VERSION "HNNBNNNYNNNNNNNNNNNNNNNNNNNNNNNNNNNNNNNNNN/4/%%%/4/'%**4NNN///"

NS_ :

BS_:

BU_: BAP_Tester Gateway_Max Getriebe_DQ Motor_konv Parksperre Schaltbetaetigung

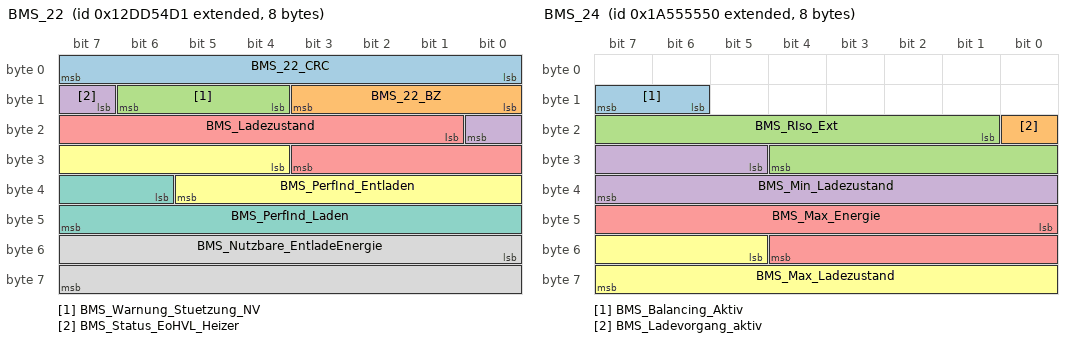
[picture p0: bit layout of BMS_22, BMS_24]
BO_ 2463978705 BMS_22: 8 Gateway_Max
 SG_ BMS_22_CRC : 0|8@1+ (1,0) [0|255] ""  Vector__XXX
 SG_ BMS_22_BZ : 8|4@1+ (1,0) [0|15] ""  Vector__XXX
 SG_ BMS_Warnung_Stuetzung_NV : 12|3@1+ (1.0,0.0) [0.0|7] ""  Vector__XXX
 SG_ BMS_Status_EoHVL_Heizer : 15|2@1+ (1.0,0.0) [0.0|3] ""  Vector__XXX
 SG_ BMS_Ladezustand : 17|11@1+ (0.05,0) [0.00|100.00] "Unit_PerCent"  Vector__XXX
 SG_ BMS_PerfInd_Entladen : 28|10@1+ (0.2,0) [0.0|200.0] "Unit_PerCent"  Vector__XXX
 SG_ BMS_PerfInd_Laden : 38|10@1+ (0.2,0) [0.0|200.0] "Unit_PerCent"  Vector__XXX
 SG_ BMS_Nutzbare_EntladeEnergie : 48|16@1+ (5,0) [0|327400] "Unit_WattHour"  Vector__XXX

BO_ 2589283664 BMS_24: 8 Gateway_Max
 SG_ BMS_Balancing_Aktiv : 14|2@1+ (1.0,0.0) [0.0|3] ""  Vector__XXX
 SG_ BMS_Ladevorgang_aktiv : 16|1@1+ (1.0,0.0) [0.0|1] ""  Vector__XXX
 SG_ BMS_RIso_Ext : 17|12@1+ (5,0) [0|20465] "Unit_KiloOhm"  Vector__XXX
 SG_ BMS_Min_Ladezustand : 29|11@1+ (0.05,0) [0.00|100.00] "Unit_PerCent"  Vector__XXX
 SG_ BMS_Max_Energie : 40|13@1+ (40,0) [0|327400] "Unit_WattHour"  Vector__XXX
 SG_ BMS_Max_Ladezustand : 53|11@1+ (0.05,0) [0.00|100.00] "Unit_PerCent"  Vector__XXX

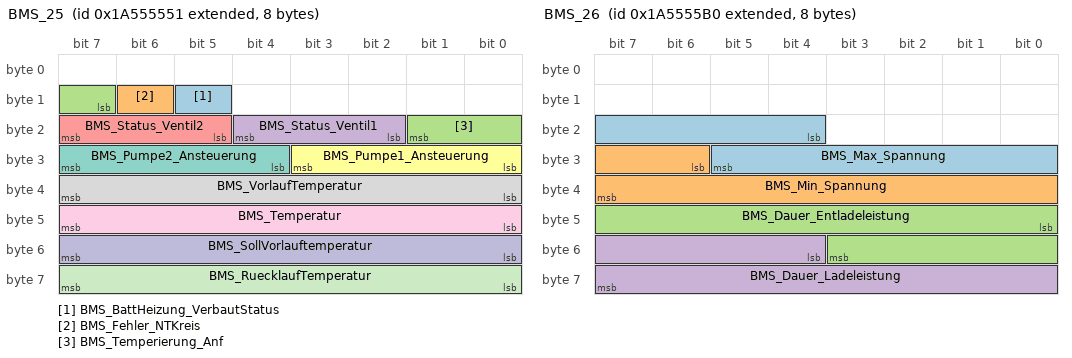
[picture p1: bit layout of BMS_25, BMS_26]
BO_ 2589283665 BMS_25: 8 Gateway_Max
 SG_ BMS_BattHeizung_VerbautStatus : 13|1@1+ (1.0,0.0) [0.0|1] ""  Vector__XXX
 SG_ BMS_Fehler_NTKreis : 14|1@1+ (1.0,0.0) [0.0|1] ""  Vector__XXX
 SG_ BMS_Temperierung_Anf : 15|3@1+ (1.0,0.0) [0.0|7] ""  Vector__XXX
 SG_ BMS_Status_Ventil1 : 18|3@1+ (1.0,0.0) [0.0|7] ""  Vector__XXX
 SG_ BMS_Status_Ventil2 : 21|3@1+ (1.0,0.0) [0.0|7] ""  Vector__XXX
 SG_ BMS_Pumpe1_Ansteuerung : 24|4@1+ (10,0) [0|100] "Unit_PerCent"  Vector__XXX
 SG_ BMS_Pumpe2_Ansteuerung : 28|4@1+ (10,0) [0|100] "Unit_PerCent"  Vector__XXX
 SG_ BMS_VorlaufTemperatur : 32|8@1+ (0.5,-40) [-40.0|86.0] "Unit_DegreCelsi"  Vector__XXX
 SG_ BMS_Temperatur : 40|8@1+ (0.5,-40) [-40.0|86.5] "Unit_DegreCelsi"  Vector__XXX
 SG_ BMS_SollVorlauftemperatur : 48|8@1+ (0.5,-40) [-40.0|86.5] "Unit_DegreCelsi"  Vector__XXX
 SG_ BMS_RuecklaufTemperatur : 56|8@1+ (0.5,-40) [-40.0|86.0] "Unit_DegreCelsi"  Vector__XXX

BO_ 2589283760 BMS_26: 8 Gateway_Max
 SG_ BMS_Max_Spannung : 20|10@1+ (1,0) [0|1000] "Unit_Volt"  Vector__XXX
 SG_ BMS_Min_Spannung : 30|10@1+ (1,0) [0|1000] "Unit_Volt"  Vector__XXX
 SG_ BMS_Dauer_Entladeleistung : 40|12@1+ (200,0) [0|818000] "Unit_Watt"  Vector__XXX
 SG_ BMS_Dauer_Ladeleistung : 52|12@1+ (200,0) [0|818000] "Unit_Watt"  Vector__XXX

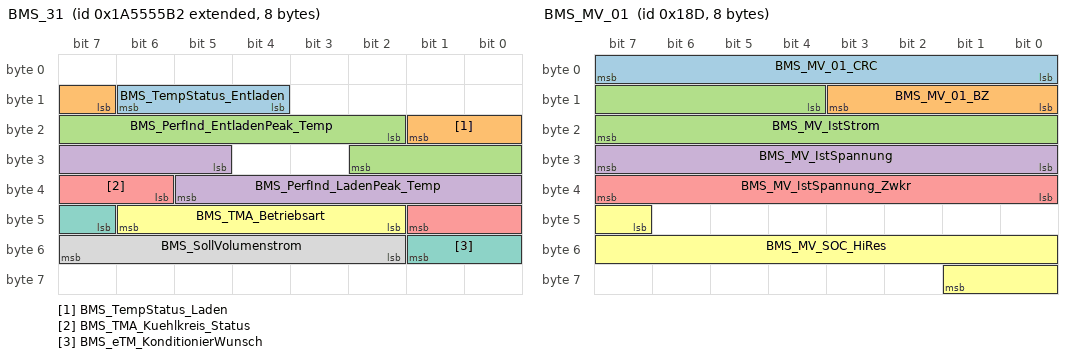
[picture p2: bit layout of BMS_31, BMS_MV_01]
BO_ 2589283762 BMS_31: 8 Gateway_Max
 SG_ BMS_TempStatus_Entladen : 12|3@1+ (1.0,0.0) [0.0|7] ""  Vector__XXX
 SG_ BMS_TempStatus_Laden : 15|3@1+ (1.0,0.0) [0.0|7] ""  Vector__XXX
 SG_ BMS_PerfInd_EntladenPeak_Temp : 18|9@1+ (0.2,0) [0.0|100.0] "Unit_PerCent"  Vector__XXX
 SG_ BMS_PerfInd_LadenPeak_Temp : 29|9@1+ (0.2,0) [0.0|100.0] "Unit_PerCent"  Vector__XXX
 SG_ BMS_TMA_Kuehlkreis_Status : 38|4@1+ (1.0,0.0) [0.0|15] ""  Vector__XXX
 SG_ BMS_TMA_Betriebsart : 42|5@1+ (1.0,0.0) [0.0|31] ""  Vector__XXX
 SG_ BMS_eTM_KonditionierWunsch : 47|3@1+ (1.0,0.0) [0.0|7] ""  Vector__XXX
 SG_ BMS_SollVolumenstrom : 50|6@1+ (1,0) [0|61] "Unit_LiterPerMinut"  Vector__XXX

BO_ 2331595856 BMS_34: 32 Gateway_Max
 SG_ BMS_UBE : 16|16@1+ (5,-7400) [-7400|320000] "Unit_WattHour"  Vector__XXX
 SG_ BMS_UBE_T : 32|16@1+ (5,-7400) [-7400|320000] "Unit_WattHour"  Vector__XXX
 SG_ BMS_Max_UBE : 48|16@1+ (5,-7400) [-7400|320000] "Unit_WattHour"  Vector__XXX
 SG_ BMS_Nennspannung : 64|11@1+ (0.5,0) [0.0|1000.0] "Unit_Volt"  Vector__XXX
 SG_ BMS_DC_Ladeschuetze_Ist : 75|3@1+ (1.0,0.0) [0.0|7] ""  Vector__XXX
 SG_ BMS_Hauptschuetze_Ist : 78|3@1+ (1.0,0.0) [0.0|7] ""  Vector__XXX
 SG_ BMS_UBE_Indikator : 81|11@1+ (0.05,0) [0.00|100.00] "Unit_PerCent"  Vector__XXX
 SG_ BMS_UBE_Indik_last_update_km : 92|20@1+ (1,0) [0|1000000] "Unit_KiloMeter"  Vector__XXX
 SG_ BMS_Last_Chg_adeq_SOCswing_Day : 112|5@1+ (1,0) [1|31] "Unit_Day"  Vector__XXX
 SG_ BMS_Last_Chg_adeq_SOCswing_Month : 117|4@1+ (1,0) [1|12] "Unit_Month"  Vector__XXX
 SG_ BMS_Last_Chg_adeq_SOCswing_Year : 121|7@1+ (1,2000) [2001|2127] "Unit_Year"  Vector__XXX
 SG_ BMS_EnergieVorhalt : 128|16@1+ (0.1,0) [0.0|6400.0] "Unit_KiloWattHour"  Vector__XXX
 SG_ BMS_Range_Indikator : 144|11@1+ (0.05,0) [0.00|100.00] "Unit_PerCent"  Vector__XXX
 SG_ SOK_BMS_34_Signatur : 192|64@1+ (1,0) [1|18446744073709551615] "Unit_None"  Vector__XXX

BO_ 397 BMS_MV_01: 8 Gateway_Max
 SG_ BMS_MV_01_CRC : 0|8@1+ (1,0) [0|255] ""  Vector__XXX
 SG_ BMS_MV_01_BZ : 8|4@1+ (1,0) [0|15] ""  Vector__XXX
 SG_ BMS_MV_IstStrom : 12|12@1+ (1,-2047) [-2047|2046] "Unit_Amper"  Motor_konv
 SG_ BMS_MV_IstSpannung : 24|8@1+ (0.25,0) [0.00|63.25] "Unit_Volt"  Motor_konv
 SG_ BMS_MV_IstSpannung_Zwkr : 32|8@1+ (0.25,0) [0.00|63.25] "Unit_Volt"  Vector__XXX
 SG_ BMS_MV_SOC_HiRes : 47|11@1+ (0.05,0) [0.00|100.00] "Unit_PerCent"  Motor_konv

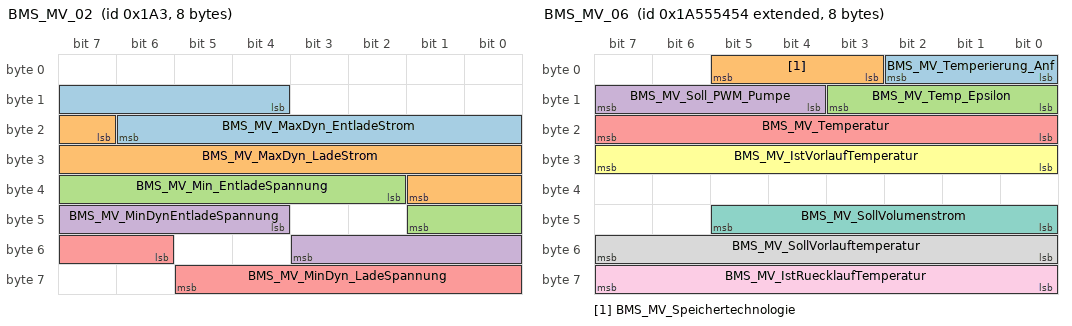
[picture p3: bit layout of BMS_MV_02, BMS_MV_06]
BO_ 419 BMS_MV_02: 8 Gateway_Max
 SG_ BMS_MV_MaxDyn_EntladeStrom : 12|11@1+ (1,0) [0|2045] "Unit_Amper"  Motor_konv
 SG_ BMS_MV_MaxDyn_LadeStrom : 23|11@1+ (1,0) [0|2045] "Unit_Amper"  Motor_konv
 SG_ BMS_MV_Min_EntladeSpannung : 34|8@1+ (0.25,0) [0.00|63.25] "Unit_Volt"  Vector__XXX
 SG_ BMS_MV_MinDynEntladeSpannung : 44|8@1+ (0.25,0) [0.00|63.25] "Unit_Volt"  Vector__XXX
 SG_ BMS_MV_MinDyn_LadeSpannung : 54|8@1+ (0.25,0) [0.00|63.25] "Unit_Volt"  Vector__XXX

BO_ 2589283412 BMS_MV_06: 8 Gateway_Max
 SG_ BMS_MV_Temperierung_Anf : 0|3@1+ (1.0,0.0) [0.0|7] ""  Vector__XXX
 SG_ BMS_MV_Speichertechnologie : 3|3@1+ (1.0,0.0) [0.0|7] ""  Vector__XXX
 SG_ BMS_MV_Temp_Epsilon : 8|4@1+ (1,-15) [-15|0] "Unit_DegreCelsi"  Vector__XXX
 SG_ BMS_MV_Soll_PWM_Pumpe : 12|4@1+ (10,0) [0|100] "Unit_PerCent"  Vector__XXX
 SG_ BMS_MV_Temperatur : 16|8@1+ (0.5,-40) [-40.0|86.5] "Unit_DegreCelsi"  Motor_konv
 SG_ BMS_MV_IstVorlaufTemperatur : 24|8@1+ (0.5,-40) [-40.0|86.5] "Unit_DegreCelsi"  Vector__XXX
 SG_ BMS_MV_SollVolumenstrom : 40|6@1+ (1,0) [0|61] ""  Vector__XXX
 SG_ BMS_MV_SollVorlauftemperatur : 48|8@1+ (0.5,-40) [-40.0|86.5] "Unit_DegreCelsi"  Vector__XXX
 SG_ BMS_MV_IstRuecklaufTemperatur : 56|8@1+ (0.5,-40) [-40.0|86.5] "Unit_DegreCelsi"  Vector__XXX

BO_ 2589283608 BMS_MV_07: 8 Gateway_Max
 SG_ BMS_MV_Energieinhalt : 12|11@1+ (1,0) [0|2045] "Unit_WattHour"  Motor_konv
 SG_ BMS_MV_MaxEnergieinhalt : 32|11@1+ (1,0) [0|2045] "Unit_WattHour"  Motor_konv

BO_ 2589283606 BMS_MV_09: 8 Gateway_Max
 SG_ BMS_MV_SOC_Kaltstart : 43|11@1+ (0.05,0) [0.00|100.00] "Unit_PerCent"  Motor_konv
 SG_ BMS_MV_max_Grenz_SOC : 54|5@1+ (1,70) [70|100] "Unit_PerCent"  Motor_konv

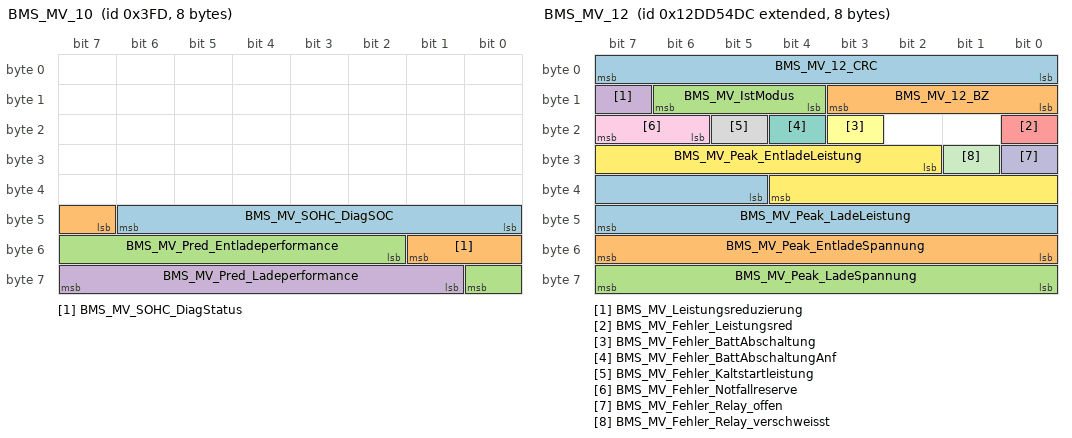
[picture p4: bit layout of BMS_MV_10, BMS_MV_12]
BO_ 1021 BMS_MV_10: 8 Gateway_Max
 SG_ BMS_MV_SOHC_DiagSOC : 40|7@1+ (1,0) [0|100] "Unit_PerCent"  Motor_konv
 SG_ BMS_MV_SOHC_DiagStatus : 47|3@1+ (1.0,0.0) [0.0|7] ""  Motor_konv
 SG_ BMS_MV_Pred_Entladeperformance : 50|7@1+ (1,0) [0|100] "Unit_PerCent"  Motor_konv
 SG_ BMS_MV_Pred_Ladeperformance : 57|7@1+ (1,0) [0|100] "Unit_PerCent"  Motor_konv

BO_ 2463978716 BMS_MV_12: 8 Gateway_Max
 SG_ BMS_MV_12_CRC : 0|8@1+ (1,0) [0|255] ""  Vector__XXX
 SG_ BMS_MV_12_BZ : 8|4@1+ (1,0) [0|15] ""  Vector__XXX
 SG_ BMS_MV_IstModus : 12|3@1+ (1.0,0.0) [0.0|7] ""  Vector__XXX
 SG_ BMS_MV_Leistungsreduzierung : 15|1@1+ (1.0,0.0) [0.0|1] ""  Motor_konv
 SG_ BMS_MV_Fehler_Leistungsred : 16|1@1+ (1.0,0.0) [0.0|1] ""  Motor_konv
 SG_ BMS_MV_Fehler_BattAbschaltung : 19|1@1+ (1.0,0.0) [0.0|1] ""  Vector__XXX
 SG_ BMS_MV_Fehler_BattAbschaltungAnf : 20|1@1+ (1.0,0.0) [0.0|1] ""  Vector__XXX
 SG_ BMS_MV_Fehler_Kaltstartleistung : 21|1@1+ (1.0,0.0) [0.0|1] ""  Vector__XXX
 SG_ BMS_MV_Fehler_Notfallreserve : 22|2@1+ (1.0,0.0) [0.0|3] ""  Vector__XXX
 SG_ BMS_MV_Fehler_Relay_offen : 24|1@1+ (1.0,0.0) [0.0|1] ""  Vector__XXX
 SG_ BMS_MV_Fehler_Relay_verschweisst : 25|1@1+ (1.0,0.0) [0.0|1] ""  Vector__XXX
 SG_ BMS_MV_Peak_EntladeLeistung : 26|11@1+ (50,0) [0|102250] "Unit_Watt"  Vector__XXX
 SG_ BMS_MV_Peak_LadeLeistung : 37|11@1+ (50,0) [0|102250] "Unit_Watt"  Vector__XXX
 SG_ BMS_MV_Peak_EntladeSpannung : 48|8@1+ (0.25,0) [0.00|63.25] "Unit_Volt"  Vector__XXX
 SG_ BMS_MV_Peak_LadeSpannung : 56|8@1+ (0.25,0) [0.00|63.25] "Unit_Volt"  Vector__XXX

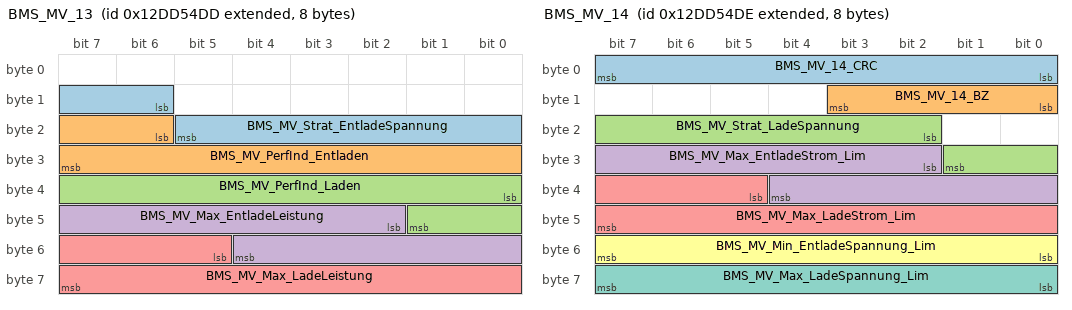
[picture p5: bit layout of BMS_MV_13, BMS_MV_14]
BO_ 2463978717 BMS_MV_13: 8 Gateway_Max
 SG_ BMS_MV_Strat_EntladeSpannung : 14|8@1+ (0.25,0) [0.00|63.25] "Unit_Volt"  Vector__XXX
 SG_ BMS_MV_PerfInd_Entladen : 22|10@1+ (0.2,0) [0.0|200.0] "Unit_PerCent"  Motor_konv
 SG_ BMS_MV_PerfInd_Laden : 32|10@1+ (0.2,0) [0.0|200.0] "Unit_PerCent"  Motor_konv
 SG_ BMS_MV_Max_EntladeLeistung : 42|11@1+ (50,0) [0|102250] "Unit_Watt"  Motor_konv
 SG_ BMS_MV_Max_LadeLeistung : 53|11@1+ (50,0) [0|102250] "Unit_Watt"  Motor_konv

BO_ 2463978718 BMS_MV_14: 8 Gateway_Max
 SG_ BMS_MV_14_CRC : 0|8@1+ (1,0) [0|255] ""  Vector__XXX
 SG_ BMS_MV_14_BZ : 8|4@1+ (1,0) [0|15] ""  Vector__XXX
 SG_ BMS_MV_Strat_LadeSpannung : 18|8@1+ (0.25,0) [0.00|63.25] "Unit_Volt"  Vector__XXX
 SG_ BMS_MV_Max_EntladeStrom_Lim : 26|11@1+ (1,0) [0|2045] "Unit_Amper"  Motor_konv
 SG_ BMS_MV_Max_LadeStrom_Lim : 37|11@1+ (1,0) [0|2045] "Unit_Amper"  Motor_konv
 SG_ BMS_MV_Min_EntladeSpannung_Lim : 48|8@1+ (0.25,0) [0.00|63.25] "Unit_Volt"  Motor_konv
 SG_ BMS_MV_Max_LadeSpannung_Lim : 56|8@1+ (0.25,0) [0.00|63.25] "Unit_Volt"  Motor_konv

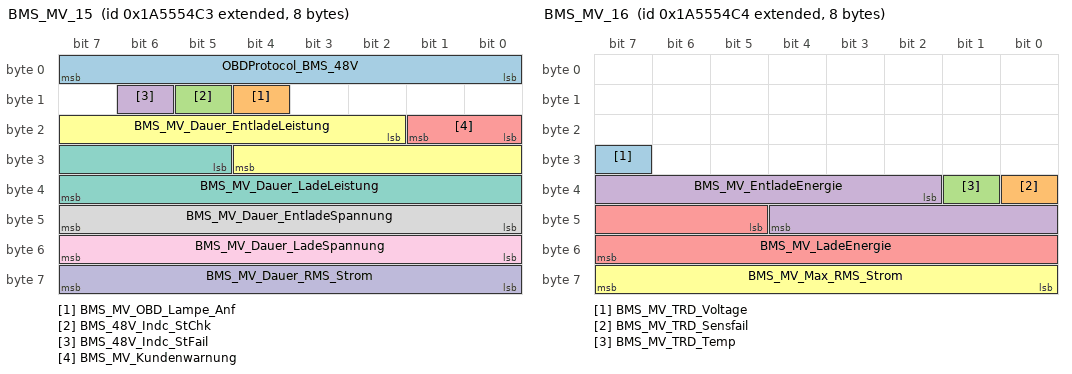
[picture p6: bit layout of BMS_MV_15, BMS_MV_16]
BO_ 2589283523 BMS_MV_15: 8 Gateway_Max
 SG_ OBDProtocol_BMS_48V : 0|8@1+ (1.0,0.0) [0.0|255] ""  Motor_konv
 SG_ BMS_MV_OBD_Lampe_Anf : 12|1@1+ (1.0,0.0) [0.0|1] ""  Motor_konv
 SG_ BMS_48V_Indc_StChk : 13|1@1+ (1.0,0.0) [0.0|1] ""  Motor_konv
 SG_ BMS_48V_Indc_StFail : 14|1@1+ (1.0,0.0) [0.0|1] ""  Motor_konv
 SG_ BMS_MV_Kundenwarnung : 16|2@1+ (1.0,0.0) [0.0|3] ""  Vector__XXX
 SG_ BMS_MV_Dauer_EntladeLeistung : 18|11@1+ (50,0) [0|102250] "Unit_Watt"  Motor_konv
 SG_ BMS_MV_Dauer_LadeLeistung : 29|11@1+ (50,0) [0|102250] "Unit_Watt"  Motor_konv
 SG_ BMS_MV_Dauer_EntladeSpannung : 40|8@1+ (0.25,0) [0.00|63.25] "Unit_Volt"  Vector__XXX
 SG_ BMS_MV_Dauer_LadeSpannung : 48|8@1+ (0.25,0) [0.00|63.25] "Unit_Volt"  Vector__XXX
 SG_ BMS_MV_Dauer_RMS_Strom : 56|8@1+ (1,0) [0|253] "Unit_Amper"  Motor_konv

BO_ 2589283543 BMS_MV_15_SOK_Signatur: 8 Gateway_Max
 SG_ SOK_BMS_MV_15_Signatur : 0|64@1+ (1,0) [1|18446744073709551615] "Unit_None"  Motor_konv

BO_ 2589283524 BMS_MV_16: 8 Gateway_Max
 SG_ BMS_MV_TRD_Voltage : 31|1@1+ (1.0,0.0) [0.0|1] ""  Vector__XXX
 SG_ BMS_MV_TRD_Sensfail : 32|1@1+ (1.0,0.0) [0.0|1] ""  Vector__XXX
 SG_ BMS_MV_TRD_Temp : 33|1@1+ (1.0,0.0) [0.0|1] ""  Vector__XXX
 SG_ BMS_MV_EntladeEnergie : 34|11@1+ (5,-5110) [-5110|5115] "Unit_WattHour"  Motor_konv
 SG_ BMS_MV_LadeEnergie : 45|11@1+ (5,-5110) [-5110|5115] "Unit_WattHour"  Motor_konv
 SG_ BMS_MV_Max_RMS_Strom : 56|8@1+ (1,0) [0|253] "Unit_Amper"  Motor_konv

BO_ 2527679928 BMS_NV_11: 16 Gateway_Max
 SG_ BMS_NV_OBD_Lampe_Anf : 12|1@1+ (1.0,0.0) [0.0|1] ""  Motor_konv
 SG_ BMS_NV_Indc_StChk : 13|1@1+ (1.0,0.0) [0.0|1] ""  Motor_konv
 SG_ BMS_NV_Indc_StFail : 14|1@1+ (1.0,0.0) [0.0|1] ""  Motor_konv
 SG_ OBDProtocol_BMS_NV : 16|8@1+ (1.0,0.0) [0.0|255] ""  Motor_konv
 SG_ SOK_BMS_NV_11_Signatur : 64|64@1+ (1,0) [1|18446744073709551615] "Unit_None"  Motor_konv

BO_ 2463978646 Charisma_11: 24 Gateway_Max
 SG_ CHA_Ziel_FahrPr_AGA : 0|4@1+ (1.0,0.0) [0.0|15] ""  Vector__XXX
 SG_ CHA_Ziel_FahrPr_ESP : 4|4@1+ (1.0,0.0) [0.0|15] ""  Vector__XXX
 SG_ CHA_Ziel_FahrPr_Freilauf : 8|4@1+ (1.0,0.0) [0.0|15] ""  Vector__XXX
 SG_ CHA_Fahrer_Umschaltung : 14|1@1+ (1.0,0.0) [0.0|1] ""  Getriebe_DQ,Motor_konv
 SG_ CHA_Fahrer_Umschaltung_BMA : 15|1@1+ (1.0,0.0) [0.0|1] ""  Vector__XXX
 SG_ CHA_Ziel_FahrPr_MO : 16|4@1+ (1.0,0.0) [0.0|15] ""  Motor_konv
 SG_ CHA_Ziel_FahrPr_GE : 20|4@1+ (1.0,0.0) [0.0|15] ""  Getriebe_DQ
 SG_ CHA_Ziel_FahrPr_ALR : 24|4@1+ (1.0,0.0) [0.0|15] ""  Vector__XXX
 SG_ CHA_Ziel_FahrPr_MO_BZS : 28|4@1+ (1.0,0.0) [0.0|15] ""  Motor_konv
 SG_ CHA_Ziel_FahrPr_DR : 32|4@1+ (1.0,0.0) [0.0|15] ""  Vector__XXX
 SG_ CHA_Ziel_FahrPr_VAQ : 36|4@1+ (1.0,0.0) [0.0|15] ""  Vector__XXX
 SG_ CHA_Ziel_FahrPr_AFS : 40|4@1+ (1.0,0.0) [0.0|15] ""  Vector__XXX
 SG_ CHA_Ziel_FahrPr_PreCrash : 44|4@1+ (1.0,0.0) [0.0|15] ""  Vector__XXX
 SG_ CHA_Ziel_FahrPr_EPS : 48|4@1+ (1.0,0.0) [0.0|15] ""  Vector__XXX
 SG_ CHA_Ziel_FahrPr_ACC : 52|4@1+ (1.0,0.0) [0.0|15] ""  Vector__XXX
 SG_ CHA_Ziel_FahrPr_SAK : 56|4@1+ (1.0,0.0) [0.0|15] ""  Motor_konv
 SG_ CHA_Ziel_FahrPr_MO_StSt : 60|4@1+ (1.0,0.0) [0.0|15] ""  Motor_konv
 SG_ CHA_Ziel_FahrPr_EBKV : 64|4@1+ (1.0,0.0) [0.0|15] ""  Vector__XXX
 SG_ CHA_Ziel_FahrPr_IL : 68|4@1+ (1.0,0.0) [0.0|15] ""  Vector__XXX
 SG_ CHA_Current_Mode : 72|4@1+ (1.0,0.0) [0.0|15] ""  Vector__XXX
 SG_ CHA_Ziel_FahrPr_QS : 80|4@1+ (1.0,0.0) [0.0|15] ""  Vector__XXX
 SG_ CHA_Ziel_FahrPr_SCU : 84|4@1+ (1.0,0.0) [0.0|15] ""  Vector__XXX
 SG_ CHA_Ziel_FahrPr_HAL : 88|4@1+ (1.0,0.0) [0.0|15] ""  Vector__XXX
 SG_ CHA_Ziel_FahrPr_NR : 92|4@1+ (1.0,0.0) [0.0|15] ""  Vector__XXX
 SG_ CHA_Ziel_FahrPr_AV : 96|4@1+ (1.0,0.0) [0.0|15] ""  Vector__XXX
 SG_ CHA_Ziel_FahrPr_MXB : 100|4@1+ (1.0,0.0) [0.0|15] ""  Vector__XXX
 SG_ CHA_Ziel_FahrPr_AFR : 104|4@1+ (1.0,0.0) [0.0|15] ""  Vector__XXX
 SG_ CHA_Ziel_FahrPr_HDC : 108|4@1+ (1.0,0.0) [0.0|15] ""  Vector__XXX
 SG_ CHA_Ziel_FahrPr_EAR : 112|4@1+ (1.0,0.0) [0.0|15] ""  Vector__XXX
 SG_ CHA_Ziel_FahrPr_AEB : 116|4@1+ (1.0,0.0) [0.0|15] ""  Vector__XXX
 SG_ CHA_Ziel_FahrPr_FCWO : 120|4@1+ (1.0,0.0) [0.0|15] ""  Vector__XXX
 SG_ CHA_Ziel_FahrPr_FCWP : 124|4@1+ (1.0,0.0) [0.0|15] ""  Vector__XXX
 SG_ CHA_Ziel_FahrPr_eSound : 136|4@1+ (1.0,0.0) [0.0|15] ""  Vector__XXX
 SG_ CHA_Ziel_FahrPr_RHP : 140|4@1+ (1.0,0.0) [0.0|15] ""  Vector__XXX
 SG_ CHA_Ziel_FahrPr_ToS_laengs : 144|4@1+ (1.0,0.0) [0.0|15] ""  Vector__XXX
 SG_ CHA_Ziel_FahrPr_ToS_quer : 148|4@1+ (1.0,0.0) [0.0|15] ""  Vector__XXX
 SG_ CHA_Ziel_FahrPr_mFDR : 152|4@1+ (1.0,0.0) [0.0|15] ""  Vector__XXX
 SG_ CHA_Ziel_FahrPr_Reku_ZwGas : 156|4@1+ (1.0,0.0) [0.0|15] ""  Vector__XXX
 SG_ CHA_Ziel_FahrPr_MO_Freilauf : 160|4@1+ (1.0,0.0) [0.0|15] ""  Vector__XXX
 SG_ CHA_Ziel_FahrPr_BMS : 164|4@1+ (1.0,0.0) [0.0|15] ""  Vector__XXX
 SG_ CHA_Ziel_FahrPr_PDC : 172|4@1+ (1.0,0.0) [0.0|15] ""  Vector__XXX
 SG_ CHA_Ziel_FahrPr_HHC : 176|4@1+ (1.0,0.0) [0.0|15] ""  Vector__XXX
 SG_ CHA_Ziel_FahrPr_EDS : 180|4@1+ (1.0,0.0) [0.0|15] ""  Vector__XXX
 SG_ CHA_Ziel_FahrPr_PACC : 184|4@1+ (1.0,0.0) [0.0|15] ""  Vector__XXX
 SG_ CHA_Ziel_FahrPr_AGK : 188|4@1+ (1.0,0.0) [0.0|15] ""  Motor_konv

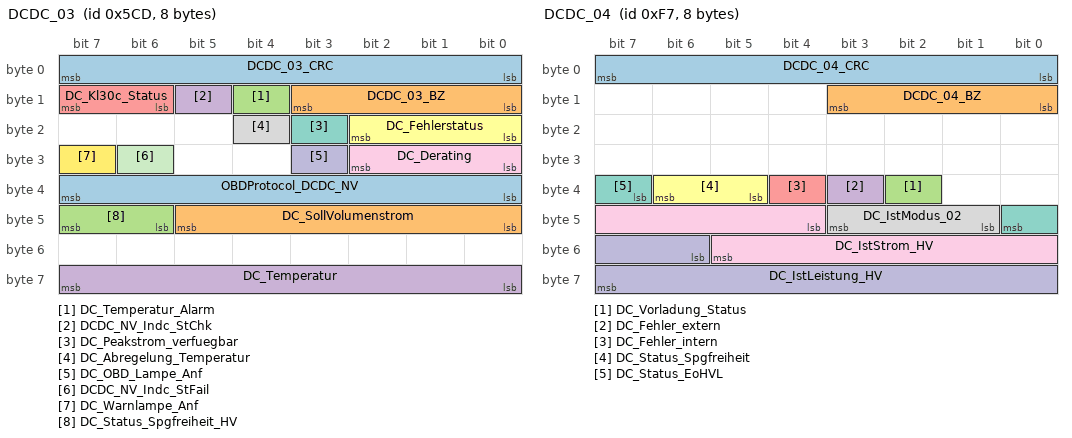
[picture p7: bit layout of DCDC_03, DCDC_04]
BO_ 1485 DCDC_03: 8 Gateway_Max
 SG_ DCDC_03_CRC : 0|8@1+ (1,0) [0|255] ""  Vector__XXX
 SG_ DCDC_03_BZ : 8|4@1+ (1,0) [0|15] ""  Vector__XXX
 SG_ DC_Temperatur_Alarm : 12|1@1+ (1.0,0.0) [0.0|1] ""  Vector__XXX
 SG_ DCDC_NV_Indc_StChk : 13|1@1+ (1.0,0.0) [0.0|1] ""  Vector__XXX
 SG_ DC_Kl30c_Status : 14|2@1+ (1.0,0.0) [0.0|3] ""  Vector__XXX
 SG_ DC_Fehlerstatus : 16|3@1+ (1.0,0.0) [0.0|7] ""  Vector__XXX
 SG_ DC_Peakstrom_verfuegbar : 19|1@1+ (1.0,0.0) [0.0|1] ""  Vector__XXX
 SG_ DC_Abregelung_Temperatur : 20|1@1+ (1.0,0.0) [0.0|1] ""  Vector__XXX
 SG_ DC_Derating : 24|3@1+ (1.0,0.0) [0.0|7] ""  Vector__XXX
 SG_ DC_OBD_Lampe_Anf : 27|1@1+ (1.0,0.0) [0.0|1] ""  Vector__XXX
 SG_ DCDC_NV_Indc_StFail : 30|1@1+ (1.0,0.0) [0.0|1] ""  Vector__XXX
 SG_ DC_Warnlampe_Anf : 31|1@1+ (1.0,0.0) [0.0|1] ""  Vector__XXX
 SG_ OBDProtocol_DCDC_NV : 32|8@1+ (1.0,0.0) [0.0|255] ""  Vector__XXX
 SG_ DC_SollVolumenstrom : 40|6@1+ (0.5,0) [0.0|30.5] "Unit_LiterPerMinut"  Vector__XXX
 SG_ DC_Status_Spgfreiheit_HV : 46|2@1+ (1.0,0.0) [0.0|3] ""  Vector__XXX
 SG_ DC_Temperatur : 56|8@1+ (1,-40) [-40|213] "Unit_DegreCelsi"  Vector__XXX

BO_ 1486 DCDC_03_SOK_Signatur: 8 Gateway_Max
 SG_ SOK_DCDC_03_Signatur : 0|64@1+ (1,0) [1|18446744073709551615] "Unit_None"  Vector__XXX

BO_ 247 DCDC_04: 8 Gateway_Max
 SG_ DCDC_04_CRC : 0|8@1+ (1,0) [0|255] ""  Vector__XXX
 SG_ DCDC_04_BZ : 8|4@1+ (1,0) [0|15] ""  Vector__XXX
 SG_ DC_Vorladung_Status : 34|1@1+ (1.0,0.0) [0.0|1] ""  Vector__XXX
 SG_ DC_Fehler_extern : 35|1@1+ (1.0,0.0) [0.0|1] ""  Vector__XXX
 SG_ DC_Fehler_intern : 36|1@1+ (1.0,0.0) [0.0|1] ""  Vector__XXX
 SG_ DC_Status_Spgfreiheit : 37|2@1+ (1.0,0.0) [0.0|3] ""  Vector__XXX
 SG_ DC_Status_EoHVL : 39|2@1+ (1.0,0.0) [0.0|3] ""  Vector__XXX
 SG_ DC_IstModus_02 : 41|3@1+ (1.0,0.0) [0.0|7] ""  Vector__XXX
 SG_ DC_IstStrom_HV : 44|10@1+ (0.1,-51.1) [-51.1|51.0] "Unit_Amper"  Vector__XXX
 SG_ DC_IstLeistung_HV : 54|10@1+ (10,-4000) [-4000|6210] "Unit_Watt"  Vector__XXX

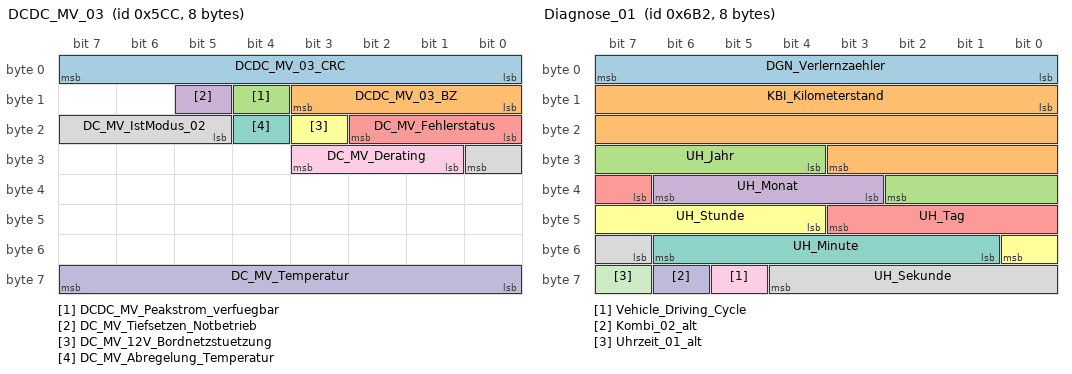
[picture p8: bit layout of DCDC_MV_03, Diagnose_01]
BO_ 1484 DCDC_MV_03: 8 Gateway_Max
 SG_ DCDC_MV_03_CRC : 0|8@1+ (1,0) [0|255] ""  Vector__XXX
 SG_ DCDC_MV_03_BZ : 8|4@1+ (1,0) [0|15] ""  Vector__XXX
 SG_ DCDC_MV_Peakstrom_verfuegbar : 12|1@1+ (1.0,0.0) [0.0|1] ""  Vector__XXX
 SG_ DC_MV_Tiefsetzen_Notbetrieb : 13|1@1+ (1.0,0.0) [0.0|1] ""  Vector__XXX
 SG_ DC_MV_Fehlerstatus : 16|3@1+ (1.0,0.0) [0.0|7] ""  Vector__XXX
 SG_ DC_MV_12V_Bordnetzstuetzung : 19|1@1+ (1.0,0.0) [0.0|1] ""  Vector__XXX
 SG_ DC_MV_Abregelung_Temperatur : 20|1@1+ (1.0,0.0) [0.0|1] ""  Vector__XXX
 SG_ DC_MV_IstModus_02 : 21|4@1+ (1.0,0.0) [0.0|15] ""  Motor_konv
 SG_ DC_MV_Derating : 25|3@1+ (1.0,0.0) [0.0|7] ""  Vector__XXX
 SG_ DC_MV_Temperatur : 56|8@1+ (1,-40) [-40|213] "Unit_DegreCelsi"  Vector__XXX

BO_ 2617227808 DEV_Getriebe_Resp_20: 64 Getriebe_DQ
 SG_ DEV_Getriebe_Resp_20_Data : 0|512@1+ (1.0,0.0) [0.0|13407807929942597099574024998205846127479365820592393377723561443721764030073546976801874298166903427690031858186486050853753882811946569946433649006084095] ""  Vector__XXX

BO_ 2617227809 DEV_Getriebe_Resp_21: 64 Getriebe_DQ
 SG_ DEV_Getriebe_Resp_21_Data : 0|512@1+ (1.0,0.0) [0.0|13407807929942597099574024998205846127479365820592393377723561443721764030073546976801874298166903427690031858186486050853753882811946569946433649006084095] ""  Vector__XXX

BO_ 2566865408 DEV_Parksperre_Resp_00: 8 Parksperre
 SG_ DEV_Parksperre_Resp_00_Data : 0|64@1+ (1.0,0.0) [0.0|18446744073709551615] ""  Vector__XXX

BO_ 2566865663 DEV_Parksperre_Resp_FF: 8 Parksperre
 SG_ DEV_Parksperre_Resp_FF_Data : 0|64@1+ (1.0,0.0) [0.0|18446744073709551615] ""  Vector__XXX

BO_ 2617154048 DEV_Waehlhebel_Resp_00: 8 Schaltbetaetigung
 SG_ DEV_Waehlhebel_Resp_00_Data : 0|64@1+ (1.0,0.0) [0.0|18446744073709551615] ""  Vector__XXX

BO_ 2617154049 DEV_Waehlhebel_Resp_01: 8 Schaltbetaetigung
 SG_ DEV_Waehlhebel_Resp_01_Data : 0|64@1+ (1.0,0.0) [0.0|18446744073709551615] ""  Vector__XXX

BO_ 2617154050 DEV_Waehlhebel_Resp_02: 8 Schaltbetaetigung
 SG_ DEV_Waehlhebel_Resp_02_Data : 0|64@1+ (1.0,0.0) [0.0|18446744073709551615] ""  Vector__XXX

BO_ 2617154051 DEV_Waehlhebel_Resp_03: 8 Schaltbetaetigung
 SG_ DEV_Waehlhebel_Resp_03_Data : 0|64@1+ (1.0,0.0) [0.0|18446744073709551615] ""  Vector__XXX

BO_ 2617154052 DEV_Waehlhebel_Resp_04: 8 Schaltbetaetigung
 SG_ DEV_Waehlhebel_Resp_04_Data : 0|64@1+ (1.0,0.0) [0.0|18446744073709551615] ""  Vector__XXX

BO_ 2617154053 DEV_Waehlhebel_Resp_05: 8 Schaltbetaetigung
 SG_ DEV_Waehlhebel_Resp_05_Data : 0|64@1+ (1.0,0.0) [0.0|18446744073709551615] ""  Vector__XXX

BO_ 2549880589 DIA_eBooster_Req: 8 Gateway_Max
 SG_ DIA_eBooster_Req_Data : 0|64@1+ (1.0,0.0) [0.0|18446744073709551615] ""  Vector__XXX

BO_ 2550011661 DIA_eBooster_Resp: 8 Vector__XXX
 SG_ DIA_eBooster_Resp_Data : 0|64@1+ (1.0,0.0) [0.0|18446744073709551615] ""  Gateway_Max

BO_ 2549880644 DIA_EKAT_Req: 8 Gateway_Max
 SG_ DIA_EKAT_Req_Data : 0|64@1+ (1.0,0.0) [0.0|18446744073709551615] ""  Vector__XXX

BO_ 2550011716 DIA_EKAT_Resp: 8 Vector__XXX
 SG_ DIA_EKAT_Resp_Data : 0|64@1+ (1.0,0.0) [0.0|18446744073709551615] ""  Gateway_Max

BO_ 2549880568 DIA_MTFP_Req: 8 Gateway_Max
 SG_ DIA_MTFP_Req_Data : 0|64@1+ (1.0,0.0) [0.0|18446744073709551615] ""  Vector__XXX

BO_ 2550011640 DIA_MTFP_Resp: 8 Vector__XXX
 SG_ DIA_MTFP_Resp_Data : 0|64@1+ (1.0,0.0) [0.0|18446744073709551615] ""  Gateway_Max

BO_ 2549880642 DIA_Parksperre_Req: 8 Gateway_Max
 SG_ DIA_Parksperre_Req_Data : 0|64@1+ (1.0,0.0) [0.0|18446744073709551615] ""  Parksperre

BO_ 2621445954 DIA_Parksperre_Req_FD: 64 Gateway_Max
 SG_ DIA_Parksperre_Req_FD_Data : 0|512@1+ (1.0,0.0) [0.0|13407807929942597099574024998205846127479365820592393377723561443721764030073546976801874298166903427690031858186486050853753882811946569946433649006084095] ""  Parksperre

BO_ 2550011714 DIA_Parksperre_Resp: 8 Parksperre
 SG_ DIA_Parksperre_Resp_Data : 0|64@1+ (1.0,0.0) [0.0|18446744073709551615] ""  Gateway_Max

BO_ 2621577026 DIA_Parksperre_Resp_FD: 64 Parksperre
 SG_ DIA_Parksperre_Resp_FD_Data : 0|512@1+ (1.0,0.0) [0.0|13407807929942597099574024998205846127479365820592393377723561443721764030073546976801874298166903427690031858186486050853753882811946569946433649006084095] ""  Gateway_Max

BO_ 2549876546 Diag_Parksperre_Req: 8 Getriebe_DQ
 SG_ Diag_Parksperre_Req_Data : 0|64@1+ (1.0,0.0) [0.0|18446744073709551615] ""  Parksperre

BO_ 2550007618 Diag_Parksperre_Resp: 8 Parksperre
 SG_ Diag_Parksperre_Resp_Data : 0|64@1+ (1.0,0.0) [0.0|18446744073709551615] ""  Getriebe_DQ

BO_ 2549876269 Diag_Waehlhebel_Req: 8 Getriebe_DQ
 SG_ Diag_Waehlhebel_Req_Data : 0|64@1+ (1.0,0.0) [0.0|18446744073709551615] ""  Schaltbetaetigung

BO_ 2550007341 Diag_Waehlhebel_Resp: 8 Schaltbetaetigung
 SG_ Diag_Waehlhebel_Resp_Data : 0|64@1+ (1.0,0.0) [0.0|18446744073709551615] ""  Getriebe_DQ

BO_ 1714 Diagnose_01: 8 Gateway_Max
 SG_ DGN_Verlernzaehler : 0|8@1+ (1,0) [0|254] ""  Getriebe_DQ
 SG_ KBI_Kilometerstand : 8|20@1+ (1,0) [0|1048573] "Unit_KiloMeter"  Getriebe_DQ,Motor_konv
 SG_ UH_Jahr : 28|7@1+ (1,2000) [2000|2127] "Unit_Year"  Getriebe_DQ,Motor_konv
 SG_ UH_Monat : 35|4@1+ (1,0) [1|12] "Unit_Month"  Getriebe_DQ,Motor_konv
 SG_ UH_Tag : 39|5@1+ (1,0) [1|31] "Unit_Day"  Getriebe_DQ,Motor_konv
 SG_ UH_Stunde : 44|5@1+ (1,0) [0|23] "Unit_Hours"  Getriebe_DQ,Motor_konv
 SG_ UH_Minute : 49|6@1+ (1,0) [0|59] "Unit_Minut"  Getriebe_DQ,Motor_konv
 SG_ UH_Sekunde : 55|6@1+ (1,0) [0|59] "Unit_Secon"  Getriebe_DQ,Motor_konv
 SG_ Vehicle_Driving_Cycle : 61|1@1+ (1.0,0.0) [0.0|1] ""  Vector__XXX
 SG_ Kombi_02_alt : 62|1@1+ (1.0,0.0) [0.0|1] ""  Vector__XXX
 SG_ Uhrzeit_01_alt : 63|1@1+ (1.0,0.0) [0.0|1] ""  Vector__XXX

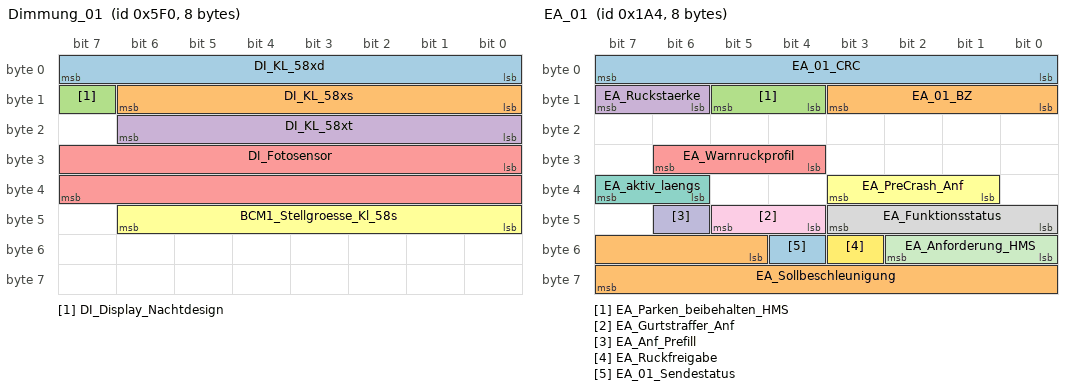
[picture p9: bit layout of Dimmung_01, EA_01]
BO_ 1520 Dimmung_01: 8 Gateway_Max
 SG_ DI_KL_58xd : 0|8@1+ (1,0) [0|253] ""  Schaltbetaetigung
 SG_ DI_KL_58xs : 8|7@1+ (1,0) [0|100] "Unit_PerCent"  Vector__XXX
 SG_ DI_Display_Nachtdesign : 15|1@1+ (1.0,0.0) [0.0|1] ""  Vector__XXX
 SG_ DI_KL_58xt : 16|7@1+ (1,0) [0|100] "Unit_PerCent"  Schaltbetaetigung
 SG_ DI_Fotosensor : 24|16@1+ (1,0) [0|65535] ""  Vector__XXX
 SG_ BCM1_Stellgroesse_Kl_58s : 40|7@1+ (1,0) [0|100] ""  Vector__XXX

BO_ 420 EA_01: 8 Gateway_Max
 SG_ EA_01_CRC : 0|8@1+ (1,0) [0|255] ""  Motor_konv
 SG_ EA_01_BZ : 8|4@1+ (1,0) [0|15] ""  Motor_konv
 SG_ EA_Parken_beibehalten_HMS : 12|2@1+ (1.0,0.0) [0.0|3] ""  Vector__XXX
 SG_ EA_Ruckstaerke : 14|2@1+ (1.0,0.0) [0.0|3] ""  Vector__XXX
 SG_ EA_Warnruckprofil : 28|3@1+ (1.0,0.0) [0.0|7] ""  Vector__XXX
 SG_ EA_PreCrash_Anf : 33|3@1+ (1.0,0.0) [0.0|7] ""  Vector__XXX
 SG_ EA_aktiv_laengs : 38|2@1+ (1.0,0.0) [0.0|3] ""  Motor_konv
 SG_ EA_Funktionsstatus : 40|4@1+ (1.0,0.0) [0.0|15] ""  Motor_konv
 SG_ EA_Gurtstraffer_Anf : 44|2@1+ (1.0,0.0) [0.0|3] ""  Vector__XXX
 SG_ EA_Anf_Prefill : 46|1@1+ (1.0,0.0) [0.0|1] ""  Vector__XXX
 SG_ EA_Anforderung_HMS : 48|3@1+ (1.0,0.0) [0.0|7] ""  Vector__XXX
 SG_ EA_Ruckfreigabe : 51|1@1+ (1.0,0.0) [0.0|1] ""  Vector__XXX
 SG_ EA_01_Sendestatus : 52|1@1+ (1.0,0.0) [0.0|1] ""  Vector__XXX
 SG_ EA_Sollbeschleunigung : 53|11@1+ (0.005,-7.22) [-7.220|3.005] "Unit_MeterPerSeconSquar"  Motor_konv

BO_ 374 EBKV_03: 12 Gateway_Max
 SG_ EBKV_03_CRC : 0|8@1+ (1,0) [0|255] ""  Motor_konv
 SG_ EBKV_03_BZ : 8|4@1+ (1,0) [0|15] ""  Motor_konv
 SG_ EBKV_Activate_Fallback_ESP : 12|1@1+ (1.0,0.0) [0.0|1] ""  Vector__XXX
 SG_ EBKV_Restdruckabsenkung : 13|3@1+ (1.0,0.0) [0.0|7] ""  Vector__XXX
 SG_ EBKV_Status_02 : 16|4@1+ (1.0,0.0) [0.0|15] ""  Motor_konv
 SG_ EBKV_Diagnose : 20|1@1+ (1.0,0.0) [0.0|1] ""  Vector__XXX
 SG_ EBKV_Fahrer_bremst : 21|1@1+ (1.0,0.0) [0.0|1] ""  Motor_konv
 SG_ EBKV_QBit_Fahrer_bremst : 22|1@1+ (1.0,0.0) [0.0|1] ""  Motor_konv
 SG_ EBKV_Fahrer_bremst_deutlich : 23|1@1+ (1.0,0.0) [0.0|1] ""  Vector__XXX
 SG_ EBKV_OBD_Status : 24|1@1+ (1.0,0.0) [0.0|1] ""  Motor_konv
 SG_ EBKV_VMM_Sek_Notstopp_Status : 25|3@1+ (1.0,0.0) [0.0|7] ""  Vector__XXX
 SG_ EBKV_Anforderung_HMS : 28|3@1+ (1.0,0.0) [0.0|7] ""  Vector__XXX
 SG_ SBS_Anforderung_GE : 31|1@1+ (1.0,0.0) [0.0|1] ""  Getriebe_DQ
 SG_ EPB_Status_ext : 32|3@1+ (1.0,0.0) [0.0|7] ""  Vector__XXX
 SG_ EBKV_Textanzeigen : 35|2@1+ (1.0,0.0) [0.0|3] ""  Vector__XXX
 SG_ EBKV_Bremspedalweg : 40|8@1+ (0.4,-0.4) [0.0|101.2] "Unit_PerCent"  Motor_konv
 SG_ EBKV_Kraftblending_Reserve : 48|8@1+ (0.5,0) [0.0|125.0] "Unit_Bar"  Vector__XXX
 SG_ EBKV_Aussteuerdruck : 56|8@1+ (1,0) [0|250] "Unit_Bar"  Vector__XXX
 SG_ SOK_EBKV_03_Signatur : 64|32@1+ (1,0) [0|4294967295] ""  Vector__XXX

BO_ 2589283963 EBKV_05: 16 Gateway_Max
 SG_ EBKV_OBD_Status_Auth : 12|1@1+ (1.0,0.0) [0.0|1] ""  Motor_konv
 SG_ EBKV_Indc_StChk : 13|1@1+ (1.0,0.0) [0.0|1] ""  Motor_konv
 SG_ EBKV_Indc_StFail : 14|1@1+ (1.0,0.0) [0.0|1] ""  Motor_konv
 SG_ OBDProtocol_EBKV : 16|8@1+ (1.0,0.0) [0.0|255] ""  Motor_konv
 SG_ SOK_EBKV_05_Signatur : 64|64@1+ (1,0) [1|18446744073709551615] "Unit_None"  Motor_konv

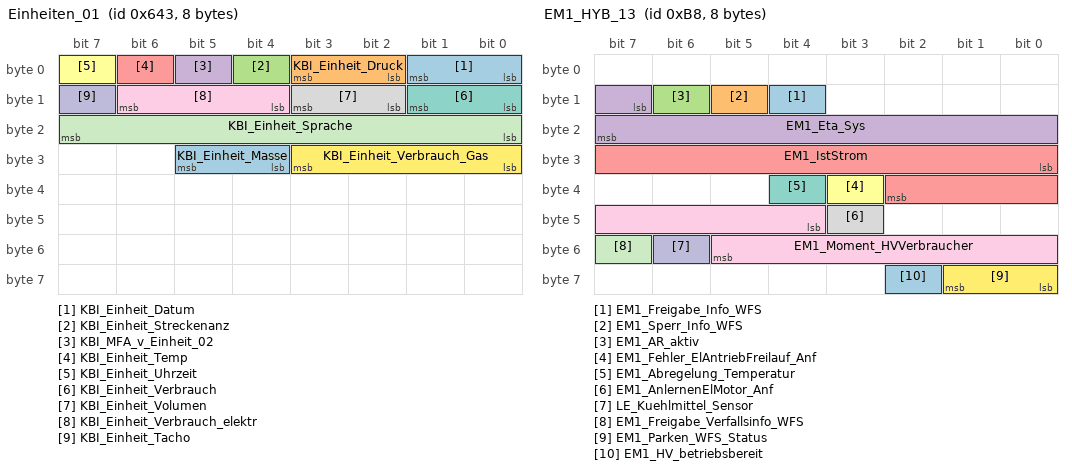
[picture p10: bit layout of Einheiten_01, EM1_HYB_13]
BO_ 1603 Einheiten_01: 8 Gateway_Max
 SG_ KBI_Einheit_Datum : 0|2@1+ (1.0,0.0) [0.0|3] ""  Vector__XXX
 SG_ KBI_Einheit_Druck : 2|2@1+ (1.0,0.0) [0.0|3] ""  Vector__XXX
 SG_ KBI_Einheit_Streckenanz : 4|1@1+ (1.0,0.0) [0.0|1] ""  Motor_konv
 SG_ KBI_MFA_v_Einheit_02 : 5|1@1+ (1.0,0.0) [0.0|1] ""  Vector__XXX
 SG_ KBI_Einheit_Temp : 6|1@1+ (1.0,0.0) [0.0|1] ""  Vector__XXX
 SG_ KBI_Einheit_Uhrzeit : 7|1@1+ (1.0,0.0) [0.0|1] ""  Vector__XXX
 SG_ KBI_Einheit_Verbrauch : 8|2@1+ (1.0,0.0) [0.0|3] ""  Vector__XXX
 SG_ KBI_Einheit_Volumen : 10|2@1+ (1.0,0.0) [0.0|3] ""  Motor_konv
 SG_ KBI_Einheit_Verbrauch_elektr : 12|3@1+ (1.0,0.0) [0.0|7] ""  Vector__XXX
 SG_ KBI_Einheit_Tacho : 15|1@1+ (1.0,0.0) [0.0|1] ""  Motor_konv
 SG_ KBI_Einheit_Sprache : 16|8@1+ (1,0) [0|255] ""  Vector__XXX
 SG_ KBI_Einheit_Verbrauch_Gas : 24|4@1+ (1.0,0.0) [0.0|15] ""  Vector__XXX
 SG_ KBI_Einheit_Masse : 28|2@1+ (1.0,0.0) [0.0|3] ""  Vector__XXX

BO_ 192 EM1_01: 32 Vector__XXX
 SG_ EM1_01_CRC : 0|8@1+ (1,0) [0|255] ""  Gateway_Max
 SG_ EM1_01_BZ : 8|4@1+ (1,0) [0|15] ""  Gateway_Max
 SG_ EM1_Istmodus : 12|4@1+ (1.0,0.0) [0.0|15] ""  Gateway_Max
 SG_ EM1_IstMoment : 16|12@1+ (0.5,-1023) [-1023.0|1023.5] "Unit_NewtoMeter"  Gateway_Max
 SG_ EM1_Moment_AR_Eingriff : 28|12@1+ (0.5,-1023) [-1023.0|1023.5] "Unit_NewtoMeter"  Gateway_Max
 SG_ EM1_IstDrehzahl : 40|15@1+ (1,-10000) [-10000|22765] "Unit_MinutInver"  Gateway_Max
 SG_ EM1_AR_aktiv : 55|1@1+ (1.0,0.0) [0.0|1] ""  Gateway_Max
 SG_ EM1_IstSpannung : 56|12@1+ (0.25,0) [0.00|1023.25] "Unit_Volt"  Gateway_Max
 SG_ EM1_Strom_HV : 68|12@1+ (0.5,-1023) [-1023.0|1023.5] "Unit_Amper"  Gateway_Max
 SG_ EM1_Max_Moment : 80|11@1+ (1,-1023) [-1023|1022] "Unit_NewtoMeter"  Gateway_Max
 SG_ EM1_ErwGrenzen_aktiv : 91|1@1+ (1.0,0.0) [0.0|1] ""  Gateway_Max
 SG_ EM1_Min_Moment : 92|11@1+ (1,-1023) [-1023|1022] "Unit_NewtoMeter"  Gateway_Max
 SG_ EM1_Fehler_ElAntriebAbschaltung : 103|1@1+ (1.0,0.0) [0.0|1] ""  Gateway_Max
 SG_ EM1_Max_Moment_Lim : 104|11@1+ (1,-1023) [-1023|1022] "Unit_NewtoMeter"  Gateway_Max
 SG_ EM1_Fehler_Notabschaltung : 115|1@1+ (1.0,0.0) [0.0|1] ""  Gateway_Max
 SG_ EM1_Min_Moment_Lim : 116|11@1+ (1,-1023) [-1023|1022] "Unit_NewtoMeter"  Gateway_Max
 SG_ EM1_Status_DrzEingriff : 127|2@1+ (1.0,0.0) [0.0|3] ""  Gateway_Max
 SG_ EM1_Mom_DrzEingriff : 129|11@1+ (1,-1023) [-1023|1022] "Unit_NewtoMeter"  Gateway_Max
 SG_ EM1_Raddrehzahl_links : 140|13@1+ (0.3,0) [0.0|2456.1] "Unit_MinutInver"  Gateway_Max
 SG_ EM1_Raddrehzahl_rechts : 153|13@1+ (0.3,0) [0.0|2456.1] "Unit_MinutInver"  Gateway_Max
 SG_ EM1_Max_Moment_Gesamt : 166|11@1+ (1,-1023) [-1023|1022] "Unit_NewtoMeter"  Gateway_Max
 SG_ EM1_Min_Moment_Gesamt : 177|11@1+ (1,-1023) [-1023|1022] "Unit_NewtoMeter"  Gateway_Max

BO_ 184 EM1_HYB_13: 8 Vector__XXX
 SG_ EM1_Freigabe_Info_WFS : 12|1@1+ (1.0,0.0) [0.0|1] ""  Gateway_Max
 SG_ EM1_Sperr_Info_WFS : 13|1@1+ (1.0,0.0) [0.0|1] ""  Gateway_Max
 SG_ EM1_AR_aktiv : 14|1@1+ (1.0,0.0) [0.0|1] ""  Gateway_Max
 SG_ EM1_Eta_Sys : 15|9@1+ (0.2,0) [0.0|101.8] "Unit_PerCent"  Gateway_Max
 SG_ EM1_IstStrom : 24|11@1+ (1,-1023) [-1023|1022] "Unit_Amper"  Gateway_Max
 SG_ EM1_Fehler_ElAntriebFreilauf_Anf : 35|1@1+ (1.0,0.0) [0.0|1] ""  Gateway_Max
 SG_ EM1_Abregelung_Temperatur : 36|1@1+ (1.0,0.0) [0.0|1] ""  Gateway_Max
 SG_ EM1_AnlernenElMotor_Anf : 43|1@1+ (1.0,0.0) [0.0|1] ""  Gateway_Max
 SG_ EM1_Moment_HVVerbraucher : 44|10@1+ (1,-511) [-511|511] "Unit_NewtoMeter"  Gateway_Max
 SG_ LE_Kuehlmittel_Sensor : 54|1@1+ (1.0,0.0) [0.0|1] ""  Gateway_Max
 SG_ EM1_Freigabe_Verfallsinfo_WFS : 55|1@1+ (1.0,0.0) [0.0|1] ""  Gateway_Max
 SG_ EM1_Parken_WFS_Status : 56|2@1+ (1.0,0.0) [0.0|3] ""  Gateway_Max
 SG_ EM1_HV_betriebsbereit : 58|1@1+ (1.0,0.0) [0.0|1] ""  Gateway_Max

CM_ BO_ 2463978646 "ab MQB ohne CHK und mit geänderter Sendeart";
CM_ BO_ 1520 "ab MQB nach abgestimmten FLH Dimmung";
CM_ BO_ 1603 "ab MQB mit 8 Byte";

CM_ SG_ 2463978705 BMS_22_BZ "4bit Botschaftszähler, wird mit jeder Sendebotschaft inkrementiert";
CM_ SG_ 2463978705 BMS_22_CRC "Für MLB:
Berechnung siehe Lastenheft 'Kommunikationsabsicherung für FlexRay und CAN'
Ab MQB und MLBevo:
Berechnung siehe Lastenheft 'End-to-End Kommunikationsabsicherung'

Endwerte siehe Begleitdokument 'S-PDU Kennungsfolgen'";
CM_ SG_ 2463978705 BMS_Ladezustand "Aktueller Ladezustand (SOC) der Batterie. 
Es handelt sich NICHT um den dem Fahrer angezeigten Füllstand der Batterie, sondern um den technisch ermittelten, batterie-internen Ladezustand, bezogen auf die Brutto-Kapazität der Batterie.";
CM_ SG_ 2463978705 BMS_Nutzbare_EntladeEnergie "Aktuelle, verbleibende Energiemenge, die noch aus der Batterie entladen werden kann.
Diese hängt in erster Linie vom aktuellen Ladezustand der Batterie ab.

Projektabhängig kann die Energiemenge noch vom variablen SOC-Fenster, dem Alterungszustand, dem";
CM_ SG_ 2463978705 BMS_PerfInd_Entladen "Leistungsindikation in Entladerichtung.
Der Bereich 100...200% beschreibt die verbleibende Reserve, bis ein Derating der maximalen Entladeleistungsgrenze eintritt.
Werte von 0 bis 100% beschreiben, auf welchen Teil der potentiell möglichen maximalen Ent";
CM_ SG_ 2463978705 BMS_PerfInd_Laden "Leistungsindikation in Laderichtung.
Der Bereich 100...200% beschreibt die verbleibende Reserve, bis ein Derating der maximalen Ladeleistungsgrenze eintritt.
Werte von 0 bis 100% beschreiben, auf welchen Teil der potentiell möglichen maximalen Ladeleist";
CM_ SG_ 2463978705 BMS_Status_EoHVL_Heizer "Status Erkennung offener HV-Leitung (EoHVL) / offene Steckverbindung zum HV-Batterieheizer (PTC):
0=Init
1=Keine offene HV-Leitung erkannt
2=offene HV-Leitung erkannt
3=Fehler";
CM_ SG_ 2463978705 BMS_Warnung_Stuetzung_NV "Warnung an das Energiemanagement zur Verfügbarkeit der sicherheitsrelevanten NV-Stützung.

Bei Stuetzung_iO kann die HV-Batterie zum aktuellen Zeitpunkt für die vorgegebene Dauer die notwendige Leistung/Energie zur Stützung des NV-Systems zur Verfügung ";

CM_ SG_ 2589283664 BMS_Balancing_Aktiv "Signal zeigt an, ob mindestens eine Zelle der HV Batterie balanciert wird";
CM_ SG_ 2589283664 BMS_Ladevorgang_aktiv "Signalisiert aktiven Ladevorgang, Ladegerät und DC/DC aktiv.
Signal bleibt nach Kl.15 ein aktiv, bis ESP_Stillstandsflag gelöscht.

Abhängigkeit zu BMS_Energieinhalt";
CM_ SG_ 2589283664 BMS_Max_Energie "Nutzbarer maximaler Entlade-Energieinhalt der vollgeladenen Batterie. 

Projektabhängig kann der Energiewert vom variablen SOC-Fenster (zwischen oberer und unterer SOC-Grenze), dem Alterungszustand, dem aktuellen Lastprofil sowie der Temperatur abhängen";
CM_ SG_ 2589283664 BMS_Max_Ladezustand "Obere Ladezustandsgrenze für das SOC-Fenster in der Betriebsstrategie. 
Der Wert kann sich über Lebensdauer und Alterung des Batteriesystems ändern; 
Erreicht der Wert 'BMS_Ladezustand' den hier übertragenen Wert, darf die Batterie nicht weiter geladen ";
CM_ SG_ 2589283664 BMS_Min_Ladezustand "Untere Ladezustandsgrenze für das SOC-Fenster in der Betriebsstrategie. 
Der Wert kann sich über Lebensdauer und Alterung des Batteriesystems ändern; 
Erreicht der Wert 'BMS_Ladezustand' nach unten hin den hier übertragenen Wert, darf die Batterie nicht";
CM_ SG_ 2589283664 BMS_RIso_Ext "Minimum des Isolationswiderstands zwischen Batteriegehäuse und HV+ bzw. Batteriegehäuse und HV- bei geschlossenen Schützen (externe Iso Messung)";

CM_ SG_ 2589283665 BMS_BattHeizung_VerbautStatus "Verbausignalisierung der optionalen HV-Batterieheizung";
CM_ SG_ 2589283665 BMS_Fehler_NTKreis "Fehler im NTKreis, HV-Batterie wird nicht klimatisiert
(Fehler, Fehlerfrei) ";
CM_ SG_ 2589283665 BMS_Pumpe1_Ansteuerung "Ansteuerung der Batterie-Kühlmittelpumpe.
0% = Pumpe abgeschaltet
100% = Pumpe maximal angesteuert";
CM_ SG_ 2589283665 BMS_Pumpe2_Ansteuerung "Ansteuerung einer zweiten Kühlmittelpumpe.
Projektabhängig für Systeme, die seitens Batterie zwei Pumpen ansteuern.
0% = Pumpe abgeschaltet
100% = Pumpe maximal angesteuert";
CM_ SG_ 2589283665 BMS_RuecklaufTemperatur "Aktueller Messwert der Kühlmittel-Rücklauftemperatur
am Kühlmittel-Auslass des Batteriesystems.";
CM_ SG_ 2589283665 BMS_SollVorlauftemperatur "Soll_Vorlauftemperatur_Kühlmedium in °C";
CM_ SG_ 2589283665 BMS_Status_Ventil1 "Status Ventil; wassergekühltes Batteriesystem.
Batteriekreis-Absperrventil.

nicht-angesteuert = Batterie im kleinen Kühlkreislauf, abgetrennt vom restlichen Kühlsystem
angesteuert = Batterie eingeschleift in großen Kühlkreislauf (Niedertemperatur-Küh";
CM_ SG_ 2589283665 BMS_Status_Ventil2 "Status des zweiten Ventils; wassergekühltes Batteriesystem.
Für Systeme, wo die Batterie ein zweites Ventil ansteuert.
Belegung projektabhängig.

nicht-angesteuert = großer Kühlkreislauf (Niedertemperatur-Kühlkreis) abgetrennt vom Batteriesystem oder ";
CM_ SG_ 2589283665 BMS_Temperatur "battery temperature / Momentanwert: Temperatur der Traktionsbatterie";
CM_ SG_ 2589283665 BMS_Temperierung_Anf "Temperierungsbedarf der HV-Batterie";
CM_ SG_ 2589283665 BMS_VorlaufTemperatur "Aktueller Messwert der Kühlmittel-Vorlauftemperatur
am Kühlmittel-Einlass des Batteriesystems.";

CM_ SG_ 2589283760 BMS_Dauer_Entladeleistung "ist die aktuelle Dauer-Leistungsfähigkeit der Batterie. 
Wenn dieser Wert überschritten wird, kann ein zeitliches Derating der maximalen Leistungsgrenzen stattfindet. Die Dauerleistung ändert sich mit Batterietemperatur und Ladezustand.";
CM_ SG_ 2589283760 BMS_Dauer_Ladeleistung "ist die aktuelle Dauer-Leistungsfähigkeit der Batterie. 
Wenn dieser Wert überschritten wird, kann ein zeitliches Derating der maximalen Leistungsgrenzen stattfindet. Die Dauerleistung ändert sich mit Batterietemperatur und Ladezustand.";
CM_ SG_ 2589283760 BMS_Max_Spannung "Maximal erlaubte Batteriespannung, zwingend einzuhaltender Grenzwert";
CM_ SG_ 2589283760 BMS_Min_Spannung "Minimal erlaubte Batteriespannung, zwingend einzuhaltender Grenzwert";

CM_ SG_ 2589283762 BMS_eTM_KonditionierWunsch "Über dieses Signal teilt die HV-Batterie mit, daß sie gerne über den NT-Kreis gekühlt oder geheizt werden möchte. Die potentielle Umsetzbarkeit dieses Konditionierungswunsches muß über ein CAN-Signal von der Antriebssteuerung bestätigt werden, bevor die H";
CM_ SG_ 2589283762 BMS_PerfInd_EntladenPeak_Temp "Peformanceindikator für temperaturabhängige Leistungsreduzierung beim Entladen 
(bezogen auf Peakleistung entsprechend des SOCs bei Wohlfühltemperatur)";
CM_ SG_ 2589283762 BMS_PerfInd_LadenPeak_Temp "Peformanceindikator für temperaturabhängige Leistungsreduzierung beim Laden 
(bezogen auf Peakleistung entsprechend des SOCs bei Wohlfühltemperatur)";
CM_ SG_ 2589283762 BMS_SollVolumenstrom "Soll Volumenstrom für Kühlkreislauf Batterie";
CM_ SG_ 2589283762 BMS_TempStatus_Entladen "Signalisiert den Temperaturzustand der Batterie aufgrund dessen eine evt. Leistungseinschränkung beim Entladen besteht.";
CM_ SG_ 2589283762 BMS_TempStatus_Laden "Signalisiert den Temperaturzustand der Batterie aufgrund dessen eine evt. Leistungseinschränkung beim Laden besteht.";
CM_ SG_ 2589283762 BMS_TMA_Betriebsart "Interne Betriebsart des Batterie-Thermomanagements.
0 = Klimatisierung abgeschaltet
1 = für 'normalen' Fahrbetrieb aktiv
2 = Vorkonditionierung auf Schnelladung während Fahrt
3 = reduzierte Klimatisierung im AC-Laden
4 = maximale Klimatisierung im DC";
CM_ SG_ 2589283762 BMS_TMA_Kuehlkreis_Status "HVBat meldet den seitens Batterie gerade aktiven Zustand des Kühlkreises/Kühlsystems.
0 = Batterieklimatisierung abgeschaltet, Pumpe abgeschaltet. Ventilstellung im 2-Kreis-Betrieb, so daß NT-Kreis weiterhin betrieben werden kann.
1 = Umwälzbetrieb, the";

CM_ SG_ 2331595856 BMS_DC_Ladeschuetze_Ist "Status der DC-Ladeschütze der HV-Batterie";
CM_ SG_ 2331595856 BMS_EnergieVorhalt "Energievorhalt der Batterie (z.B. als Alterungsreserve), welcher nicht in der aktuellen Betriebsstrategie verwendet werden kann, aber zur Kompensation der Alterung genutzt werden kann.";
CM_ SG_ 2331595856 BMS_Hauptschuetze_Ist "Status der Hauptschütze der HV-Batterie";
CM_ SG_ 2331595856 BMS_Last_Chg_adeq_SOCswing_Day "Zeitpunkt (Tag) des letzten, für die UBE_Indikator-Berechnung adäquaten  Ladehubs (aktuelle Forderung: >50% SOC)";
CM_ SG_ 2331595856 BMS_Last_Chg_adeq_SOCswing_Month "Zeitpunkt (Monat) des letzten, für die UBE_Indikator-Berechnung adäquaten  Ladehubs (aktuelle Forderung: >50% SOC)";
CM_ SG_ 2331595856 BMS_Last_Chg_adeq_SOCswing_Year "Zeitpunkt (Jahr) des letzten, für die UBE_Indikator-Berechnung adäquaten  Ladehubs (aktuelle Forderung: >50% SOC)";
CM_ SG_ 2331595856 BMS_Max_UBE "BMS_UBE bei BMS_Ladezustand = BMS_Max_Ladezustand. Das Verhältnis BMS_UBE/BMS_UBE_Max ergibt den energetischen Kunden-SOC (ohne Berücksichtigung eventueller Anzeigereserven)";
CM_ SG_ 2331595856 BMS_Nennspannung "Nennspannung der HV Batterie (Nennspannung der Zelle nach PV8450 multipliziert mal Anzahl in Serie geschalteter Zellen)";
CM_ SG_ 2331595856 BMS_Range_Indikator "Der Range-Indikator gibt das Verhältnis der aktuellen maximalen Reichweite zur maximalen Reichweite eines Neufahrzeugs wieder. Da die Reichweite primär von der UBE abhängt, wird dieser Wert im BMS berechnet.";
CM_ SG_ 2331595856 BMS_UBE "„Usable Battery Energy“ = Nutzbare Entladeenergie der HV Batterie vom aktuellen Ladezustand bis zum Ende des elektrischen Fahrens unter Annahme von Homologationsbedingungen (Lastprofil, Temperatur). Ein negativer Wert bedeutet, dass der aktuelle Ladezusta";
CM_ SG_ 2331595856 BMS_UBE_Indik_last_update_km "Strecke seit letzter Aktualisierung des UBE-Indikators. Ausgabe in der Einheit [km]";
CM_ SG_ 2331595856 BMS_UBE_Indikator "Der UBE Indikator gibt das Verhältnis der aktuellen maximalen UBE (BMS_Max_UBE) zur maximalen UBE einer neuen HV Batterie wieder.";
CM_ SG_ 2331595856 BMS_UBE_T "Gleiche Bedeutung wie das Signal BMS_UBE unter Berücksichtigung der aktuellen Batterietemperatur. Eine Temperaturänderung wird nicht angenommen.
Dieses Signal kann zum Beispiel verwendet werden, um eine Restenergie der HV Batterie zu berechnen.";
CM_ SG_ 2331595856 SOK_BMS_34_Signatur "Signatur im Rahmen der durch SOK geschützen Broadcast-Kommunikation

Geschützte Funktion: UBE-Indikator
Geschützte PDU: BMS_34";

CM_ SG_ 397 BMS_MV_01_BZ "4bit Botschaftszähler, wird mit jeder Sendebotschaft inkrementiert";
CM_ SG_ 397 BMS_MV_01_CRC "Für MLB:
Berechnung siehe Lastenheft 'Kommunikationsabsicherung für FlexRay und CAN'
Ab MQB und MLBevo:
Berechnung siehe Lastenheft 'End-to-End Kommunikationsabsicherung'

Endwerte siehe Begleitdokument 'S-PDU Kennungsfolgen'";
CM_ SG_ 397 BMS_MV_IstSpannung "actual voltage of the battery / Momentanwert: Batteriespannung";
CM_ SG_ 397 BMS_MV_IstSpannung_Zwkr "Die aktuelle Zwischenkreisspannung gemessen von der MV-Batterie";
CM_ SG_ 397 BMS_MV_IstStrom "Momentanwert: Batteriestrom
Stromrichtung: ein Ladestrom wird mit positiven, ein Entladestrom mit negativen Werten angegeben";
CM_ SG_ 397 BMS_MV_SOC_HiRes "State of Charge / aktueller Ladezustand der Batterie (höhere Auflösung)";

CM_ SG_ 419 BMS_MV_MaxDyn_EntladeStrom "max current (discharge)
maximal zulässiger Entladestrom (zwingend einzuhaltender Grenzwert); Wert ist für eine Dauer von z.B. 1s garantiert";
CM_ SG_ 419 BMS_MV_MaxDyn_LadeStrom "max current (charge)
maximal zulässiger Ladestrom (zwingend einzuhaltender Grenzwert); Wert ist für eine Dauer von z.B.  1s garantiert";
CM_ SG_ 419 BMS_MV_Min_EntladeSpannung "min. voltage / minimal erlaubte Batteriespannung (zwingend einzuhaltender Grenzwert)";
CM_ SG_ 419 BMS_MV_MinDyn_LadeSpannung "min. voltage during charge with current MaxDyn_LadeStrom resp. iChMax / rechnerischer Wert: minimales, für eine Dauer von z.B. 1s garantiertes Spannungsniveau, das unter Belastung mit MaxDyn_LadeStrom bzw. iChMax nicht unterschritten werden würde";
CM_ SG_ 419 BMS_MV_MinDynEntladeSpannung "min. voltage during discharge with current MaxDyn_EntladeStrom resp. iDisChMax / rechnerischer Wert: minimales, für eine Dauer von ~1s garantiertes Spannungsniveau, das unter Belastung mit MaxDyn_EntladeStrom bzw. iDisChMax nicht unterschritten werden wür";

CM_ SG_ 2589283412 BMS_MV_IstRuecklaufTemperatur "Aktuelle Ruecklauftemperatur der Batterie

Abweichender individueller Init-Wert = 254 (Standardkodierung = 254)";
CM_ SG_ 2589283412 BMS_MV_IstVorlaufTemperatur "Aktuelle Vorlauftemperatur der Batterie

Abweichender individueller Init-Wert = 254 (Standardkodierung = 254)";
CM_ SG_ 2589283412 BMS_MV_Soll_PWM_Pumpe "Fehlende Beschreibung (Import)";
CM_ SG_ 2589283412 BMS_MV_SollVolumenstrom "Mindestanforderung des Soll Volumenstrom für Kühlkreislauf Batterie";
CM_ SG_ 2589283412 BMS_MV_SollVorlauftemperatur "Soll_Vorlauftemperatur_Kühlmedium in °C

Abweichender individueller Init-Wert = 254 (Standardkodierung = 254)";
CM_ SG_ 2589283412 BMS_MV_Speichertechnologie "Speichertechnologie des MV-Speichers. Zuordnung zur Technologie in MV FLAH.";
CM_ SG_ 2589283412 BMS_MV_Temp_Epsilon "Das Signal beschreibt die Differenz zwischen Batterie Soll-Temperatur und Batterie Ist-Temperatur.";
CM_ SG_ 2589283412 BMS_MV_Temperatur "battery temperature / Momentanwert: Temperatur der Traktionsbatterie

Abweichender individueller Init-Wert = 254 (Standardkodierung = 254)";
CM_ SG_ 2589283412 BMS_MV_Temperierung_Anf "Temperierungsbedarf der HV-Batterie";

CM_ SG_ 2589283608 BMS_MV_Energieinhalt "aktuell nutzbarer Energieinhalt der MV-Batterie
(bezogen auf ein definiertes mittleres Belastungsprofil)";
CM_ SG_ 2589283608 BMS_MV_MaxEnergieinhalt "maximaler nutzbarer Energieinhalt der MV-Batterie (bezogen auf Last KBI_RWDS_Lastprofil bei SOC=100%)
Abhängig von KBI_RWDS_Lastprofil";

CM_ SG_ 2589283606 BMS_MV_max_Grenz_SOC "oberer Grenz SOC - Betriebsstrategie";
CM_ SG_ 2589283606 BMS_MV_SOC_Kaltstart "Abhängig von der notwendigen Kaltstartleistung berechneter SOC Wert.";

CM_ SG_ 1021 BMS_MV_Pred_Entladeperformance "Indikator Stromintegral in Entladerichtung. 
0%     = Start abrampen Peak-Entladestromgrenze auf Dauer-Entladestromgrenze.
100% = Voller Peak-Entladestrom verfügbar";
CM_ SG_ 1021 BMS_MV_Pred_Ladeperformance "Indikator Stromintegral in Laderichtung. 
0%     = Start abrampen Peak-Ladestromgrenze auf Dauer-Ladestromgrenze.
100% = Voller Peak-Ladestrom verfügbar";
CM_ SG_ 1021 BMS_MV_SOHC_DiagSOC "Zielwert zum Start und Durchführung der SOHC-Diagnose (0%-100%)";
CM_ SG_ 1021 BMS_MV_SOHC_DiagStatus "Aktueller Diagnose Status der SOHC-Diagnose:

[0] kein Diagnosebedarf
[1] Diagnosebedarf niedrig
[2] Diagnosebedarf mittel
[3] Diagnosebedarf Zwang
[4] Diagnosebedarf Werkstatt
[5] Diagnose läuft
[6] Diagnoseabbruch
[7] Diagnosefehler";

CM_ SG_ 2463978716 BMS_MV_12_BZ "4bit Botschaftszähler, wird mit jeder Sendebotschaft inkrementiert";
CM_ SG_ 2463978716 BMS_MV_12_CRC "Für MLB:
Berechnung siehe Lastenheft 'Kommunikationsabsicherung für FlexRay und CAN'
Ab MQB und MLBevo:
Berechnung siehe Lastenheft 'End-to-End Kommunikationsabsicherung'

Endwerte siehe Begleitdokument 'S-PDU Kennungsfolgen'";
CM_ SG_ 2463978716 BMS_MV_Fehler_BattAbschaltung "Fehler: Fehlerzustand, erfordert das Öffnen der Batterieschütze
interner Batteriefehler, Batterieschütze ohne Vorankündigung durch das BMS geöffnet";
CM_ SG_ 2463978716 BMS_MV_Fehler_BattAbschaltungAnf "Fehler: Fehlerzustand, erfordert das Öffnen der Batterieschütze
interner Batteriefehler; Vorankündigung eines bevorstehenden Öffnens der Batterieschütze durch das BMS";
CM_ SG_ 2463978716 BMS_MV_Fehler_Kaltstartleistung "Signalisiert, dass die Leistungsreserve der MV-Batterie für die erwartete Kaltstartleistung nicht ausreichend ist.";
CM_ SG_ 2463978716 BMS_MV_Fehler_Leistungsred "Fehler: Leistungsfähigkeit der Batterie ist eingeschränkt (z.B. aufgrund des Ausfalls von Sensoren oder des Lüfters)";
CM_ SG_ 2463978716 BMS_MV_Fehler_Notfallreserve "signalisiert, dass die geforderte Energiereserve nach ASIL zur Versorgung der NV-Verbraucher nicht voll verfügbar ist";
CM_ SG_ 2463978716 BMS_MV_Fehler_Relay_offen "Fehler: Relais schließt nicht / MV-Batterie nicht verfügbar
kann MV-Netz nicht aktivieren (z.B. defektes Relais, Sicherung, Vorlade-Fehler)";
CM_ SG_ 2463978716 BMS_MV_Fehler_Relay_verschweisst "Fehler: Relais verschweißt";
CM_ SG_ 2463978716 BMS_MV_IstModus "actual state of the battery / momentaner Status der Batterie
0: Standby; Kommunikation aktiv
1: Hauptschütze geschlossen / MV-Netz aktiviert / normaler Fahrbetrieb
5: interner Batteriefehler / angeforderter Modus kann nicht eingestellt werden
7: Initi";
CM_ SG_ 2463978716 BMS_MV_Leistungsreduzierung "Signalisierung der Performanceeinschränkung der 48V Batterie aufgrund hoher Temperatur";
CM_ SG_ 2463978716 BMS_MV_Peak_EntladeLeistung "aktuell zulässige PeakEntladeleistung (Wert ist für eine kurze Dauer); auf die Grenze wird ein Derating angewendet";
CM_ SG_ 2463978716 BMS_MV_Peak_EntladeSpannung "Erwartete Spannung, die sich bei Belastung der MV Batterie mit der Peak-Entladeleistung einstellt.";
CM_ SG_ 2463978716 BMS_MV_Peak_LadeLeistung "aktuell zulässige PeakLadeleistung (Wert ist für eine kurze Dauer); auf die Grenze wird ein Derating angewendet.";
CM_ SG_ 2463978716 BMS_MV_Peak_LadeSpannung "Erwartete Spannung, die sich bei Belastung der MV Batterie mit der Peak-Ladeleistung einstellt.";

CM_ SG_ 2463978717 BMS_MV_Max_EntladeLeistung "aktuell zulässige strategische Entladeleistung (Wert ist für eine mittlere Dauer); auf die Grenze wird ein Derating angewendet";
CM_ SG_ 2463978717 BMS_MV_Max_LadeLeistung "aktuell zulässige strategische Ladeleistung (Wert ist für eine mittlere Dauer); auf die Grenze wird ein Derating angewendet.";
CM_ SG_ 2463978717 BMS_MV_PerfInd_Entladen "Leistungsindikation in Entladerichtung.
Der Bereich 100...200% beschreibt die verbleibende Reserve, bis ein Derating der maximalen Entladeleistungsgrenze eintritt.
Werte von 0 bis 100% beschreiben, auf welchen Teil der potentiell möglichen maximalen Ent";
CM_ SG_ 2463978717 BMS_MV_PerfInd_Laden "Leistungsindikation in Laderichtung.
Der Bereich 100...200% beschreibt die verbleibende Reserve, bis ein Derating der maximalen Ladeleistungsgrenze eintritt.
Werte von 0 bis 100% beschreiben, auf welchen Teil der potentiell möglichen maximalen Ladeleist";
CM_ SG_ 2463978717 BMS_MV_Strat_EntladeSpannung "Erwartete Spannung, die sich bei Belastung der MV Batterie mit der Max-Entladeleistung einstellt.";

CM_ SG_ 2463978718 BMS_MV_14_BZ "4bit Botschaftszähler, wird mit jeder Sendebotschaft inkrementiert";
CM_ SG_ 2463978718 BMS_MV_14_CRC "Für MLB:
Berechnung siehe Lastenheft 'Kommunikationsabsicherung für FlexRay und CAN'
Ab MQB und MLBevo:
Berechnung siehe Lastenheft 'End-to-End Kommunikationsabsicherung'

Endwerte siehe Begleitdokument 'S-PDU Kennungsfolgen'";
CM_ SG_ 2463978718 BMS_MV_Max_EntladeStrom_Lim "Maximal erlaubter Entladestrom (zwingend einzuhaltender Grenzwert) für transiente Vorgänge (Subsekundenbereich). Es erfolgt kein Derating";
CM_ SG_ 2463978718 BMS_MV_Max_LadeSpannung_Lim "maximal erlaubte Betriebsspannung (Abregelgrenze). Zwingend einzuhaltender Grenzwert.";
CM_ SG_ 2463978718 BMS_MV_Max_LadeStrom_Lim "Maximal erlaubter Ladestrom (zwingend einzuhaltender Grenzwert) für transiente Vorgänge (Subsekundenbereich). Es erfolgt kein Derating.";
CM_ SG_ 2463978718 BMS_MV_Min_EntladeSpannung_Lim "Minimal erlaubte Batteriespannung (Abregelgrenze): Zwingend einzuhaltender Grenzwert.";
CM_ SG_ 2463978718 BMS_MV_Strat_LadeSpannung "Erwartete Spannung, die sich bei Belastung der MV Batterie mit der Max-Ladeleistung einstellt.";

CM_ SG_ 2589283523 BMS_48V_Indc_StChk "Übermittlung vom Diagnoseergebnis für das Inducement";
CM_ SG_ 2589283523 BMS_48V_Indc_StFail "Inducement Anforderung";
CM_ SG_ 2589283523 BMS_MV_Dauer_EntladeLeistung "ist die aktuelle Dauer-Leistungsfähigkeit der Batterie. 
Wenn dieser Wert überschritten wird, kann ein zeitliches Derating der maximalen Leistungsgrenzen stattfindet. Die Dauerleistung ändert sich mit Batterietemperatur und Ladezustand.";
CM_ SG_ 2589283523 BMS_MV_Dauer_EntladeSpannung "Erwartete Spannung, die sich bei Belastung der MV Batterie mit der Dauer-Entladeleistung einstellt.";
CM_ SG_ 2589283523 BMS_MV_Dauer_LadeLeistung "ist die aktuelle Dauer-Leistungsfähigkeit der Batterie. 
Wenn dieser Wert überschritten wird, kann ein zeitliches Derating der maximalen Leistungsgrenzen stattfindet. Die Dauerleistung ändert sich mit Batterietemperatur und Ladezustand.";
CM_ SG_ 2589283523 BMS_MV_Dauer_LadeSpannung "Erwartete Spannung, die sich bei Belastung der MV Batterie mit der Dauer-Ladeleistung einstellt.";
CM_ SG_ 2589283523 BMS_MV_Dauer_RMS_Strom "Dauerhaft maximal verfügbarer RMS-Strom ohne thermisches Derating.";
CM_ SG_ 2589283523 BMS_MV_Kundenwarnung "Kundenwarnung aufgrund eines Batteriefehlers.";
CM_ SG_ 2589283523 BMS_MV_OBD_Lampe_Anf "Anforderung MIL (MalfunctionIndicationLamp) von BMS (Motorsteuergerät reicht diese Info an Kombi weiter).";
CM_ SG_ 2589283523 OBDProtocol_BMS_48V "Bestätigung des aktuell umgesetzten Scan Tool Protokolls";

CM_ SG_ 2589283543 SOK_BMS_MV_15_Signatur "Signatur im Rahmen der durch SOK geschützen Broadcast-Kommunikation

Geschützte Funktion: OBD-Malfunction Indicator Light (MIL)
Geschützte PDU: BMS_MV_15";

CM_ SG_ 2589283524 BMS_MV_EntladeEnergie "Maximal verfügbare Energie in Entladerichtung basierend auf dem gemittelten Entladestrom";
CM_ SG_ 2589283524 BMS_MV_LadeEnergie "Maximal verfügbare Energie in Laderichtung basierend auf dem gemittelten Ladestrom";
CM_ SG_ 2589283524 BMS_MV_Max_RMS_Strom "Maximal verfügbarer RMS-Strom ohne thermisches Derating innerhalb eines definierten Zeitraums (z.B. 10min).";
CM_ SG_ 2589283524 BMS_MV_TRD_Sensfail "Batteriesensordiagnose zur Prüfung ob der Kommunikationsausfall der Batterie durch 'thermal runaway' ausgelöst wurde";
CM_ SG_ 2589283524 BMS_MV_TRD_Temp "Temperaturdiagnose zur Prüfung, ob der Kommunikationsausfall der Batterie durch 'thermal runaway' ausgelöst wurde";
CM_ SG_ 2589283524 BMS_MV_TRD_Voltage "Spannungsdiagnose zur Prüfung ob der Kommunikationsausfall der Batterie durch 'thermal runaway' ausgelöst wurde";

CM_ SG_ 2527679928 BMS_NV_Indc_StChk "Inducement";
CM_ SG_ 2527679928 BMS_NV_Indc_StFail "0: passiv/Init
1: aktiv";
CM_ SG_ 2527679928 BMS_NV_OBD_Lampe_Anf "MIL Lampe Anforderung wegen OBD relevanter Fehler im 12V NV Speicher";
CM_ SG_ 2527679928 OBDProtocol_BMS_NV "Bestätigung des aktuell umgesetzten Scan Tool Protokolls";
CM_ SG_ 2527679928 SOK_BMS_NV_11_Signatur "Signatur im Rahmen der durch SOK geschützen Broadcast-Kommunikation

Geschützte Funktion: OBD-Malfunction Indicator Light (MIL)
Geschützte PDU: BMS_NV_11";

CM_ SG_ 2463978646 CHA_Current_Mode "Aktuell eingestelltes Charisma Fahrprogramm";
CM_ SG_ 2463978646 CHA_Fahrer_Umschaltung "Die manuelle Umschaltung durch den Fahrer soll signalisiert werden, um zu automatischen Umschaltungen (z.B. Retries) differenzieren zu können.";
CM_ SG_ 2463978646 CHA_Fahrer_Umschaltung_BMA "Die manuelle Umschaltung der Betriebsmodusauswahl durch den Fahrer soll signalisiert werden, um zu automatischen Umschaltungen (z.B. Retries) differenzieren zu können.";
CM_ SG_ 2463978646 CHA_Ziel_FahrPr_ACC "MQB
Anforderung Ziel-Fahrprogramm ACC";
CM_ SG_ 2463978646 CHA_Ziel_FahrPr_AEB "Anforderung Ziel-Fahrprogramm AEB (Autonomous Emergency Braking)";
CM_ SG_ 2463978646 CHA_Ziel_FahrPr_AFR "Anforderung Ziel-Fahrprogramm Aktive Fahrwerk Regelung (eAWS und eABC)";
CM_ SG_ 2463978646 CHA_Ziel_FahrPr_AFS "Anforderung Ziel-Fahrprogramm AFS";
CM_ SG_ 2463978646 CHA_Ziel_FahrPr_AGA "Anforderung Ziel-Fahrprogramm AGA/SAK2 (Aussensound)";
CM_ SG_ 2463978646 CHA_Ziel_FahrPr_AGK "Signal zur Ansteuerung des Teilnehmers Abgasklappen durch den Charisma-Koordinator über das Motor-SG";
CM_ SG_ 2463978646 CHA_Ziel_FahrPr_ALR "Anforderung Ziel-Fahrprogramm Allrad";
CM_ SG_ 2463978646 CHA_Ziel_FahrPr_AV "Anforderung Ziel-Fahrprogramm AreaView2";
CM_ SG_ 2463978646 CHA_Ziel_FahrPr_BMS "Anforderung Ziel-Fahrprogramm BMS (nähere Spezifikation siehe Charisma-LH PAG)";
CM_ SG_ 2463978646 CHA_Ziel_FahrPr_DR "Anforderung Ziel-Fahrprogramm Dämpfer";
CM_ SG_ 2463978646 CHA_Ziel_FahrPr_EAR "Anforderung Zielfahrprogramm EAR (EFP Allrad Regelsysteme)";
CM_ SG_ 2463978646 CHA_Ziel_FahrPr_EBKV "Signal zur Ansteuerung des EBKV durch den Charisma-Koordinator";
CM_ SG_ 2463978646 CHA_Ziel_FahrPr_EDS "Anforderung Ziel-Fahrprogramm Elektronische Differentialsperre";
CM_ SG_ 2463978646 CHA_Ziel_FahrPr_EPS "Anforderung Ziel-Fahrprogramm Elektrische Lenkhilfe";
CM_ SG_ 2463978646 CHA_Ziel_FahrPr_eSound "Anforderung Ziel-Fahrprogramm eSound";
CM_ SG_ 2463978646 CHA_Ziel_FahrPr_ESP "Anforderung Ziel-Fahrprogramm ESP";
CM_ SG_ 2463978646 CHA_Ziel_FahrPr_FCWO "Anforderung Ziel-Fahrprogramm FCWO (Objektwarnung)";
CM_ SG_ 2463978646 CHA_Ziel_FahrPr_FCWP "Anforderung Ziel-Fahrprogramm FCWP (Personenwarnung)";
CM_ SG_ 2463978646 CHA_Ziel_FahrPr_Freilauf "Anforderung Ziel-Fahrprogramm Funktion Freilauf";
CM_ SG_ 2463978646 CHA_Ziel_FahrPr_GE "Anforderung Ziel-Fahrprogramm Getriebe";
CM_ SG_ 2463978646 CHA_Ziel_FahrPr_HAL "Anforderung Zielfahrprogramm Hinterachslenkung (HAL)";
CM_ SG_ 2463978646 CHA_Ziel_FahrPr_HDC "Anforderung Ziel-Fahrprogramm Hill Descent Control";
CM_ SG_ 2463978646 CHA_Ziel_FahrPr_HHC "Anforderung Ziel-Fahrprogramm Hill Hold Control";
CM_ SG_ 2463978646 CHA_Ziel_FahrPr_IL "Anforderung Ziel-Fahrprogramm Integrallenkung";
CM_ SG_ 2463978646 CHA_Ziel_FahrPr_mFDR "Signal zur Ansteuerung des mFDR durch den Charisma-Koordinator";
CM_ SG_ 2463978646 CHA_Ziel_FahrPr_MO "Anforderung Ziel-Fahrprogramm Motor";
CM_ SG_ 2463978646 CHA_Ziel_FahrPr_MO_BZS "Anforderung Zielfahrprogramm Motor-Betriebszusände";
CM_ SG_ 2463978646 CHA_Ziel_FahrPr_MO_Freilauf "Anforderung Ziel-Fahrprogramm Funktion Freilauf Motor aus";
CM_ SG_ 2463978646 CHA_Ziel_FahrPr_MO_StSt "Anforderung Ziel-Fahrprogramm Funktion Motor Start-Stopp";
CM_ SG_ 2463978646 CHA_Ziel_FahrPr_MXB "Anforderung Ziel-Fahrprogramm MXB";
CM_ SG_ 2463978646 CHA_Ziel_FahrPr_NR "Anforderung Ziel-Fahrprogramm Niveaureglierung";
CM_ SG_ 2463978646 CHA_Ziel_FahrPr_PACC "Anforderung Ziel-Fahrprogramm InnoDrive (PACCh)";
CM_ SG_ 2463978646 CHA_Ziel_FahrPr_PDC "Signal zur Ansteuerung des PDC/PLA durch den Charisma-Koordinator";
CM_ SG_ 2463978646 CHA_Ziel_FahrPr_PreCrash "Anforderung Ziel-Fahrprogramm PreCrash";
CM_ SG_ 2463978646 CHA_Ziel_FahrPr_QS "Anforderung Ziel-Fahrprogramm geregelte Hinterachsquersperre";
CM_ SG_ 2463978646 CHA_Ziel_FahrPr_Reku_ZwGas "Anforderung Ziel-Fahrprogramm für Rekuperation oder Zwischengas";
CM_ SG_ 2463978646 CHA_Ziel_FahrPr_RHP "MQB
Anforderung Ziel-Fahrprogramm RHP";
CM_ SG_ 2463978646 CHA_Ziel_FahrPr_SAK "Anforderung Ziel-Fahrprogramm Soundaktuator";
CM_ SG_ 2463978646 CHA_Ziel_FahrPr_SCU "Anforderung Ziel-Fahrprogramm SCU";
CM_ SG_ 2463978646 CHA_Ziel_FahrPr_ToS_laengs "Signal zur Ansteuerung des Torque Splitter längs durch den Charisma-Koordinator";
CM_ SG_ 2463978646 CHA_Ziel_FahrPr_ToS_quer "Signal zur Ansteuerung des Torque Splitter quer durch den Charisma-Koordinator";
CM_ SG_ 2463978646 CHA_Ziel_FahrPr_VAQ "Anforderung Ziel-Fahrprogramm VAQ";

CM_ SG_ 1485 DC_Abregelung_Temperatur "Abregelung aufgrund Übertemperatur im Leistungsteil (Hochtemperatur-Abregelung)";
CM_ SG_ 1485 DC_Derating "Signalisierung, ob der DC/DC-Wandler sich in der Abregelung befindet:
0=keine_Abregelung
1= Abregelung_Ursache_NV
2= Abregelung_Ursache_HV
3= Abregelung_Ursache_Temp
4= Abregelung_Ursache_Intern";
CM_ SG_ 1485 DC_Fehlerstatus "aktueller Fehlerstatus des DCDC-Wandler:";
CM_ SG_ 1485 DC_Kl30c_Status "Signalisierung des
Stecker-Zustandes der Klemme 30c (Service-Disconnect)

0=Init
1=geschlossen
2=offen
3=Fehler";
CM_ SG_ 1485 DC_OBD_Lampe_Anf "Anforderung MIL (MalfunctionIndicationLamp) vom DCDC-Wandler (Motorsteuergerät reicht diese Info an Kombi weiter).";
CM_ SG_ 1485 DC_Peakstrom_verfuegbar "Peakstrom verfügbar/nicht verfügbar";
CM_ SG_ 1485 DC_SollVolumenstrom "Für die Kühlung des DC/DC Wandler aktuell mindestens benötigter Kühlwasservolumenstrom";
CM_ SG_ 1485 DC_Status_Spgfreiheit_HV "HV DC/DC-Wandler Status HV-Spannungsfreiheit";
CM_ SG_ 1485 DC_Temperatur "Momentanwert: Temperatur des DC/DC Wandlers";
CM_ SG_ 1485 DC_Temperatur_Alarm "Temperatur-Alarm DCDC-Wandler RTM";
CM_ SG_ 1485 DC_Warnlampe_Anf "Anforderung der HV-Warnlampe im Kombiinstrument.";
CM_ SG_ 1485 DCDC_03_CRC "Für MLB:
'Berechnung siehe Lastenheft 'Kommunikationsabsicherung für FlexRay und CAN''

Ab MQB und MLBevo:
'Berechnung siehe Lastenheft 'End-to-End Kommunikationsabsicherung''

Endwerte siehe Begleitdokument 'S-PDU Kennungsfolgen'";
CM_ SG_ 1485 DCDC_NV_Indc_StChk "OBM Inducement Request TestNotCompletedThisOperationCycle";
CM_ SG_ 1485 DCDC_NV_Indc_StFail "OBM-Inducement Request TestFailed";
CM_ SG_ 1485 OBDProtocol_DCDC_NV "Bestätigung des aktuell umgesetzten Scan Tool Protokolls";

CM_ SG_ 1486 SOK_DCDC_03_Signatur "Signatur im Rahmen der durch SOK geschützen Broadcast-Kommunikation

Geschützte Funktion: OBD-Malfunction Indicator Light (MIL)
Geschützte PDU: DCDC_03";

CM_ SG_ 247 DC_Fehler_extern "Fehler/Abschaltung: DC/DC-Wandler ist aufgrund einer Umgebungsbedingung (z.B. HV-Spannung, NV-Spannung Kühlmitteltemperatur oder Systemfehler (ZK-Vorladung) ) nicht in der Lage geforderten Regelbetrieb einzuhalten.";
CM_ SG_ 247 DC_Fehler_intern "Fehler: DC/DC-Wandler ist aufgrund eines internen Hardware-Fehlers abgeschaltet";
CM_ SG_ 247 DC_IstLeistung_HV "Aktuelle Ist-Leistung des Bordnetzwandlers auf der HV-Seite. 

Tiefsetzen - positiv
Hochsetzen- negativ";
CM_ SG_ 247 DC_IstModus_02 "aktuelle Betriebsart des DC/DC Wandlers;
0: Standby; Kommunikation aktiv
1: HV_On_Vorladen
2: Tiefsetzen
3: Hochsetzen
4: Pruefimpuls_12V
5: interner Fehler DC/DC-Wandler / angeforderter Sollmodus kann nicht eingestellt werden
6: reserve
7: Initia";
CM_ SG_ 247 DC_IstStrom_HV "Momentanwert:  Strom aus dem Traktionsnetz in den DC/DC Wandler";
CM_ SG_ 247 DC_Status_EoHVL "Status der EoHVL am DCDC :
0=Init
1=Keine offene HV-Leitung erkannt
2=offene HV-Leitung erkannt
3=Fehler";
CM_ SG_ 247 DC_Status_Spgfreiheit "Status der Spannungsfreiheit für den Standalone DCDC-Wandler (HV-NV)
0=Init (ohne Funktion)
1=BMS Zwischenkreis spannungsfrei (U_Zwkr < 20V)
2=BMS Zwischenkreis nicht spannungsfrei (U_Zwkr >/= 25V, Hysterese)
3=Fehler (z.B. Fehler in der Sensorik)";
CM_ SG_ 247 DC_Vorladung_Status "Status der ZK-Vorladung:

=0, nicht_abgeschlossen
=1, abgeschlossen

DCDC-Wandler gibt Empfehlung für schließen der Schützen. 
HVK/BMS prüft die ZK-Spannung und entscheidet ob die Schütze geschlossen werden können.";
CM_ SG_ 247 DCDC_04_BZ "4bit Botschaftszähler, wird mit jeder Sendebotschaft inkrementiert";
CM_ SG_ 247 DCDC_04_CRC "Für MLB:
Berechnung siehe Lastenheft 'Kommunikationsabsicherung für FlexRay und CAN'
Ab MQB und MLBevo:
Berechnung siehe Lastenheft 'End-to-End Kommunikationsabsicherung'

Endwerte siehe Begleitdokument 'S-PDU Kennungsfolgen'";

CM_ SG_ 1484 DC_MV_12V_Bordnetzstuetzung "DC/DC-Wandler befindet sich im Betriebsmodus Bordnetzstützung";
CM_ SG_ 1484 DC_MV_Abregelung_Temperatur "Abregelung aufgrund Übertemperatur im Leistungsteil (Hochtemperatur-Abregelung)";
CM_ SG_ 1484 DC_MV_Derating "Signalisierung, ob der DC/DC-Wandler sich in der Abregelung befindet:
0=keine_Abregelung
1= Abregelung_Ursache_NV
2= Abregelung_Ursache_MV
3= Abregelung_Ursache_Temp
4= Abregelung_Ursache_Intern";
CM_ SG_ 1484 DC_MV_Fehlerstatus "aktueller Fehlerstatus des DCDC-Wandler:";
CM_ SG_ 1484 DC_MV_IstModus_02 "aktuelle Betriebsart des DC/DC Wandlers";
CM_ SG_ 1484 DC_MV_Temperatur "Momentanwert: Temperatur des DC/DC Wandlers";
CM_ SG_ 1484 DC_MV_Tiefsetzen_Notbetrieb "DCDC-Wandler arbeitet im Notbetrieb; ungeregelter Betrieb mit festem Tastverhältnis";
CM_ SG_ 1484 DCDC_MV_03_BZ "4bit Botschaftszähler, wird mit jeder Sendebotschaft inkrementiert";
CM_ SG_ 1484 DCDC_MV_03_CRC "Für MLB:
Berechnung siehe Lastenheft 'Kommunikationsabsicherung für FlexRay und CAN'
Ab MQB und MLBevo:
Berechnung siehe Lastenheft 'End-to-End Kommunikationsabsicherung'

Endwerte siehe Begleitdokument 'S-PDU Kennungsfolgen'";
CM_ SG_ 1484 DCDC_MV_Peakstrom_verfuegbar "Peakstrom verfügbar/nicht verfügbar";

CM_ SG_ 2549880589 DIA_eBooster_Req_Data "Diagnose Request Flashen <SG-Name>";

CM_ SG_ 2550011661 DIA_eBooster_Resp_Data "Diagnose Response Flashen <SG-Name>";

CM_ SG_ 2549880644 DIA_EKAT_Req_Data "Diagnose Request Flashen EKAT";

CM_ SG_ 2550011716 DIA_EKAT_Resp_Data "Diagnose Response Flashen EKAT";

CM_ SG_ 2549880568 DIA_MTFP_Req_Data "Diagnose Request Flashen MTFP";

CM_ SG_ 2550011640 DIA_MTFP_Resp_Data "Diagnose Response Flashen MTFP";

CM_ SG_ 2549880642 DIA_Parksperre_Req_Data "Diagnosezugriff & Flashen Parksperre";

CM_ SG_ 2550011714 DIA_Parksperre_Resp_Data "Diagnosezugriff & Flashen Parksperre";

CM_ SG_ 2549876546 Diag_Parksperre_Req_Data "UDS-Diagnose
ISO-TP Datenkanal - FID2NA
Request Funktion 0x07 Diagnosezugriff vom DK4-Master auf DK1/2-Knoten 0x742";

CM_ SG_ 2550007618 Diag_Parksperre_Resp_Data "UDS-Diganose
ISO-TP Datenkanal - FID2NA
Response DK1/2-Knoten 0x742 an Funktion 0x07 Diagnosezugriff vom DK4-Master";

CM_ SG_ 2549876269 Diag_Waehlhebel_Req_Data "UDS-Diagnose
ISO-TP Datenkanal - FID2NA
Request Funktion 0x06 Diagnosezugriff vom DK4-Master auf DK1/2-Knoten 0x62D";

CM_ SG_ 2550007341 Diag_Waehlhebel_Resp_Data "UDS-Diganose
ISO-TP Datenkanal - FID2NA
Response DK1/2-Knoten 0x62D an Funktion 0x06 Diagnosezugriff vom DK4-Master";

CM_ SG_ 1714 DGN_Verlernzaehler "wrap around 254 --> 0";
CM_ SG_ 1714 KBI_Kilometerstand "Fehler wird ausgegeben, falls Kilometerstand nicht restaurierbar
";
CM_ SG_ 1714 UH_Minute "0x3C- 0x3f = Werte ungültig";
CM_ SG_ 1714 UH_Monat "0x0D, 0xF =  Werte ungültig
0x0E = Relatives Datum (nur VW)";
CM_ SG_ 1714 UH_Sekunde "0x3C- 0x3f = Werte ungültig";
CM_ SG_ 1714 UH_Stunde "0x18 - 0x1F = Werte ungültig";
CM_ SG_ 1714 UH_Tag "0x0: reserviert bei VW";
CM_ SG_ 1714 Uhrzeit_01_alt "
";
CM_ SG_ 1714 Vehicle_Driving_Cycle "Optimierung der Inbetriebnahme von Steuergeräten in einem Teilverbau in der Produktion.
Siehe VW80114. Signal bildet (durch eine Gateway-Funktion) den Inhalt des Signals OBD_Driving_Cycle ab.";

CM_ SG_ 1520 BCM1_Stellgroesse_Kl_58s "Rohwert Dimmpoti";
CM_ SG_ 1520 DI_Display_Nachtdesign "Für Displays sind oft  automatische Umschaltungen von Tag-/Nachtdesign vorgesehen.
Es gibt jedoch Zustände, an denen auch tagsüber das Abblendlicht eingeschaltet ist.
z.B. Dauerfahrlicht, Geschwindigkeitsabhängiges 'Licht-An-Bei-Autobahn', 'Regenlicht',";
CM_ SG_ 1520 DI_Fotosensor "Helligkeitswert Fotosensor
Für die Dimmung relevanter Wert zur Sensierung der Umgebungshelligkeit
Im Detail beschrieben im 'Funktionslastenheft Dimmung MQB'.";
CM_ SG_ 1520 DI_KL_58xd "Klemme 58xd Display- und Funktionsbeleuchtung
Mit der Klemme 58xd wird die Helligkeit der Display- und der Funktionsbeleuchtungen der Schalter gesteuert.
Im Detail beschrieben im 'Funktionslastenheft Dimmung MQB'.";
CM_ SG_ 1520 DI_KL_58xs "Suchbeleuchtung Schalter
EIN-AUS-Schaltalgorithmus der allgemeinen Schaltersuchbeleuchtung. 
Im Detail beschrieben im 'Funktionslastenheft Dimmung MQB'.
";
CM_ SG_ 1520 DI_KL_58xt "Timergesteuerte Suchbeleuchtung
Der EIN-AUS-Schaltalgorithmus für die vor- und nachlaufende Schaltersuchbeleuchtungen beim Ein- & Aussteigen; z.B.: Start/Stop-Taster.
Im Detail beschrieben im 'Funktionslastenheft Dimmung MQB'.";

CM_ SG_ 420 EA_01_BZ "EA Botschaftszähler";
CM_ SG_ 420 EA_01_CRC "Ab MQB und MLBevo:
'Berechnung siehe Lastenheft 'End-to-End Kommunikationsabsicherung''";
CM_ SG_ 420 EA_01_Sendestatus "Gibt den Sendestatus der Botschaft EA_01 an (notwendig für IL-Unterstützung)";
CM_ SG_ 420 EA_aktiv_laengs "Zeigt an, ob der Emergency Assist aktiv längs regelt.";
CM_ SG_ 420 EA_Anf_Prefill "Emergency Assist Anforderung an Prefill";
CM_ SG_ 420 EA_Anforderung_HMS "Emergency Assist Anforderung an HMS";
CM_ SG_ 420 EA_Funktionsstatus "Emergency Assist Funktionsstatus";
CM_ SG_ 420 EA_Gurtstraffer_Anf "Emergency Assist Anforderung reversibler Gurtstraffer";
CM_ SG_ 420 EA_Parken_beibehalten_HMS "Anforderung um automatisches lösen der Parkbremse zu verhindern";
CM_ SG_ 420 EA_PreCrash_Anf "Emergency Assist Anforderung PreCrash";
CM_ SG_ 420 EA_Ruckfreigabe "Emergency Alert Freigabit für die Warnruck-Anforderung an das ESP";
CM_ SG_ 420 EA_Ruckstaerke "Anforderung der Ruckstaerke in schwach, mittel oder stark.";
CM_ SG_ 420 EA_Sollbeschleunigung "Emergency Assist Beschleunigungsanforderung";
CM_ SG_ 420 EA_Warnruckprofil "Emergency Assist Anforderung an ESP, welcher Ruck verwendet werden soll.";

CM_ SG_ 374 EBKV_03_BZ "4bit Botschaftszähler, wird mit jeder Sendebotschaft inkrementiert";
CM_ SG_ 374 EBKV_03_CRC "Für MLB:
Berechnung siehe Lastenheft 'Kommunikationsabsicherung für FlexRay und CAN'
Ab MQB und MLBevo:
Berechnung siehe Lastenheft 'End-to-End Kommunikationsabsicherung'

Endwerte siehe Begleitdokument 'S-PDU Kennungsfolgen'";
CM_ SG_ 374 EBKV_Activate_Fallback_ESP "Das Signal aktiviert im ESC die Rückfallebene.";
CM_ SG_ 374 EBKV_Anforderung_HMS "Anforderung an dem Haltemanager vom EBKV";
CM_ SG_ 374 EBKV_Aussteuerdruck "Das Signal übermittelt seitens des EBKVs frühzeitig den aktuellen, Fahrsituations-abhängig-variablen Brems-Vordruck an das ESC, bei dem die maximale Bremskraftunterstützung des EBVK erreicht ist. 
Über diesen übermittelten Druck-Wert erkennt das ESC den ";
CM_ SG_ 374 EBKV_Bremspedalweg "Bremspedalwert in Prozent. Der Wert ist Nullpunkt-abgeglichen.
Bremspedalweg von der EBKV eingelesen.";
CM_ SG_ 374 EBKV_Diagnose "eBKV im Diagnosemodus";
CM_ SG_ 374 EBKV_Fahrer_bremst "Fahrer will bremsen (Eintreterkennung).
Wird benötigt, um ACC oder GRA abzuschalten.";
CM_ SG_ 374 EBKV_Fahrer_bremst_deutlich "Rückmeldung des eBKVs, ob der Fahrer deutlich eine Bremsung wünscht.

Eine Aktivierung des Signals erfolgt bei 50N Pedalkraft (Druckäquivalent= 20bar, verwendet in AWV-Fkt.)
";
CM_ SG_ 374 EBKV_Kraftblending_Reserve "Maximale Druckdifferenz, die durch Pedalkraftblending noch simuliert werden kann";
CM_ SG_ 374 EBKV_OBD_Status "Ansteuerung der MIL-Lampe über den MIL-Master (Motorsteuergerät)";
CM_ SG_ 374 EBKV_QBit_Fahrer_bremst "
";
CM_ SG_ 374 EBKV_Restdruckabsenkung "Dieses Signal ermöglicht die Steuerung einer Routine zur Restdruckabsenkung aus dem eBKV heraus.
Die genaue Funktionsausprägung muss für das jeweilige Projekt festgelegt werden.";
CM_ SG_ 374 EBKV_Status_02 "eBKV Status Signal für 2 und 3 Box Systeme";
CM_ SG_ 374 EBKV_Textanzeigen "Das Signal sendet im Hinweisfall den Status des eBKV an das Kombiinstrument, welcher das Fahrzeugverhalten für den Nutzer plausibilisieren soll.";
CM_ SG_ 374 EBKV_VMM_Sek_Notstopp_Status "Beschreibt den eBKV -seitigen Status zur Kommunikation mit der Steuerung der Notstopp Rückfallebene im ESC";
CM_ SG_ 374 EPB_Status_ext "Zustand des separat angeschlossenen Aktuators. Signal wird nur im MEB verwendet.";
CM_ SG_ 374 SBS_Anforderung_GE "Das Sekundärbremssystem (SBS) realisiert mit dieser Schnittstelle ein Sichern des Fahrzeugs. Nach einer Bremsung in den Stillstand über die direkte Verzögerungsschnittstelle wird hierüber die Getriebesperre angefordert.";
CM_ SG_ 374 SOK_EBKV_03_Signatur "Signatur im Rahmen der durch SOK geschützten Broadcast-Kommunikation

Geschützte Funktion: Bremsfunktionen Rekuperation und Blending
Geschützte Botschaft: EBKV_03";

CM_ SG_ 2589283963 EBKV_Indc_StChk "OBM Inducement Request TestNotCompletedThisOperationCycle";
CM_ SG_ 2589283963 EBKV_Indc_StFail "OBM-Inducement Request TestFailed";
CM_ SG_ 2589283963 EBKV_OBD_Status_Auth "Ansteuerung der MIL-Lampe über den MIL-Master (Motorsteuergerät)
Redundantes Signal (SOK gesichert) zu EBKV_OBD_Status";
CM_ SG_ 2589283963 OBDProtocol_EBKV "Bestätigung des aktuell umgesetzten Scan Tool Protokolls";
CM_ SG_ 2589283963 SOK_EBKV_05_Signatur "Signatur im Rahmen der durch SOK geschützen Broadcast-Kommunikation

Geschützte Funktion: OBD-Malfunction Indicator Light (MIL)
Geschützte PDU: EBKV_05";

CM_ SG_ 1603 KBI_Einheit_Datum "Anzeigevariante des Datums";
CM_ SG_ 1603 KBI_Einheit_Druck "Einheit des Druckes";
CM_ SG_ 1603 KBI_Einheit_Masse "Einheit der Masse (Verwendung z.B. ASTA)";
CM_ SG_ 1603 KBI_Einheit_Sprache "Siehe BAP-Datenfestlegung UnitMaster";
CM_ SG_ 1603 KBI_Einheit_Streckenanz "Einheit der Streckenanzeige";
CM_ SG_ 1603 KBI_Einheit_Tacho "Information, ob es sich um Meilen- oder Kmh-Kombi handelt, Einheit des Tachos entspricht dem Zifferblatt, Grösse ist nicht veränderlich";
CM_ SG_ 1603 KBI_Einheit_Temp "Einheit der Temperatur";
CM_ SG_ 1603 KBI_Einheit_Uhrzeit "Anzeigevariante der Uhrzeit";
CM_ SG_ 1603 KBI_Einheit_Verbrauch "Einheit der Verbrauchs";
CM_ SG_ 1603 KBI_Einheit_Verbrauch_elektr "Einheit elektrischer Verbrauch";
CM_ SG_ 1603 KBI_Einheit_Verbrauch_Gas "Unterscheidung zwischen M3/h und kg/h für Komfortverbrauchsberechnung.";
CM_ SG_ 1603 KBI_Einheit_Volumen "Einheit des Volumens";
CM_ SG_ 1603 KBI_MFA_v_Einheit_02 "Einheit der Geschwindigkeit, die vom Fahrer im Car-Menü gewählt wurde. Veränderliche Grösse, im Gegensatz zur Einheit des Tachokranzes.

Redundant in der Einheiten_01 Botschaft definiert, um Konsistenz zur BAP-Festlegung zu haben.";

CM_ SG_ 192 EM1_01_BZ "4bit Botschaftszähler, wird mit jeder Sendebotschaft inkrementiert";
CM_ SG_ 192 EM1_01_CRC "Für MLB:
Berechnung siehe Lastenheft 'Kommunikationsabsicherung für FlexRay und CAN'
Ab MQB und MLBevo:
Berechnung siehe Lastenheft 'End-to-End Kommunikationsabsicherung'

Endwerte siehe Begleitdokument 'S-PDU Kennungsfolgen'";
CM_ SG_ 192 EM1_AR_aktiv "Ruckeldämpfer aktiv";
CM_ SG_ 192 EM1_ErwGrenzen_aktiv "Die absoluten Momentengrenzen sind für die Durchführung eines VKM-Starts ggf. aufgeweitet";
CM_ SG_ 192 EM1_Fehler_ElAntriebAbschaltung "Fehler: PWR befindet sich im aktiven Kurzschluss
alle vom EMS gesendeten Max- und Min-Momente und das aktuelle EM-Moment nehmen in diesem Zustand den Wert des für die aktuelle Drehzahl entsprechenden Schleppmoments der E-Maschine an";
CM_ SG_ 192 EM1_Fehler_Notabschaltung "Fehler: Leistungselektronik fordert Abschaltung des HV-Netzes wegen eines schweren Fehlers an";
CM_ SG_ 192 EM1_IstDrehzahl "Momentanwert: E-Maschinen Drehzahl";
CM_ SG_ 192 EM1_Istmodus "aktuelle Betriebsart der E-Maschine...
0: Standby; Kommunikation aktiv; PSM: Aktiver Kurzschluss eingenommen
1: Momentenreglung
2: Drehzahlregeung (interner Regelkreis)
3: Spannungsregelung
4: Drehzahlregelung (externer Regelkreis)
5: interner Inver";
CM_ SG_ 192 EM1_IstMoment "Momentanwert: E-Maschinen Moment";
CM_ SG_ 192 EM1_IstSpannung "Momentanwert: HV-Spannung am PWR";
CM_ SG_ 192 EM1_Max_Moment "maximal darstellbares Moment für eine im Funktionslastenheft definierte Dauer

Die Berechnung der Momentengrenzen wird projektspezifisch festgelegt";
CM_ SG_ 192 EM1_Max_Moment_Gesamt "Maximal mögliches Moment bei der momentanen Maschinendrehzahl bezogen auf die im System verfügbare elektrische Gesamtleistung MO_EM1_Max_Leistung_Gesamt, motorischer Betrieb";
CM_ SG_ 192 EM1_Max_Moment_Lim "Maximales Moment bei der momentanen Maschinendrehzahl, motorischer Betrieb, berechnet aus Abregelstrom MO_EMx_Max_Strom_Lim und aktueller Spannung";
CM_ SG_ 192 EM1_Min_Moment "minimal darstellbares Moment für eine im Funktionslastenheft definierte Dauer

Die Berechnung der Momentengrenzen wird projektspezifisch festgelegt
";
CM_ SG_ 192 EM1_Min_Moment_Gesamt "Minimal mögliches Moment bei der momentanen Maschinendrehzahl bezogen auf die vom System aufnehmbare elektrische Gesamtleistung MO_EM1_Min_Leistung_Gesamt, generatorischer Betrieb";
CM_ SG_ 192 EM1_Min_Moment_Lim "Minimales Moment bei der momentanen Maschinendrehzahl, generatorischer Betrieb, berechnet aus Abregelstrom MO_EMx_Min_Strom_Lim und aktueller Spannung";
CM_ SG_ 192 EM1_Mom_DrzEingriff "Wirksames Moment der EM zum Begrenzen der Drehzahl auf Drehzahlbegrenzung";
CM_ SG_ 192 EM1_Moment_AR_Eingriff "Momentanwert: Eingriffsmoment der Anti-Ruckel-Funktion im PWR";
CM_ SG_ 192 EM1_Raddrehzahl_links "Momentanwert: Raddrehzahl links (Betrag)

Wird im PWR unter Nutzung der ESC-HW-Schnittstelle (Drehzahlfühler-Ausgänge im ESC) berechnet

Einschränkungen:
1. QM-Signal, kein ASIL möglich
2. Nur Betragswert möglich
3. Nach Stillstand oder Drehrichtun";
CM_ SG_ 192 EM1_Raddrehzahl_rechts "Momentanwert: Raddrehzahl rechts (Betrag)

Wird im PWR unter Nutzung der ESC-HW-Schnittstelle (Drehzahlfühler-Ausgänge im ESC) berechnet

Einschränkungen:
1. QM-Signal, kein ASIL möglich
2. Nur Betragswert möglich
3. Nach Stillstand oder Drehrichtu";
CM_ SG_ 192 EM1_Status_DrzEingriff "Status ASR-Eingriff über EM-Regelung";
CM_ SG_ 192 EM1_Strom_HV "Momentanwert: HV DC-Strom des PWR";

CM_ SG_ 184 EM1_Abregelung_Temperatur "Leistungsbegrenzung aufgrund Übertemperatur der E-Maschine / des PWR";
CM_ SG_ 184 EM1_AnlernenElMotor_Anf "Diagnoseanforderung von E-Maschine/PWR: Hybrid-Controller schaltet über MO_EM_Sollmodus=6 bzw. MY3_EM_modeReq=6 E-Maschine/PWR aktiv in den Kalibriermodus (Strategie muss sicherstellen, dass kein Moment bei der EM angefordert wird.)";
CM_ SG_ 184 EM1_AR_aktiv "Ruckeldämpfer aktiv";
CM_ SG_ 184 EM1_Eta_Sys "Instantaneous efficiency of electrical drive EM1 / Momentaner Wirkungsgrad elektrischer Antrieb EM1";
CM_ SG_ 184 EM1_Fehler_ElAntriebFreilauf_Anf "Wird gesetzt um den zwingenden Bedarf einer Umschaltung in den Freilauf anzuzeigen. Vergleiche Signal EM1_MaxZul_Drehzahl.";
CM_ SG_ 184 EM1_Freigabe_Info_WFS "WFS-Freigabeinformation";
CM_ SG_ 184 EM1_Freigabe_Verfallsinfo_WFS "WFS";
CM_ SG_ 184 EM1_HV_betriebsbereit "1: Ready_HV / 1: HV-Netz Spannung im Betriebsbereich";
CM_ SG_ 184 EM1_IstStrom "Momentanwert: Strom über PWR";
CM_ SG_ 184 EM1_Moment_HVVerbraucher "rechnerisch benötigtes Generator-Moment, um den Bedarf der el. Nebenverbraucher incl. Batterieladung abzudecken";
CM_ SG_ 184 EM1_Parken_WFS_Status "Status der Limitierung";
CM_ SG_ 184 EM1_Sperr_Info_WFS "WFS-Sperrinformation
";
CM_ SG_ 184 LE_Kuehlmittel_Sensor "Signal der Sensorelektroden für den Kühlmittelfüllstand aktuell, entstört, bewertet (OK/Mangel)";
BA_DEF_REL_ BU_SG_REL_  "GenSigTimeoutTime" INT 0 65535;
BA_DEF_ BO_  "DiagRequest" ENUM "No", "Yes";
BA_DEF_ BO_  "DiagResponse" ENUM "No", "Yes";
BA_DEF_ BO_  "DiagState" ENUM "No", "Yes";
BA_DEF_ BO_  "GenMsgChkConstant" HEX 0 4095;
BA_DEF_ BO_  "GenMsgCycleTime" INT 0 65535;
BA_DEF_ BO_  "GenMsgCycleTimeFast" INT 0 65535;
BA_DEF_ BO_  "GenMsgDelayTime" INT 0 100000;
BA_DEF_ BO_  "GenMsgILSupport" ENUM "No", "Yes";
BA_DEF_ BO_  "GenMsgNrOfRepetition" INT 0 100;
BA_DEF_ BO_  "GenMsgPDUConstants" STRING;
BA_DEF_ BO_  "GenMsgSendType" ENUM "Cyclic", "not_used", "not_used", "not_used", "not_used", "not_used", "not_used", "IfActive", "NoMsgSendType";
BA_DEF_ BO_  "GenMsgStartDelayTime" INT 0 100000;
BA_DEF_ BO_  "NmMessage" ENUM "No", "Yes";
BA_DEF_ BO_  "NmhMessage" ENUM "No", "Yes";
BA_DEF_ BO_  "MsgType" ENUM "Application", "NM ", "NMH", "TP2.0", "ISO-TP ", "BAP", "EID", "KS", "XCP_PRE_CONFIGURED", "XCP_RUNTIME_CONFIGURED";
BA_DEF_ BO_  "VAGTP20_API" HEX 0 255;
BA_DEF_ BO_  "VAGTP20_DynConnection" ENUM "No", "Yes";
BA_DEF_ BO_  "VAGTP20_DynSetup" ENUM "No", "Yes";
BA_DEF_ BO_  "VAGTP20_StatConnection" ENUM "No", "Yes";
BA_DEF_ BO_  "CANFD_BRS" ENUM "0", "1";
BA_DEF_ BO_  "VFrameFormat" ENUM "StandardCAN", "ExtendedCAN", "reserved", "reserved", "reserved", "reserved", "reserved", "reserved", "reserved", "reserved", "reserved", "reserved", "reserved", "reserved", "StandardCAN_FD", "ExtendedCAN_FD";
BA_DEF_ SG_  "GenSigActiveRepetitions" INT -2147483648 2147483647;
BA_DEF_ SG_  "GenSigInactiveValue" INT -2147483648 2147483647;
BA_DEF_ SG_  "GenSigSendType" ENUM "Cyclic", "OnWrite", "OnWriteWithRepetition", "OnChange", "OnChangeWithRepetition", "IfActive", "IfActiveWithRepetition", "NoSigSendType", "OnChangeAndIfActive", "OnChangeAndIfActiveWithRepetition";
BA_DEF_ SG_  "GenSigStartValue" INT -2147483648 2147483647;
BA_DEF_ SG_  "NWM-WakeupAllowed" ENUM "No", "Yes";
BA_DEF_ SG_  "GenSigFuncType" ENUM "NoFunction", "MsgCounter", "CRC-8", "XOR", "XOR-2", "DatedBit", "SW-Kl15", "CHK", "Constant", "Protocol", "CRC-8-SAE_J1850", "CRC-32", "DataLength", "DataID", "MsgCounter16", "SOK-Signatur", "Cluster";
BA_DEF_ SG_  "GenSigSwitchedByIgnition" ENUM "No", "Yes";
BA_DEF_ SG_  "Fehlerwert" HEX 0 2147483647;
BA_DEF_ SG_  "GenSigMissingSourceValue" HEX 0 2147483647;
BA_DEF_DEF_REL_  "GenSigTimeoutTime" 0;
BA_DEF_DEF_  "DiagRequest" "No";
BA_DEF_DEF_  "DiagResponse" "No";
BA_DEF_DEF_  "DiagState" "No";
BA_DEF_DEF_  "GenMsgChkConstant" 0;
BA_DEF_DEF_  "GenMsgCycleTime" 0;
BA_DEF_DEF_  "GenMsgCycleTimeFast" 0;
BA_DEF_DEF_  "GenMsgDelayTime" 0;
BA_DEF_DEF_  "GenMsgILSupport" "No";
BA_DEF_DEF_  "GenMsgNrOfRepetition" 0;
BA_DEF_DEF_  "GenMsgPDUConstants" "";
BA_DEF_DEF_  "GenMsgSendType" "NoMsgSendType";
BA_DEF_DEF_  "GenMsgStartDelayTime" 0;
BA_DEF_DEF_  "NmMessage" "No";
BA_DEF_DEF_  "NmhMessage" "No";
BA_DEF_DEF_  "MsgType" "Application";
BA_DEF_DEF_  "VAGTP20_API" 0;
BA_DEF_DEF_  "VAGTP20_DynConnection" "No";
BA_DEF_DEF_  "VAGTP20_DynSetup" "No";
BA_DEF_DEF_  "VAGTP20_StatConnection" "No";
BA_DEF_DEF_  "CANFD_BRS" "1";
BA_DEF_DEF_  "VFrameFormat" "StandardCAN";
BA_DEF_DEF_  "GenSigActiveRepetitions" 0;
BA_DEF_DEF_  "GenSigInactiveValue" 0;
BA_DEF_DEF_  "GenSigSendType" "NoSigSendType";
BA_DEF_DEF_  "GenSigStartValue" 0;
BA_DEF_DEF_  "NWM-WakeupAllowed" "No";
BA_DEF_DEF_  "GenSigFuncType" "NoFunction";
BA_DEF_DEF_  "GenSigSwitchedByIgnition" "Yes";
BA_DEF_DEF_  "Fehlerwert" 0;
BA_DEF_DEF_  "GenSigMissingSourceValue" 0;
BA_ "GenMsgCycleTime" BO_ 2463978705 100;
BA_ "GenMsgILSupport" BO_ 2463978705 1;
BA_ "GenMsgPDUConstants" BO_ 2463978705 "0x9e,0xf9,0x68,0xc0,0xa0,0x93,0xbd,0xed,0xe4,0x99,0x88,0x28,0x07,0x0c,0x60,0x67";
BA_ "GenMsgSendType" BO_ 2463978705 0;
BA_ "VFrameFormat" BO_ 2463978705 15;
BA_ "GenMsgCycleTime" BO_ 2589283664 500;
BA_ "GenMsgILSupport" BO_ 2589283664 1;
BA_ "GenMsgSendType" BO_ 2589283664 0;
BA_ "VFrameFormat" BO_ 2589283664 15;
BA_ "GenMsgCycleTime" BO_ 2589283665 500;
BA_ "GenMsgILSupport" BO_ 2589283665 1;
BA_ "GenMsgSendType" BO_ 2589283665 0;
BA_ "VFrameFormat" BO_ 2589283665 15;
BA_ "GenMsgCycleTime" BO_ 2589283760 1000;
BA_ "GenMsgILSupport" BO_ 2589283760 1;
BA_ "GenMsgSendType" BO_ 2589283760 0;
BA_ "VFrameFormat" BO_ 2589283760 15;
BA_ "GenMsgCycleTime" BO_ 2589283762 500;
BA_ "GenMsgILSupport" BO_ 2589283762 1;
BA_ "GenMsgSendType" BO_ 2589283762 0;
BA_ "VFrameFormat" BO_ 2589283762 15;
BA_ "GenMsgCycleTime" BO_ 2331595856 100;
BA_ "GenMsgDelayTime" BO_ 2331595856 10;
BA_ "GenMsgILSupport" BO_ 2331595856 1;
BA_ "GenMsgSendType" BO_ 2331595856 0;
BA_ "VFrameFormat" BO_ 2331595856 15;
BA_ "GenMsgCycleTime" BO_ 397 10;
BA_ "GenMsgILSupport" BO_ 397 1;
BA_ "GenMsgPDUConstants" BO_ 397 "0x9c,0xcc,0xe1,0x4c,0xc9,0x39,0xe3,0x53,0x78,0x33,0x15,0x49,0x55,0x0a,0x62,0x83";
BA_ "GenMsgSendType" BO_ 397 0;
BA_ "VFrameFormat" BO_ 397 14;
BA_ "GenMsgCycleTime" BO_ 419 20;
BA_ "GenMsgILSupport" BO_ 419 1;
BA_ "GenMsgSendType" BO_ 419 0;
BA_ "VFrameFormat" BO_ 419 14;
BA_ "GenMsgCycleTime" BO_ 2589283412 500;
BA_ "GenMsgILSupport" BO_ 2589283412 1;
BA_ "GenMsgSendType" BO_ 2589283412 0;
BA_ "VFrameFormat" BO_ 2589283412 15;
BA_ "GenMsgCycleTime" BO_ 2589283608 500;
BA_ "GenMsgILSupport" BO_ 2589283608 1;
BA_ "GenMsgSendType" BO_ 2589283608 0;
BA_ "VFrameFormat" BO_ 2589283608 15;
BA_ "GenMsgCycleTime" BO_ 2589283606 1000;
BA_ "GenMsgILSupport" BO_ 2589283606 1;
BA_ "GenMsgSendType" BO_ 2589283606 0;
BA_ "VFrameFormat" BO_ 2589283606 15;
BA_ "GenMsgCycleTime" BO_ 1021 100;
BA_ "GenMsgILSupport" BO_ 1021 1;
BA_ "GenMsgSendType" BO_ 1021 0;
BA_ "VFrameFormat" BO_ 1021 14;
BA_ "GenMsgCycleTime" BO_ 2463978716 100;
BA_ "GenMsgDelayTime" BO_ 2463978716 10;
BA_ "GenMsgILSupport" BO_ 2463978716 1;
BA_ "GenMsgPDUConstants" BO_ 2463978716 "0x4e,0x5e,0x5a,0xed,0x29,0x2e,0x91,0x2d,0xc6,0xde,0x1b,0x98,0x92,0x8b,0x52,0x8a";
BA_ "GenMsgSendType" BO_ 2463978716 0;
BA_ "VFrameFormat" BO_ 2463978716 15;
BA_ "GenMsgCycleTime" BO_ 2463978717 100;
BA_ "GenMsgILSupport" BO_ 2463978717 1;
BA_ "GenMsgSendType" BO_ 2463978717 0;
BA_ "VFrameFormat" BO_ 2463978717 15;
BA_ "GenMsgCycleTime" BO_ 2463978718 100;
BA_ "GenMsgILSupport" BO_ 2463978718 1;
BA_ "GenMsgPDUConstants" BO_ 2463978718 "0x28,0x30,0x1f,0x9e,0x51,0xab,0x2f,0xd3,0x39,0x6f,0x37,0xfa,0x59,0xa4,0x70,0xce";
BA_ "GenMsgSendType" BO_ 2463978718 0;
BA_ "VFrameFormat" BO_ 2463978718 15;
BA_ "GenMsgCycleTime" BO_ 2589283523 500;
BA_ "GenMsgDelayTime" BO_ 2589283523 50;
BA_ "GenMsgILSupport" BO_ 2589283523 1;
BA_ "GenMsgSendType" BO_ 2589283523 0;
BA_ "VFrameFormat" BO_ 2589283523 15;
BA_ "GenMsgCycleTime" BO_ 2589283543 500;
BA_ "GenMsgDelayTime" BO_ 2589283543 50;
BA_ "GenMsgSendType" BO_ 2589283543 0;
BA_ "VFrameFormat" BO_ 2589283543 15;
BA_ "GenMsgCycleTime" BO_ 2589283524 500;
BA_ "GenMsgDelayTime" BO_ 2589283524 50;
BA_ "GenMsgILSupport" BO_ 2589283524 1;
BA_ "GenMsgSendType" BO_ 2589283524 0;
BA_ "VFrameFormat" BO_ 2589283524 15;
BA_ "GenMsgCycleTime" BO_ 2527679928 500;
BA_ "GenMsgILSupport" BO_ 2527679928 1;
BA_ "GenMsgSendType" BO_ 2527679928 0;
BA_ "VFrameFormat" BO_ 2527679928 15;
BA_ "GenMsgCycleTime" BO_ 2463978646 1000;
BA_ "GenMsgDelayTime" BO_ 2463978646 50;
BA_ "GenMsgILSupport" BO_ 2463978646 1;
BA_ "GenMsgSendType" BO_ 2463978646 0;
BA_ "VFrameFormat" BO_ 2463978646 15;
BA_ "GenMsgCycleTime" BO_ 1485 500;
BA_ "GenMsgCycleTimeFast" BO_ 1485 100;
BA_ "GenMsgDelayTime" BO_ 1485 50;
BA_ "GenMsgILSupport" BO_ 1485 1;
BA_ "GenMsgNrOfRepetition" BO_ 1485 5;
BA_ "GenMsgPDUConstants" BO_ 1485 "0x93,0x04,0x18,0x69,0xce,0x8f,0xb1,0x53,0x40,0x2d,0xe4,0xca,0x90,0x25,0x79,0x8c";
BA_ "GenMsgSendType" BO_ 1485 0;
BA_ "VFrameFormat" BO_ 1485 14;
BA_ "GenMsgCycleTime" BO_ 1486 500;
BA_ "GenMsgCycleTimeFast" BO_ 1486 100;
BA_ "GenMsgDelayTime" BO_ 1486 50;
BA_ "GenMsgNrOfRepetition" BO_ 1486 5;
BA_ "GenMsgSendType" BO_ 1486 0;
BA_ "VFrameFormat" BO_ 1486 14;
BA_ "GenMsgCycleTime" BO_ 247 10;
BA_ "GenMsgILSupport" BO_ 247 1;
BA_ "GenMsgPDUConstants" BO_ 247 "0x5f,0xa0,0x44,0xd0,0x63,0x59,0x5b,0xa2,0x68,0x04,0x90,0x87,0x52,0x12,0xb4,0x9e";
BA_ "GenMsgSendType" BO_ 247 0;
BA_ "VFrameFormat" BO_ 247 14;
BA_ "GenMsgCycleTime" BO_ 1484 500;
BA_ "GenMsgDelayTime" BO_ 1484 50;
BA_ "GenMsgILSupport" BO_ 1484 1;
BA_ "GenMsgPDUConstants" BO_ 1484 "0x60,0x76,0x27,0x02,0x3a,0xa8,0x32,0x51,0x8b,0x23,0x1c,0xf4,0xf0,0x97,0x5b,0x07";
BA_ "GenMsgSendType" BO_ 1484 0;
BA_ "VFrameFormat" BO_ 1484 14;
BA_ "MsgType" BO_ 2617227808 6;
BA_ "VFrameFormat" BO_ 2617227808 15;
BA_ "MsgType" BO_ 2617227809 6;
BA_ "VFrameFormat" BO_ 2617227809 15;
BA_ "MsgType" BO_ 2566865408 6;
BA_ "VFrameFormat" BO_ 2566865408 15;
BA_ "MsgType" BO_ 2566865663 6;
BA_ "VFrameFormat" BO_ 2566865663 15;
BA_ "MsgType" BO_ 2617154048 6;
BA_ "VFrameFormat" BO_ 2617154048 15;
BA_ "MsgType" BO_ 2617154049 6;
BA_ "VFrameFormat" BO_ 2617154049 15;
BA_ "MsgType" BO_ 2617154050 6;
BA_ "VFrameFormat" BO_ 2617154050 15;
BA_ "MsgType" BO_ 2617154051 6;
BA_ "VFrameFormat" BO_ 2617154051 15;
BA_ "MsgType" BO_ 2617154052 6;
BA_ "VFrameFormat" BO_ 2617154052 15;
BA_ "MsgType" BO_ 2617154053 6;
BA_ "VFrameFormat" BO_ 2617154053 15;
BA_ "DiagRequest" BO_ 2549880589 1;
BA_ "MsgType" BO_ 2549880589 4;
BA_ "VFrameFormat" BO_ 2549880589 15;
BA_ "DiagResponse" BO_ 2550011661 1;
BA_ "MsgType" BO_ 2550011661 4;
BA_ "VFrameFormat" BO_ 2550011661 15;
BA_ "DiagRequest" BO_ 2549880644 1;
BA_ "MsgType" BO_ 2549880644 4;
BA_ "VFrameFormat" BO_ 2549880644 15;
BA_ "DiagResponse" BO_ 2550011716 1;
BA_ "MsgType" BO_ 2550011716 4;
BA_ "VFrameFormat" BO_ 2550011716 15;
BA_ "DiagRequest" BO_ 2549880568 1;
BA_ "MsgType" BO_ 2549880568 4;
BA_ "VFrameFormat" BO_ 2549880568 15;
BA_ "DiagResponse" BO_ 2550011640 1;
BA_ "MsgType" BO_ 2550011640 4;
BA_ "VFrameFormat" BO_ 2550011640 15;
BA_ "DiagRequest" BO_ 2549880642 1;
BA_ "MsgType" BO_ 2549880642 4;
BA_ "VFrameFormat" BO_ 2549880642 15;
BA_ "DiagRequest" BO_ 2621445954 1;
BA_ "MsgType" BO_ 2621445954 4;
BA_ "VFrameFormat" BO_ 2621445954 15;
BA_ "DiagResponse" BO_ 2550011714 1;
BA_ "MsgType" BO_ 2550011714 4;
BA_ "VFrameFormat" BO_ 2550011714 15;
BA_ "DiagResponse" BO_ 2621577026 1;
BA_ "MsgType" BO_ 2621577026 4;
BA_ "VFrameFormat" BO_ 2621577026 15;
BA_ "DiagRequest" BO_ 2549876546 1;
BA_ "MsgType" BO_ 2549876546 4;
BA_ "VFrameFormat" BO_ 2549876546 15;
BA_ "DiagResponse" BO_ 2550007618 1;
BA_ "MsgType" BO_ 2550007618 4;
BA_ "VFrameFormat" BO_ 2550007618 15;
BA_ "DiagRequest" BO_ 2549876269 1;
BA_ "MsgType" BO_ 2549876269 4;
BA_ "VFrameFormat" BO_ 2549876269 15;
BA_ "DiagResponse" BO_ 2550007341 1;
BA_ "MsgType" BO_ 2550007341 4;
BA_ "VFrameFormat" BO_ 2550007341 15;
BA_ "GenMsgCycleTime" BO_ 1714 1000;
BA_ "GenMsgILSupport" BO_ 1714 1;
BA_ "GenMsgSendType" BO_ 1714 0;
BA_ "VFrameFormat" BO_ 1714 14;
BA_ "GenMsgCycleTime" BO_ 1520 200;
BA_ "GenMsgDelayTime" BO_ 1520 50;
BA_ "GenMsgILSupport" BO_ 1520 1;
BA_ "GenMsgSendType" BO_ 1520 0;
BA_ "VFrameFormat" BO_ 1520 14;
BA_ "GenMsgCycleTime" BO_ 420 500;
BA_ "GenMsgCycleTimeFast" BO_ 420 20;
BA_ "GenMsgDelayTime" BO_ 420 20;
BA_ "GenMsgILSupport" BO_ 420 1;
BA_ "GenMsgNrOfRepetition" BO_ 420 5;
BA_ "GenMsgPDUConstants" BO_ 420 "0x69,0xbb,0x54,0xe6,0x4e,0x46,0x8d,0x7b,0xea,0x87,0xe9,0xb3,0x63,0xce,0xf8,0xbf";
BA_ "GenMsgSendType" BO_ 420 0;
BA_ "VFrameFormat" BO_ 420 14;
BA_ "GenMsgCycleTime" BO_ 374 20;
BA_ "GenMsgILSupport" BO_ 374 1;
BA_ "GenMsgPDUConstants" BO_ 374 "0x3c,0x60,0xeb,0x76,0x91,0x27,0x04,0x02,0xa4,0x3a,0x3f,0xa8,0x24,0x32,0x38,0x51";
BA_ "GenMsgSendType" BO_ 374 0;
BA_ "VFrameFormat" BO_ 374 14;
BA_ "GenMsgCycleTime" BO_ 2589283963 500;
BA_ "GenMsgILSupport" BO_ 2589283963 1;
BA_ "GenMsgSendType" BO_ 2589283963 0;
BA_ "VFrameFormat" BO_ 2589283963 15;
BA_ "GenMsgCycleTime" BO_ 1603 1000;
BA_ "GenMsgDelayTime" BO_ 1603 100;
BA_ "GenMsgILSupport" BO_ 1603 1;
BA_ "GenMsgSendType" BO_ 1603 0;
BA_ "VFrameFormat" BO_ 1603 14;
BA_ "GenMsgCycleTime" BO_ 192 10;
BA_ "GenMsgILSupport" BO_ 192 1;
BA_ "GenMsgPDUConstants" BO_ 192 "0x2f,0x44,0x72,0xd3,0x07,0xf2,0x39,0x09,0x8d,0x6f,0x57,0x20,0x37,0xf9,0x9b,0xfa";
BA_ "GenMsgSendType" BO_ 192 0;
BA_ "VFrameFormat" BO_ 192 14;
BA_ "GenMsgCycleTime" BO_ 184 500;
BA_ "GenMsgDelayTime" BO_ 184 20;
BA_ "GenMsgILSupport" BO_ 184 1;
BA_ "GenMsgSendType" BO_ 184 0;
BA_ "VFrameFormat" BO_ 184 14;
BA_ "GenSigSendType" SG_ 2463978705 BMS_22_BZ 0;
BA_ "GenSigFuncType" SG_ 2463978705 BMS_22_BZ 1;
BA_ "GenSigSwitchedByIgnition" SG_ 2463978705 BMS_22_BZ 0;
BA_ "GenSigSendType" SG_ 2463978705 BMS_22_CRC 0;
BA_ "GenSigFuncType" SG_ 2463978705 BMS_22_CRC 2;
BA_ "GenSigSwitchedByIgnition" SG_ 2463978705 BMS_22_CRC 0;
BA_ "GenSigSendType" SG_ 2463978705 BMS_Ladezustand 0;
BA_ "GenSigStartValue" SG_ 2463978705 BMS_Ladezustand 2046;
BA_ "GenSigSwitchedByIgnition" SG_ 2463978705 BMS_Ladezustand 0;
BA_ "Fehlerwert" SG_ 2463978705 BMS_Ladezustand 2047;
BA_ "GenSigSendType" SG_ 2463978705 BMS_Nutzbare_EntladeEnergie 0;
BA_ "GenSigStartValue" SG_ 2463978705 BMS_Nutzbare_EntladeEnergie 65534;
BA_ "GenSigSwitchedByIgnition" SG_ 2463978705 BMS_Nutzbare_EntladeEnergie 0;
BA_ "Fehlerwert" SG_ 2463978705 BMS_Nutzbare_EntladeEnergie 65535;
BA_ "GenSigSendType" SG_ 2463978705 BMS_PerfInd_Entladen 0;
BA_ "GenSigStartValue" SG_ 2463978705 BMS_PerfInd_Entladen 1022;
BA_ "GenSigSwitchedByIgnition" SG_ 2463978705 BMS_PerfInd_Entladen 0;
BA_ "GenSigSendType" SG_ 2463978705 BMS_PerfInd_Laden 0;
BA_ "GenSigStartValue" SG_ 2463978705 BMS_PerfInd_Laden 1022;
BA_ "GenSigSwitchedByIgnition" SG_ 2463978705 BMS_PerfInd_Laden 0;
BA_ "GenSigSendType" SG_ 2463978705 BMS_Status_EoHVL_Heizer 0;
BA_ "GenSigSwitchedByIgnition" SG_ 2463978705 BMS_Status_EoHVL_Heizer 0;
BA_ "Fehlerwert" SG_ 2463978705 BMS_Status_EoHVL_Heizer 3;
BA_ "GenSigSendType" SG_ 2463978705 BMS_Warnung_Stuetzung_NV 0;
BA_ "GenSigStartValue" SG_ 2463978705 BMS_Warnung_Stuetzung_NV 6;
BA_ "GenSigSwitchedByIgnition" SG_ 2463978705 BMS_Warnung_Stuetzung_NV 0;
BA_ "Fehlerwert" SG_ 2463978705 BMS_Warnung_Stuetzung_NV 7;
BA_ "GenSigSendType" SG_ 2589283664 BMS_Balancing_Aktiv 0;
BA_ "GenSigSwitchedByIgnition" SG_ 2589283664 BMS_Balancing_Aktiv 0;
BA_ "GenSigSendType" SG_ 2589283664 BMS_Ladevorgang_aktiv 0;
BA_ "GenSigSwitchedByIgnition" SG_ 2589283664 BMS_Ladevorgang_aktiv 0;
BA_ "GenSigSendType" SG_ 2589283664 BMS_Max_Energie 0;
BA_ "GenSigStartValue" SG_ 2589283664 BMS_Max_Energie 8190;
BA_ "GenSigSwitchedByIgnition" SG_ 2589283664 BMS_Max_Energie 0;
BA_ "GenSigSendType" SG_ 2589283664 BMS_Max_Ladezustand 0;
BA_ "GenSigStartValue" SG_ 2589283664 BMS_Max_Ladezustand 2046;
BA_ "GenSigSwitchedByIgnition" SG_ 2589283664 BMS_Max_Ladezustand 0;
BA_ "GenSigSendType" SG_ 2589283664 BMS_Min_Ladezustand 0;
BA_ "GenSigStartValue" SG_ 2589283664 BMS_Min_Ladezustand 2046;
BA_ "GenSigSwitchedByIgnition" SG_ 2589283664 BMS_Min_Ladezustand 0;
BA_ "GenSigSendType" SG_ 2589283664 BMS_RIso_Ext 0;
BA_ "GenSigStartValue" SG_ 2589283664 BMS_RIso_Ext 4094;
BA_ "GenSigSwitchedByIgnition" SG_ 2589283664 BMS_RIso_Ext 0;
BA_ "Fehlerwert" SG_ 2589283664 BMS_RIso_Ext 4095;
BA_ "GenSigSendType" SG_ 2589283665 BMS_BattHeizung_VerbautStatus 0;
BA_ "GenSigSwitchedByIgnition" SG_ 2589283665 BMS_BattHeizung_VerbautStatus 0;
BA_ "GenSigSendType" SG_ 2589283665 BMS_Fehler_NTKreis 0;
BA_ "GenSigSwitchedByIgnition" SG_ 2589283665 BMS_Fehler_NTKreis 0;
BA_ "Fehlerwert" SG_ 2589283665 BMS_Fehler_NTKreis 1;
BA_ "GenSigSendType" SG_ 2589283665 BMS_Pumpe1_Ansteuerung 0;
BA_ "GenSigStartValue" SG_ 2589283665 BMS_Pumpe1_Ansteuerung 14;
BA_ "GenSigSwitchedByIgnition" SG_ 2589283665 BMS_Pumpe1_Ansteuerung 0;
BA_ "Fehlerwert" SG_ 2589283665 BMS_Pumpe1_Ansteuerung 15;
BA_ "GenSigSendType" SG_ 2589283665 BMS_Pumpe2_Ansteuerung 0;
BA_ "GenSigStartValue" SG_ 2589283665 BMS_Pumpe2_Ansteuerung 14;
BA_ "GenSigSwitchedByIgnition" SG_ 2589283665 BMS_Pumpe2_Ansteuerung 0;
BA_ "Fehlerwert" SG_ 2589283665 BMS_Pumpe2_Ansteuerung 15;
BA_ "GenSigSendType" SG_ 2589283665 BMS_RuecklaufTemperatur 0;
BA_ "GenSigStartValue" SG_ 2589283665 BMS_RuecklaufTemperatur 254;
BA_ "GenSigSwitchedByIgnition" SG_ 2589283665 BMS_RuecklaufTemperatur 0;
BA_ "Fehlerwert" SG_ 2589283665 BMS_RuecklaufTemperatur 255;
BA_ "GenSigSendType" SG_ 2589283665 BMS_SollVorlauftemperatur 0;
BA_ "GenSigStartValue" SG_ 2589283665 BMS_SollVorlauftemperatur 254;
BA_ "GenSigSwitchedByIgnition" SG_ 2589283665 BMS_SollVorlauftemperatur 0;
BA_ "Fehlerwert" SG_ 2589283665 BMS_SollVorlauftemperatur 255;
BA_ "GenSigSendType" SG_ 2589283665 BMS_Status_Ventil1 0;
BA_ "GenSigStartValue" SG_ 2589283665 BMS_Status_Ventil1 6;
BA_ "GenSigSwitchedByIgnition" SG_ 2589283665 BMS_Status_Ventil1 0;
BA_ "Fehlerwert" SG_ 2589283665 BMS_Status_Ventil1 7;
BA_ "GenSigSendType" SG_ 2589283665 BMS_Status_Ventil2 0;
BA_ "GenSigStartValue" SG_ 2589283665 BMS_Status_Ventil2 6;
BA_ "GenSigSwitchedByIgnition" SG_ 2589283665 BMS_Status_Ventil2 0;
BA_ "Fehlerwert" SG_ 2589283665 BMS_Status_Ventil2 7;
BA_ "GenSigSendType" SG_ 2589283665 BMS_Temperatur 0;
BA_ "GenSigStartValue" SG_ 2589283665 BMS_Temperatur 254;
BA_ "GenSigSwitchedByIgnition" SG_ 2589283665 BMS_Temperatur 0;
BA_ "Fehlerwert" SG_ 2589283665 BMS_Temperatur 255;
BA_ "GenSigSendType" SG_ 2589283665 BMS_Temperierung_Anf 0;
BA_ "GenSigStartValue" SG_ 2589283665 BMS_Temperierung_Anf 3;
BA_ "GenSigSwitchedByIgnition" SG_ 2589283665 BMS_Temperierung_Anf 0;
BA_ "GenSigSendType" SG_ 2589283665 BMS_VorlaufTemperatur 0;
BA_ "GenSigStartValue" SG_ 2589283665 BMS_VorlaufTemperatur 254;
BA_ "GenSigSwitchedByIgnition" SG_ 2589283665 BMS_VorlaufTemperatur 0;
BA_ "Fehlerwert" SG_ 2589283665 BMS_VorlaufTemperatur 255;
BA_ "GenSigSendType" SG_ 2589283760 BMS_Dauer_Entladeleistung 0;
BA_ "GenSigStartValue" SG_ 2589283760 BMS_Dauer_Entladeleistung 4094;
BA_ "GenSigSwitchedByIgnition" SG_ 2589283760 BMS_Dauer_Entladeleistung 0;
BA_ "GenSigSendType" SG_ 2589283760 BMS_Dauer_Ladeleistung 0;
BA_ "GenSigStartValue" SG_ 2589283760 BMS_Dauer_Ladeleistung 4094;
BA_ "GenSigSwitchedByIgnition" SG_ 2589283760 BMS_Dauer_Ladeleistung 0;
BA_ "GenSigSendType" SG_ 2589283760 BMS_Max_Spannung 0;
BA_ "GenSigStartValue" SG_ 2589283760 BMS_Max_Spannung 1022;
BA_ "GenSigSwitchedByIgnition" SG_ 2589283760 BMS_Max_Spannung 0;
BA_ "GenSigSendType" SG_ 2589283760 BMS_Min_Spannung 0;
BA_ "GenSigStartValue" SG_ 2589283760 BMS_Min_Spannung 1022;
BA_ "GenSigSwitchedByIgnition" SG_ 2589283760 BMS_Min_Spannung 0;
BA_ "GenSigSendType" SG_ 2589283762 BMS_eTM_KonditionierWunsch 0;
BA_ "GenSigSendType" SG_ 2589283762 BMS_PerfInd_EntladenPeak_Temp 0;
BA_ "GenSigStartValue" SG_ 2589283762 BMS_PerfInd_EntladenPeak_Temp 510;
BA_ "GenSigSwitchedByIgnition" SG_ 2589283762 BMS_PerfInd_EntladenPeak_Temp 0;
BA_ "Fehlerwert" SG_ 2589283762 BMS_PerfInd_EntladenPeak_Temp 511;
BA_ "GenSigSendType" SG_ 2589283762 BMS_PerfInd_LadenPeak_Temp 0;
BA_ "GenSigStartValue" SG_ 2589283762 BMS_PerfInd_LadenPeak_Temp 510;
BA_ "GenSigSwitchedByIgnition" SG_ 2589283762 BMS_PerfInd_LadenPeak_Temp 0;
BA_ "Fehlerwert" SG_ 2589283762 BMS_PerfInd_LadenPeak_Temp 511;
BA_ "GenSigSendType" SG_ 2589283762 BMS_SollVolumenstrom 0;
BA_ "GenSigStartValue" SG_ 2589283762 BMS_SollVolumenstrom 62;
BA_ "GenSigSwitchedByIgnition" SG_ 2589283762 BMS_SollVolumenstrom 0;
BA_ "Fehlerwert" SG_ 2589283762 BMS_SollVolumenstrom 63;
BA_ "GenSigSendType" SG_ 2589283762 BMS_TempStatus_Entladen 0;
BA_ "GenSigSwitchedByIgnition" SG_ 2589283762 BMS_TempStatus_Entladen 0;
BA_ "Fehlerwert" SG_ 2589283762 BMS_TempStatus_Entladen 7;
BA_ "GenSigSendType" SG_ 2589283762 BMS_TempStatus_Laden 0;
BA_ "GenSigSwitchedByIgnition" SG_ 2589283762 BMS_TempStatus_Laden 0;
BA_ "Fehlerwert" SG_ 2589283762 BMS_TempStatus_Laden 7;
BA_ "GenSigSendType" SG_ 2589283762 BMS_TMA_Betriebsart 0;
BA_ "GenSigStartValue" SG_ 2589283762 BMS_TMA_Betriebsart 30;
BA_ "GenSigSwitchedByIgnition" SG_ 2589283762 BMS_TMA_Betriebsart 0;
BA_ "Fehlerwert" SG_ 2589283762 BMS_TMA_Betriebsart 31;
BA_ "GenSigSendType" SG_ 2589283762 BMS_TMA_Kuehlkreis_Status 0;
BA_ "Fehlerwert" SG_ 2589283762 BMS_TMA_Kuehlkreis_Status 15;
BA_ "GenSigSendType" SG_ 2331595856 BMS_DC_Ladeschuetze_Ist 3;
BA_ "GenSigStartValue" SG_ 2331595856 BMS_DC_Ladeschuetze_Ist 6;
BA_ "GenSigSwitchedByIgnition" SG_ 2331595856 BMS_DC_Ladeschuetze_Ist 0;
BA_ "GenSigSendType" SG_ 2331595856 BMS_EnergieVorhalt 0;
BA_ "GenSigStartValue" SG_ 2331595856 BMS_EnergieVorhalt 65534;
BA_ "GenSigSwitchedByIgnition" SG_ 2331595856 BMS_EnergieVorhalt 0;
BA_ "Fehlerwert" SG_ 2331595856 BMS_EnergieVorhalt 65535;
BA_ "GenSigSendType" SG_ 2331595856 BMS_Hauptschuetze_Ist 3;
BA_ "GenSigStartValue" SG_ 2331595856 BMS_Hauptschuetze_Ist 6;
BA_ "GenSigSwitchedByIgnition" SG_ 2331595856 BMS_Hauptschuetze_Ist 0;
BA_ "GenSigSendType" SG_ 2331595856 BMS_Last_Chg_adeq_SOCswing_Day 0;
BA_ "GenSigSwitchedByIgnition" SG_ 2331595856 BMS_Last_Chg_adeq_SOCswing_Day 0;
BA_ "GenSigSendType" SG_ 2331595856 BMS_Last_Chg_adeq_SOCswing_Month 0;
BA_ "GenSigSwitchedByIgnition" SG_ 2331595856 BMS_Last_Chg_adeq_SOCswing_Month 0;
BA_ "GenSigSendType" SG_ 2331595856 BMS_Last_Chg_adeq_SOCswing_Year 0;
BA_ "GenSigSwitchedByIgnition" SG_ 2331595856 BMS_Last_Chg_adeq_SOCswing_Year 0;
BA_ "GenSigSendType" SG_ 2331595856 BMS_Max_UBE 0;
BA_ "GenSigStartValue" SG_ 2331595856 BMS_Max_UBE 65534;
BA_ "GenSigSwitchedByIgnition" SG_ 2331595856 BMS_Max_UBE 0;
BA_ "Fehlerwert" SG_ 2331595856 BMS_Max_UBE 65535;
BA_ "GenSigSendType" SG_ 2331595856 BMS_Nennspannung 0;
BA_ "GenSigStartValue" SG_ 2331595856 BMS_Nennspannung 2046;
BA_ "GenSigSwitchedByIgnition" SG_ 2331595856 BMS_Nennspannung 0;
BA_ "GenSigSendType" SG_ 2331595856 BMS_Range_Indikator 0;
BA_ "GenSigStartValue" SG_ 2331595856 BMS_Range_Indikator 2046;
BA_ "GenSigSwitchedByIgnition" SG_ 2331595856 BMS_Range_Indikator 0;
BA_ "Fehlerwert" SG_ 2331595856 BMS_Range_Indikator 2047;
BA_ "GenSigSendType" SG_ 2331595856 BMS_UBE 0;
BA_ "GenSigStartValue" SG_ 2331595856 BMS_UBE 65534;
BA_ "GenSigSwitchedByIgnition" SG_ 2331595856 BMS_UBE 0;
BA_ "Fehlerwert" SG_ 2331595856 BMS_UBE 65535;
BA_ "GenSigSendType" SG_ 2331595856 BMS_UBE_Indik_last_update_km 0;
BA_ "GenSigStartValue" SG_ 2331595856 BMS_UBE_Indik_last_update_km 1048574;
BA_ "GenSigSwitchedByIgnition" SG_ 2331595856 BMS_UBE_Indik_last_update_km 0;
BA_ "Fehlerwert" SG_ 2331595856 BMS_UBE_Indik_last_update_km 1048575;
BA_ "GenSigSendType" SG_ 2331595856 BMS_UBE_Indikator 0;
BA_ "GenSigStartValue" SG_ 2331595856 BMS_UBE_Indikator 2046;
BA_ "GenSigSwitchedByIgnition" SG_ 2331595856 BMS_UBE_Indikator 0;
BA_ "Fehlerwert" SG_ 2331595856 BMS_UBE_Indikator 2047;
BA_ "GenSigSendType" SG_ 2331595856 BMS_UBE_T 0;
BA_ "GenSigStartValue" SG_ 2331595856 BMS_UBE_T 65534;
BA_ "GenSigSwitchedByIgnition" SG_ 2331595856 BMS_UBE_T 0;
BA_ "Fehlerwert" SG_ 2331595856 BMS_UBE_T 65535;
BA_ "GenSigSendType" SG_ 2331595856 SOK_BMS_34_Signatur 0;
BA_ "GenSigFuncType" SG_ 2331595856 SOK_BMS_34_Signatur 15;
BA_ "GenSigSwitchedByIgnition" SG_ 2331595856 SOK_BMS_34_Signatur 0;
BA_ "GenSigSendType" SG_ 397 BMS_MV_01_BZ 0;
BA_ "GenSigFuncType" SG_ 397 BMS_MV_01_BZ 1;
BA_ "GenSigSwitchedByIgnition" SG_ 397 BMS_MV_01_BZ 0;
BA_ "GenSigSendType" SG_ 397 BMS_MV_01_CRC 0;
BA_ "GenSigFuncType" SG_ 397 BMS_MV_01_CRC 2;
BA_ "GenSigSwitchedByIgnition" SG_ 397 BMS_MV_01_CRC 0;
BA_ "GenSigSendType" SG_ 397 BMS_MV_IstSpannung 0;
BA_ "GenSigStartValue" SG_ 397 BMS_MV_IstSpannung 254;
BA_ "GenSigSwitchedByIgnition" SG_ 397 BMS_MV_IstSpannung 0;
BA_ "Fehlerwert" SG_ 397 BMS_MV_IstSpannung 255;
BA_ "GenSigSendType" SG_ 397 BMS_MV_IstSpannung_Zwkr 0;
BA_ "GenSigStartValue" SG_ 397 BMS_MV_IstSpannung_Zwkr 254;
BA_ "GenSigSwitchedByIgnition" SG_ 397 BMS_MV_IstSpannung_Zwkr 0;
BA_ "Fehlerwert" SG_ 397 BMS_MV_IstSpannung_Zwkr 255;
BA_ "GenSigSendType" SG_ 397 BMS_MV_IstStrom 0;
BA_ "GenSigStartValue" SG_ 397 BMS_MV_IstStrom 4094;
BA_ "GenSigSwitchedByIgnition" SG_ 397 BMS_MV_IstStrom 0;
BA_ "Fehlerwert" SG_ 397 BMS_MV_IstStrom 4095;
BA_ "GenSigSendType" SG_ 397 BMS_MV_SOC_HiRes 0;
BA_ "GenSigStartValue" SG_ 397 BMS_MV_SOC_HiRes 2046;
BA_ "GenSigSwitchedByIgnition" SG_ 397 BMS_MV_SOC_HiRes 0;
BA_ "Fehlerwert" SG_ 397 BMS_MV_SOC_HiRes 2047;
BA_ "GenSigSendType" SG_ 419 BMS_MV_MaxDyn_EntladeStrom 0;
BA_ "GenSigStartValue" SG_ 419 BMS_MV_MaxDyn_EntladeStrom 2046;
BA_ "GenSigSwitchedByIgnition" SG_ 419 BMS_MV_MaxDyn_EntladeStrom 0;
BA_ "Fehlerwert" SG_ 419 BMS_MV_MaxDyn_EntladeStrom 2047;
BA_ "GenSigSendType" SG_ 419 BMS_MV_MaxDyn_LadeStrom 0;
BA_ "GenSigStartValue" SG_ 419 BMS_MV_MaxDyn_LadeStrom 2046;
BA_ "GenSigSwitchedByIgnition" SG_ 419 BMS_MV_MaxDyn_LadeStrom 0;
BA_ "Fehlerwert" SG_ 419 BMS_MV_MaxDyn_LadeStrom 2047;
BA_ "GenSigSendType" SG_ 419 BMS_MV_Min_EntladeSpannung 0;
BA_ "GenSigStartValue" SG_ 419 BMS_MV_Min_EntladeSpannung 254;
BA_ "GenSigSwitchedByIgnition" SG_ 419 BMS_MV_Min_EntladeSpannung 0;
BA_ "Fehlerwert" SG_ 419 BMS_MV_Min_EntladeSpannung 255;
BA_ "GenSigSendType" SG_ 419 BMS_MV_MinDyn_LadeSpannung 0;
BA_ "GenSigStartValue" SG_ 419 BMS_MV_MinDyn_LadeSpannung 254;
BA_ "GenSigSwitchedByIgnition" SG_ 419 BMS_MV_MinDyn_LadeSpannung 0;
BA_ "GenSigSendType" SG_ 419 BMS_MV_MinDynEntladeSpannung 0;
BA_ "GenSigStartValue" SG_ 419 BMS_MV_MinDynEntladeSpannung 254;
BA_ "GenSigSwitchedByIgnition" SG_ 419 BMS_MV_MinDynEntladeSpannung 0;
BA_ "GenSigSendType" SG_ 2589283412 BMS_MV_IstRuecklaufTemperatur 0;
BA_ "GenSigStartValue" SG_ 2589283412 BMS_MV_IstRuecklaufTemperatur 254;
BA_ "GenSigSwitchedByIgnition" SG_ 2589283412 BMS_MV_IstRuecklaufTemperatur 0;
BA_ "Fehlerwert" SG_ 2589283412 BMS_MV_IstRuecklaufTemperatur 255;
BA_ "GenSigSendType" SG_ 2589283412 BMS_MV_IstVorlaufTemperatur 0;
BA_ "GenSigStartValue" SG_ 2589283412 BMS_MV_IstVorlaufTemperatur 254;
BA_ "GenSigSwitchedByIgnition" SG_ 2589283412 BMS_MV_IstVorlaufTemperatur 0;
BA_ "Fehlerwert" SG_ 2589283412 BMS_MV_IstVorlaufTemperatur 255;
BA_ "GenSigSendType" SG_ 2589283412 BMS_MV_Soll_PWM_Pumpe 0;
BA_ "GenSigStartValue" SG_ 2589283412 BMS_MV_Soll_PWM_Pumpe 15;
BA_ "GenSigSwitchedByIgnition" SG_ 2589283412 BMS_MV_Soll_PWM_Pumpe 0;
BA_ "GenSigSendType" SG_ 2589283412 BMS_MV_SollVolumenstrom 0;
BA_ "GenSigStartValue" SG_ 2589283412 BMS_MV_SollVolumenstrom 62;
BA_ "GenSigSwitchedByIgnition" SG_ 2589283412 BMS_MV_SollVolumenstrom 0;
BA_ "Fehlerwert" SG_ 2589283412 BMS_MV_SollVolumenstrom 63;
BA_ "GenSigSendType" SG_ 2589283412 BMS_MV_SollVorlauftemperatur 0;
BA_ "GenSigStartValue" SG_ 2589283412 BMS_MV_SollVorlauftemperatur 254;
BA_ "GenSigSwitchedByIgnition" SG_ 2589283412 BMS_MV_SollVorlauftemperatur 0;
BA_ "Fehlerwert" SG_ 2589283412 BMS_MV_SollVorlauftemperatur 255;
BA_ "GenSigSendType" SG_ 2589283412 BMS_MV_Speichertechnologie 0;
BA_ "GenSigSwitchedByIgnition" SG_ 2589283412 BMS_MV_Speichertechnologie 0;
BA_ "GenSigSendType" SG_ 2589283412 BMS_MV_Temp_Epsilon 0;
BA_ "GenSigSwitchedByIgnition" SG_ 2589283412 BMS_MV_Temp_Epsilon 0;
BA_ "GenSigSendType" SG_ 2589283412 BMS_MV_Temperatur 0;
BA_ "GenSigStartValue" SG_ 2589283412 BMS_MV_Temperatur 254;
BA_ "GenSigSwitchedByIgnition" SG_ 2589283412 BMS_MV_Temperatur 0;
BA_ "Fehlerwert" SG_ 2589283412 BMS_MV_Temperatur 255;
BA_ "GenSigSendType" SG_ 2589283412 BMS_MV_Temperierung_Anf 0;
BA_ "GenSigStartValue" SG_ 2589283412 BMS_MV_Temperierung_Anf 3;
BA_ "GenSigSwitchedByIgnition" SG_ 2589283412 BMS_MV_Temperierung_Anf 0;
BA_ "GenSigSendType" SG_ 2589283608 BMS_MV_Energieinhalt 0;
BA_ "GenSigStartValue" SG_ 2589283608 BMS_MV_Energieinhalt 2046;
BA_ "GenSigSwitchedByIgnition" SG_ 2589283608 BMS_MV_Energieinhalt 0;
BA_ "Fehlerwert" SG_ 2589283608 BMS_MV_Energieinhalt 2047;
BA_ "GenSigSendType" SG_ 2589283608 BMS_MV_MaxEnergieinhalt 0;
BA_ "GenSigStartValue" SG_ 2589283608 BMS_MV_MaxEnergieinhalt 2046;
BA_ "GenSigSwitchedByIgnition" SG_ 2589283608 BMS_MV_MaxEnergieinhalt 0;
BA_ "Fehlerwert" SG_ 2589283608 BMS_MV_MaxEnergieinhalt 2047;
BA_ "GenSigSendType" SG_ 2589283606 BMS_MV_max_Grenz_SOC 0;
BA_ "GenSigStartValue" SG_ 2589283606 BMS_MV_max_Grenz_SOC 31;
BA_ "GenSigSwitchedByIgnition" SG_ 2589283606 BMS_MV_max_Grenz_SOC 0;
BA_ "GenSigSendType" SG_ 2589283606 BMS_MV_SOC_Kaltstart 0;
BA_ "GenSigStartValue" SG_ 2589283606 BMS_MV_SOC_Kaltstart 2046;
BA_ "GenSigSwitchedByIgnition" SG_ 2589283606 BMS_MV_SOC_Kaltstart 0;
BA_ "Fehlerwert" SG_ 2589283606 BMS_MV_SOC_Kaltstart 2047;
BA_ "GenSigSendType" SG_ 1021 BMS_MV_Pred_Entladeperformance 0;
BA_ "GenSigStartValue" SG_ 1021 BMS_MV_Pred_Entladeperformance 126;
BA_ "GenSigSwitchedByIgnition" SG_ 1021 BMS_MV_Pred_Entladeperformance 0;
BA_ "Fehlerwert" SG_ 1021 BMS_MV_Pred_Entladeperformance 127;
BA_ "GenSigSendType" SG_ 1021 BMS_MV_Pred_Ladeperformance 0;
BA_ "GenSigStartValue" SG_ 1021 BMS_MV_Pred_Ladeperformance 126;
BA_ "GenSigSwitchedByIgnition" SG_ 1021 BMS_MV_Pred_Ladeperformance 0;
BA_ "Fehlerwert" SG_ 1021 BMS_MV_Pred_Ladeperformance 127;
BA_ "GenSigSendType" SG_ 1021 BMS_MV_SOHC_DiagSOC 0;
BA_ "GenSigSwitchedByIgnition" SG_ 1021 BMS_MV_SOHC_DiagSOC 0;
BA_ "GenSigSendType" SG_ 1021 BMS_MV_SOHC_DiagStatus 0;
BA_ "GenSigSwitchedByIgnition" SG_ 1021 BMS_MV_SOHC_DiagStatus 0;
BA_ "GenSigSendType" SG_ 2463978716 BMS_MV_12_BZ 0;
BA_ "GenSigFuncType" SG_ 2463978716 BMS_MV_12_BZ 1;
BA_ "GenSigSwitchedByIgnition" SG_ 2463978716 BMS_MV_12_BZ 0;
BA_ "GenSigSendType" SG_ 2463978716 BMS_MV_12_CRC 0;
BA_ "GenSigFuncType" SG_ 2463978716 BMS_MV_12_CRC 2;
BA_ "GenSigSendType" SG_ 2463978716 BMS_MV_Fehler_BattAbschaltung 3;
BA_ "GenSigSwitchedByIgnition" SG_ 2463978716 BMS_MV_Fehler_BattAbschaltung 0;
BA_ "GenSigSendType" SG_ 2463978716 BMS_MV_Fehler_BattAbschaltungAnf 3;
BA_ "GenSigSwitchedByIgnition" SG_ 2463978716 BMS_MV_Fehler_BattAbschaltungAnf 0;
BA_ "GenSigSendType" SG_ 2463978716 BMS_MV_Fehler_Kaltstartleistung 3;
BA_ "GenSigSwitchedByIgnition" SG_ 2463978716 BMS_MV_Fehler_Kaltstartleistung 0;
BA_ "GenSigSendType" SG_ 2463978716 BMS_MV_Fehler_Leistungsred 3;
BA_ "GenSigSwitchedByIgnition" SG_ 2463978716 BMS_MV_Fehler_Leistungsred 0;
BA_ "GenSigSendType" SG_ 2463978716 BMS_MV_Fehler_Notfallreserve 3;
BA_ "GenSigStartValue" SG_ 2463978716 BMS_MV_Fehler_Notfallreserve 3;
BA_ "GenSigSwitchedByIgnition" SG_ 2463978716 BMS_MV_Fehler_Notfallreserve 0;
BA_ "GenSigSendType" SG_ 2463978716 BMS_MV_Fehler_Relay_offen 3;
BA_ "GenSigSwitchedByIgnition" SG_ 2463978716 BMS_MV_Fehler_Relay_offen 0;
BA_ "GenSigSendType" SG_ 2463978716 BMS_MV_Fehler_Relay_verschweisst 3;
BA_ "GenSigSwitchedByIgnition" SG_ 2463978716 BMS_MV_Fehler_Relay_verschweisst 0;
BA_ "GenSigSendType" SG_ 2463978716 BMS_MV_IstModus 3;
BA_ "GenSigStartValue" SG_ 2463978716 BMS_MV_IstModus 7;
BA_ "GenSigSwitchedByIgnition" SG_ 2463978716 BMS_MV_IstModus 0;
BA_ "GenSigSendType" SG_ 2463978716 BMS_MV_Leistungsreduzierung 3;
BA_ "GenSigSwitchedByIgnition" SG_ 2463978716 BMS_MV_Leistungsreduzierung 0;
BA_ "GenSigSendType" SG_ 2463978716 BMS_MV_Peak_EntladeLeistung 0;
BA_ "GenSigStartValue" SG_ 2463978716 BMS_MV_Peak_EntladeLeistung 2046;
BA_ "GenSigSwitchedByIgnition" SG_ 2463978716 BMS_MV_Peak_EntladeLeistung 0;
BA_ "Fehlerwert" SG_ 2463978716 BMS_MV_Peak_EntladeLeistung 2047;
BA_ "GenSigSendType" SG_ 2463978716 BMS_MV_Peak_EntladeSpannung 0;
BA_ "GenSigStartValue" SG_ 2463978716 BMS_MV_Peak_EntladeSpannung 254;
BA_ "GenSigSwitchedByIgnition" SG_ 2463978716 BMS_MV_Peak_EntladeSpannung 0;
BA_ "Fehlerwert" SG_ 2463978716 BMS_MV_Peak_EntladeSpannung 255;
BA_ "GenSigSendType" SG_ 2463978716 BMS_MV_Peak_LadeLeistung 0;
BA_ "GenSigStartValue" SG_ 2463978716 BMS_MV_Peak_LadeLeistung 2046;
BA_ "GenSigSwitchedByIgnition" SG_ 2463978716 BMS_MV_Peak_LadeLeistung 0;
BA_ "Fehlerwert" SG_ 2463978716 BMS_MV_Peak_LadeLeistung 2047;
BA_ "GenSigSendType" SG_ 2463978716 BMS_MV_Peak_LadeSpannung 0;
BA_ "GenSigStartValue" SG_ 2463978716 BMS_MV_Peak_LadeSpannung 254;
BA_ "GenSigSwitchedByIgnition" SG_ 2463978716 BMS_MV_Peak_LadeSpannung 0;
BA_ "Fehlerwert" SG_ 2463978716 BMS_MV_Peak_LadeSpannung 255;
BA_ "GenSigSendType" SG_ 2463978717 BMS_MV_Max_EntladeLeistung 0;
BA_ "GenSigStartValue" SG_ 2463978717 BMS_MV_Max_EntladeLeistung 2046;
BA_ "GenSigSwitchedByIgnition" SG_ 2463978717 BMS_MV_Max_EntladeLeistung 0;
BA_ "Fehlerwert" SG_ 2463978717 BMS_MV_Max_EntladeLeistung 2047;
BA_ "GenSigSendType" SG_ 2463978717 BMS_MV_Max_LadeLeistung 0;
BA_ "GenSigStartValue" SG_ 2463978717 BMS_MV_Max_LadeLeistung 2046;
BA_ "GenSigSwitchedByIgnition" SG_ 2463978717 BMS_MV_Max_LadeLeistung 0;
BA_ "Fehlerwert" SG_ 2463978717 BMS_MV_Max_LadeLeistung 2047;
BA_ "GenSigSendType" SG_ 2463978717 BMS_MV_PerfInd_Entladen 0;
BA_ "GenSigStartValue" SG_ 2463978717 BMS_MV_PerfInd_Entladen 1022;
BA_ "GenSigSwitchedByIgnition" SG_ 2463978717 BMS_MV_PerfInd_Entladen 0;
BA_ "Fehlerwert" SG_ 2463978717 BMS_MV_PerfInd_Entladen 1023;
BA_ "GenSigSendType" SG_ 2463978717 BMS_MV_PerfInd_Laden 0;
BA_ "GenSigStartValue" SG_ 2463978717 BMS_MV_PerfInd_Laden 1022;
BA_ "GenSigSwitchedByIgnition" SG_ 2463978717 BMS_MV_PerfInd_Laden 0;
BA_ "Fehlerwert" SG_ 2463978717 BMS_MV_PerfInd_Laden 1023;
BA_ "GenSigSendType" SG_ 2463978717 BMS_MV_Strat_EntladeSpannung 0;
BA_ "GenSigStartValue" SG_ 2463978717 BMS_MV_Strat_EntladeSpannung 254;
BA_ "GenSigSwitchedByIgnition" SG_ 2463978717 BMS_MV_Strat_EntladeSpannung 0;
BA_ "Fehlerwert" SG_ 2463978717 BMS_MV_Strat_EntladeSpannung 255;
BA_ "GenSigSendType" SG_ 2463978718 BMS_MV_14_BZ 0;
BA_ "GenSigFuncType" SG_ 2463978718 BMS_MV_14_BZ 1;
BA_ "GenSigSwitchedByIgnition" SG_ 2463978718 BMS_MV_14_BZ 0;
BA_ "GenSigSendType" SG_ 2463978718 BMS_MV_14_CRC 0;
BA_ "GenSigFuncType" SG_ 2463978718 BMS_MV_14_CRC 2;
BA_ "GenSigSwitchedByIgnition" SG_ 2463978718 BMS_MV_14_CRC 0;
BA_ "GenSigSendType" SG_ 2463978718 BMS_MV_Max_EntladeStrom_Lim 0;
BA_ "GenSigStartValue" SG_ 2463978718 BMS_MV_Max_EntladeStrom_Lim 2046;
BA_ "GenSigSwitchedByIgnition" SG_ 2463978718 BMS_MV_Max_EntladeStrom_Lim 0;
BA_ "Fehlerwert" SG_ 2463978718 BMS_MV_Max_EntladeStrom_Lim 2047;
BA_ "GenSigSendType" SG_ 2463978718 BMS_MV_Max_LadeSpannung_Lim 0;
BA_ "GenSigStartValue" SG_ 2463978718 BMS_MV_Max_LadeSpannung_Lim 254;
BA_ "GenSigSwitchedByIgnition" SG_ 2463978718 BMS_MV_Max_LadeSpannung_Lim 0;
BA_ "Fehlerwert" SG_ 2463978718 BMS_MV_Max_LadeSpannung_Lim 255;
BA_ "GenSigSendType" SG_ 2463978718 BMS_MV_Max_LadeStrom_Lim 0;
BA_ "GenSigStartValue" SG_ 2463978718 BMS_MV_Max_LadeStrom_Lim 2046;
BA_ "GenSigSwitchedByIgnition" SG_ 2463978718 BMS_MV_Max_LadeStrom_Lim 0;
BA_ "Fehlerwert" SG_ 2463978718 BMS_MV_Max_LadeStrom_Lim 2047;
BA_ "GenSigSendType" SG_ 2463978718 BMS_MV_Min_EntladeSpannung_Lim 0;
BA_ "GenSigStartValue" SG_ 2463978718 BMS_MV_Min_EntladeSpannung_Lim 254;
BA_ "GenSigSwitchedByIgnition" SG_ 2463978718 BMS_MV_Min_EntladeSpannung_Lim 0;
BA_ "Fehlerwert" SG_ 2463978718 BMS_MV_Min_EntladeSpannung_Lim 255;
BA_ "GenSigSendType" SG_ 2463978718 BMS_MV_Strat_LadeSpannung 0;
BA_ "GenSigStartValue" SG_ 2463978718 BMS_MV_Strat_LadeSpannung 254;
BA_ "GenSigSwitchedByIgnition" SG_ 2463978718 BMS_MV_Strat_LadeSpannung 0;
BA_ "Fehlerwert" SG_ 2463978718 BMS_MV_Strat_LadeSpannung 255;
BA_ "GenSigSendType" SG_ 2589283523 BMS_48V_Indc_StChk 0;
BA_ "GenSigStartValue" SG_ 2589283523 BMS_48V_Indc_StChk 1;
BA_ "GenSigSwitchedByIgnition" SG_ 2589283523 BMS_48V_Indc_StChk 0;
BA_ "GenSigSendType" SG_ 2589283523 BMS_48V_Indc_StFail 0;
BA_ "GenSigSwitchedByIgnition" SG_ 2589283523 BMS_48V_Indc_StFail 0;
BA_ "GenSigSendType" SG_ 2589283523 BMS_MV_Dauer_EntladeLeistung 0;
BA_ "GenSigStartValue" SG_ 2589283523 BMS_MV_Dauer_EntladeLeistung 2046;
BA_ "GenSigSwitchedByIgnition" SG_ 2589283523 BMS_MV_Dauer_EntladeLeistung 0;
BA_ "Fehlerwert" SG_ 2589283523 BMS_MV_Dauer_EntladeLeistung 2047;
BA_ "GenSigSendType" SG_ 2589283523 BMS_MV_Dauer_EntladeSpannung 0;
BA_ "GenSigStartValue" SG_ 2589283523 BMS_MV_Dauer_EntladeSpannung 254;
BA_ "GenSigSwitchedByIgnition" SG_ 2589283523 BMS_MV_Dauer_EntladeSpannung 0;
BA_ "Fehlerwert" SG_ 2589283523 BMS_MV_Dauer_EntladeSpannung 255;
BA_ "GenSigSendType" SG_ 2589283523 BMS_MV_Dauer_LadeLeistung 0;
BA_ "GenSigStartValue" SG_ 2589283523 BMS_MV_Dauer_LadeLeistung 2046;
BA_ "GenSigSwitchedByIgnition" SG_ 2589283523 BMS_MV_Dauer_LadeLeistung 0;
BA_ "Fehlerwert" SG_ 2589283523 BMS_MV_Dauer_LadeLeistung 2047;
BA_ "GenSigSendType" SG_ 2589283523 BMS_MV_Dauer_LadeSpannung 0;
BA_ "GenSigStartValue" SG_ 2589283523 BMS_MV_Dauer_LadeSpannung 254;
BA_ "GenSigSwitchedByIgnition" SG_ 2589283523 BMS_MV_Dauer_LadeSpannung 0;
BA_ "Fehlerwert" SG_ 2589283523 BMS_MV_Dauer_LadeSpannung 255;
BA_ "GenSigSendType" SG_ 2589283523 BMS_MV_Dauer_RMS_Strom 0;
BA_ "GenSigStartValue" SG_ 2589283523 BMS_MV_Dauer_RMS_Strom 254;
BA_ "GenSigSwitchedByIgnition" SG_ 2589283523 BMS_MV_Dauer_RMS_Strom 0;
BA_ "Fehlerwert" SG_ 2589283523 BMS_MV_Dauer_RMS_Strom 255;
BA_ "GenSigSendType" SG_ 2589283523 BMS_MV_Kundenwarnung 3;
BA_ "GenSigSwitchedByIgnition" SG_ 2589283523 BMS_MV_Kundenwarnung 0;
BA_ "GenSigSendType" SG_ 2589283523 BMS_MV_OBD_Lampe_Anf 0;
BA_ "GenSigSwitchedByIgnition" SG_ 2589283523 BMS_MV_OBD_Lampe_Anf 0;
BA_ "GenSigSendType" SG_ 2589283523 OBDProtocol_BMS_48V 0;
BA_ "GenSigStartValue" SG_ 2589283523 OBDProtocol_BMS_48V 254;
BA_ "GenSigSwitchedByIgnition" SG_ 2589283523 OBDProtocol_BMS_48V 0;
BA_ "Fehlerwert" SG_ 2589283523 OBDProtocol_BMS_48V 255;
BA_ "GenSigSendType" SG_ 2589283543 SOK_BMS_MV_15_Signatur 0;
BA_ "GenSigFuncType" SG_ 2589283543 SOK_BMS_MV_15_Signatur 15;
BA_ "GenSigSwitchedByIgnition" SG_ 2589283543 SOK_BMS_MV_15_Signatur 0;
BA_ "GenSigSendType" SG_ 2589283524 BMS_MV_EntladeEnergie 0;
BA_ "GenSigStartValue" SG_ 2589283524 BMS_MV_EntladeEnergie 2046;
BA_ "GenSigSwitchedByIgnition" SG_ 2589283524 BMS_MV_EntladeEnergie 0;
BA_ "Fehlerwert" SG_ 2589283524 BMS_MV_EntladeEnergie 2047;
BA_ "GenSigSendType" SG_ 2589283524 BMS_MV_LadeEnergie 0;
BA_ "GenSigStartValue" SG_ 2589283524 BMS_MV_LadeEnergie 2046;
BA_ "GenSigSwitchedByIgnition" SG_ 2589283524 BMS_MV_LadeEnergie 0;
BA_ "Fehlerwert" SG_ 2589283524 BMS_MV_LadeEnergie 2047;
BA_ "GenSigSendType" SG_ 2589283524 BMS_MV_Max_RMS_Strom 0;
BA_ "GenSigStartValue" SG_ 2589283524 BMS_MV_Max_RMS_Strom 254;
BA_ "GenSigSwitchedByIgnition" SG_ 2589283524 BMS_MV_Max_RMS_Strom 0;
BA_ "Fehlerwert" SG_ 2589283524 BMS_MV_Max_RMS_Strom 255;
BA_ "GenSigSendType" SG_ 2589283524 BMS_MV_TRD_Sensfail 3;
BA_ "GenSigSwitchedByIgnition" SG_ 2589283524 BMS_MV_TRD_Sensfail 0;
BA_ "GenSigSendType" SG_ 2589283524 BMS_MV_TRD_Temp 3;
BA_ "GenSigSwitchedByIgnition" SG_ 2589283524 BMS_MV_TRD_Temp 0;
BA_ "GenSigSendType" SG_ 2589283524 BMS_MV_TRD_Voltage 3;
BA_ "GenSigSwitchedByIgnition" SG_ 2589283524 BMS_MV_TRD_Voltage 0;
BA_ "GenSigSendType" SG_ 2527679928 BMS_NV_Indc_StChk 0;
BA_ "GenSigStartValue" SG_ 2527679928 BMS_NV_Indc_StChk 1;
BA_ "GenSigSwitchedByIgnition" SG_ 2527679928 BMS_NV_Indc_StChk 0;
BA_ "GenSigSendType" SG_ 2527679928 BMS_NV_Indc_StFail 0;
BA_ "GenSigSwitchedByIgnition" SG_ 2527679928 BMS_NV_Indc_StFail 0;
BA_ "GenSigSendType" SG_ 2527679928 BMS_NV_OBD_Lampe_Anf 0;
BA_ "GenSigSwitchedByIgnition" SG_ 2527679928 BMS_NV_OBD_Lampe_Anf 0;
BA_ "GenSigSendType" SG_ 2527679928 OBDProtocol_BMS_NV 0;
BA_ "GenSigStartValue" SG_ 2527679928 OBDProtocol_BMS_NV 254;
BA_ "GenSigSwitchedByIgnition" SG_ 2527679928 OBDProtocol_BMS_NV 0;
BA_ "Fehlerwert" SG_ 2527679928 OBDProtocol_BMS_NV 255;
BA_ "GenSigSendType" SG_ 2527679928 SOK_BMS_NV_11_Signatur 0;
BA_ "GenSigFuncType" SG_ 2527679928 SOK_BMS_NV_11_Signatur 15;
BA_ "GenSigSwitchedByIgnition" SG_ 2527679928 SOK_BMS_NV_11_Signatur 0;
BA_ "GenSigSendType" SG_ 2463978646 CHA_Current_Mode 3;
BA_ "GenSigSwitchedByIgnition" SG_ 2463978646 CHA_Current_Mode 0;
BA_ "GenSigSendType" SG_ 2463978646 CHA_Fahrer_Umschaltung 3;
BA_ "GenSigSwitchedByIgnition" SG_ 2463978646 CHA_Fahrer_Umschaltung 0;
BA_ "GenSigSendType" SG_ 2463978646 CHA_Fahrer_Umschaltung_BMA 3;
BA_ "GenSigSwitchedByIgnition" SG_ 2463978646 CHA_Fahrer_Umschaltung_BMA 0;
BA_ "GenSigSendType" SG_ 2463978646 CHA_Ziel_FahrPr_ACC 3;
BA_ "GenSigSwitchedByIgnition" SG_ 2463978646 CHA_Ziel_FahrPr_ACC 0;
BA_ "GenSigSendType" SG_ 2463978646 CHA_Ziel_FahrPr_AEB 3;
BA_ "GenSigSwitchedByIgnition" SG_ 2463978646 CHA_Ziel_FahrPr_AEB 0;
BA_ "GenSigSendType" SG_ 2463978646 CHA_Ziel_FahrPr_AFR 3;
BA_ "GenSigSwitchedByIgnition" SG_ 2463978646 CHA_Ziel_FahrPr_AFR 0;
BA_ "GenSigSendType" SG_ 2463978646 CHA_Ziel_FahrPr_AFS 3;
BA_ "GenSigSwitchedByIgnition" SG_ 2463978646 CHA_Ziel_FahrPr_AFS 0;
BA_ "GenSigSendType" SG_ 2463978646 CHA_Ziel_FahrPr_AGA 3;
BA_ "GenSigSwitchedByIgnition" SG_ 2463978646 CHA_Ziel_FahrPr_AGA 0;
BA_ "GenSigSendType" SG_ 2463978646 CHA_Ziel_FahrPr_AGK 3;
BA_ "GenSigSwitchedByIgnition" SG_ 2463978646 CHA_Ziel_FahrPr_AGK 0;
BA_ "GenSigSendType" SG_ 2463978646 CHA_Ziel_FahrPr_ALR 3;
BA_ "GenSigSwitchedByIgnition" SG_ 2463978646 CHA_Ziel_FahrPr_ALR 0;
BA_ "GenSigSendType" SG_ 2463978646 CHA_Ziel_FahrPr_AV 3;
BA_ "GenSigSwitchedByIgnition" SG_ 2463978646 CHA_Ziel_FahrPr_AV 0;
BA_ "GenSigSendType" SG_ 2463978646 CHA_Ziel_FahrPr_BMS 3;
BA_ "GenSigSwitchedByIgnition" SG_ 2463978646 CHA_Ziel_FahrPr_BMS 0;
BA_ "GenSigSendType" SG_ 2463978646 CHA_Ziel_FahrPr_DR 3;
BA_ "GenSigSwitchedByIgnition" SG_ 2463978646 CHA_Ziel_FahrPr_DR 0;
BA_ "GenSigSendType" SG_ 2463978646 CHA_Ziel_FahrPr_EAR 3;
BA_ "GenSigSwitchedByIgnition" SG_ 2463978646 CHA_Ziel_FahrPr_EAR 0;
BA_ "GenSigSendType" SG_ 2463978646 CHA_Ziel_FahrPr_EBKV 3;
BA_ "GenSigSwitchedByIgnition" SG_ 2463978646 CHA_Ziel_FahrPr_EBKV 0;
BA_ "GenSigSendType" SG_ 2463978646 CHA_Ziel_FahrPr_EDS 3;
BA_ "GenSigSwitchedByIgnition" SG_ 2463978646 CHA_Ziel_FahrPr_EDS 0;
BA_ "GenSigSendType" SG_ 2463978646 CHA_Ziel_FahrPr_EPS 3;
BA_ "GenSigSwitchedByIgnition" SG_ 2463978646 CHA_Ziel_FahrPr_EPS 0;
BA_ "GenSigSendType" SG_ 2463978646 CHA_Ziel_FahrPr_eSound 3;
BA_ "GenSigSwitchedByIgnition" SG_ 2463978646 CHA_Ziel_FahrPr_eSound 0;
BA_ "GenSigSendType" SG_ 2463978646 CHA_Ziel_FahrPr_ESP 3;
BA_ "GenSigSwitchedByIgnition" SG_ 2463978646 CHA_Ziel_FahrPr_ESP 0;
BA_ "GenSigSendType" SG_ 2463978646 CHA_Ziel_FahrPr_FCWO 3;
BA_ "GenSigSwitchedByIgnition" SG_ 2463978646 CHA_Ziel_FahrPr_FCWO 0;
BA_ "GenSigSendType" SG_ 2463978646 CHA_Ziel_FahrPr_FCWP 3;
BA_ "GenSigSwitchedByIgnition" SG_ 2463978646 CHA_Ziel_FahrPr_FCWP 0;
BA_ "GenSigSendType" SG_ 2463978646 CHA_Ziel_FahrPr_Freilauf 3;
BA_ "GenSigSwitchedByIgnition" SG_ 2463978646 CHA_Ziel_FahrPr_Freilauf 0;
BA_ "GenSigSendType" SG_ 2463978646 CHA_Ziel_FahrPr_GE 3;
BA_ "GenSigSwitchedByIgnition" SG_ 2463978646 CHA_Ziel_FahrPr_GE 0;
BA_ "GenSigSendType" SG_ 2463978646 CHA_Ziel_FahrPr_HAL 3;
BA_ "GenSigSwitchedByIgnition" SG_ 2463978646 CHA_Ziel_FahrPr_HAL 0;
BA_ "GenSigSendType" SG_ 2463978646 CHA_Ziel_FahrPr_HDC 3;
BA_ "GenSigSwitchedByIgnition" SG_ 2463978646 CHA_Ziel_FahrPr_HDC 0;
BA_ "GenSigSendType" SG_ 2463978646 CHA_Ziel_FahrPr_HHC 3;
BA_ "GenSigSwitchedByIgnition" SG_ 2463978646 CHA_Ziel_FahrPr_HHC 0;
BA_ "GenSigSendType" SG_ 2463978646 CHA_Ziel_FahrPr_IL 3;
BA_ "GenSigSwitchedByIgnition" SG_ 2463978646 CHA_Ziel_FahrPr_IL 0;
BA_ "GenSigSendType" SG_ 2463978646 CHA_Ziel_FahrPr_mFDR 3;
BA_ "GenSigSwitchedByIgnition" SG_ 2463978646 CHA_Ziel_FahrPr_mFDR 0;
BA_ "GenSigSendType" SG_ 2463978646 CHA_Ziel_FahrPr_MO 3;
BA_ "GenSigSwitchedByIgnition" SG_ 2463978646 CHA_Ziel_FahrPr_MO 0;
BA_ "GenSigSendType" SG_ 2463978646 CHA_Ziel_FahrPr_MO_BZS 3;
BA_ "GenSigSwitchedByIgnition" SG_ 2463978646 CHA_Ziel_FahrPr_MO_BZS 0;
BA_ "GenSigSendType" SG_ 2463978646 CHA_Ziel_FahrPr_MO_Freilauf 3;
BA_ "GenSigSwitchedByIgnition" SG_ 2463978646 CHA_Ziel_FahrPr_MO_Freilauf 0;
BA_ "GenSigSendType" SG_ 2463978646 CHA_Ziel_FahrPr_MO_StSt 3;
BA_ "GenSigSwitchedByIgnition" SG_ 2463978646 CHA_Ziel_FahrPr_MO_StSt 0;
BA_ "GenSigSendType" SG_ 2463978646 CHA_Ziel_FahrPr_MXB 3;
BA_ "GenSigSwitchedByIgnition" SG_ 2463978646 CHA_Ziel_FahrPr_MXB 0;
BA_ "GenSigSendType" SG_ 2463978646 CHA_Ziel_FahrPr_NR 3;
BA_ "GenSigSwitchedByIgnition" SG_ 2463978646 CHA_Ziel_FahrPr_NR 0;
BA_ "GenSigSendType" SG_ 2463978646 CHA_Ziel_FahrPr_PACC 3;
BA_ "GenSigSwitchedByIgnition" SG_ 2463978646 CHA_Ziel_FahrPr_PACC 0;
BA_ "GenSigSendType" SG_ 2463978646 CHA_Ziel_FahrPr_PDC 3;
BA_ "GenSigSwitchedByIgnition" SG_ 2463978646 CHA_Ziel_FahrPr_PDC 0;
BA_ "GenSigSendType" SG_ 2463978646 CHA_Ziel_FahrPr_PreCrash 3;
BA_ "GenSigSwitchedByIgnition" SG_ 2463978646 CHA_Ziel_FahrPr_PreCrash 0;
BA_ "GenSigSendType" SG_ 2463978646 CHA_Ziel_FahrPr_QS 3;
BA_ "GenSigSwitchedByIgnition" SG_ 2463978646 CHA_Ziel_FahrPr_QS 0;
BA_ "GenSigSendType" SG_ 2463978646 CHA_Ziel_FahrPr_Reku_ZwGas 3;
BA_ "GenSigSwitchedByIgnition" SG_ 2463978646 CHA_Ziel_FahrPr_Reku_ZwGas 0;
BA_ "GenSigSendType" SG_ 2463978646 CHA_Ziel_FahrPr_RHP 3;
BA_ "GenSigSwitchedByIgnition" SG_ 2463978646 CHA_Ziel_FahrPr_RHP 0;
BA_ "GenSigSendType" SG_ 2463978646 CHA_Ziel_FahrPr_SAK 3;
BA_ "GenSigSwitchedByIgnition" SG_ 2463978646 CHA_Ziel_FahrPr_SAK 0;
BA_ "GenSigSendType" SG_ 2463978646 CHA_Ziel_FahrPr_SCU 3;
BA_ "GenSigSwitchedByIgnition" SG_ 2463978646 CHA_Ziel_FahrPr_SCU 0;
BA_ "GenSigSendType" SG_ 2463978646 CHA_Ziel_FahrPr_ToS_laengs 3;
BA_ "GenSigSwitchedByIgnition" SG_ 2463978646 CHA_Ziel_FahrPr_ToS_laengs 0;
BA_ "GenSigSendType" SG_ 2463978646 CHA_Ziel_FahrPr_ToS_quer 3;
BA_ "GenSigSwitchedByIgnition" SG_ 2463978646 CHA_Ziel_FahrPr_ToS_quer 0;
BA_ "GenSigSendType" SG_ 2463978646 CHA_Ziel_FahrPr_VAQ 3;
BA_ "GenSigSwitchedByIgnition" SG_ 2463978646 CHA_Ziel_FahrPr_VAQ 0;
BA_ "GenSigSendType" SG_ 1485 DC_Abregelung_Temperatur 4;
BA_ "GenSigSwitchedByIgnition" SG_ 1485 DC_Abregelung_Temperatur 0;
BA_ "GenSigSendType" SG_ 1485 DC_Derating 4;
BA_ "GenSigSwitchedByIgnition" SG_ 1485 DC_Derating 0;
BA_ "GenSigSendType" SG_ 1485 DC_Fehlerstatus 4;
BA_ "GenSigStartValue" SG_ 1485 DC_Fehlerstatus 7;
BA_ "GenSigSwitchedByIgnition" SG_ 1485 DC_Fehlerstatus 0;
BA_ "GenSigSendType" SG_ 1485 DC_Kl30c_Status 4;
BA_ "GenSigSwitchedByIgnition" SG_ 1485 DC_Kl30c_Status 0;
BA_ "Fehlerwert" SG_ 1485 DC_Kl30c_Status 3;
BA_ "GenSigSendType" SG_ 1485 DC_OBD_Lampe_Anf 0;
BA_ "GenSigSwitchedByIgnition" SG_ 1485 DC_OBD_Lampe_Anf 0;
BA_ "GenSigSendType" SG_ 1485 DC_Peakstrom_verfuegbar 4;
BA_ "GenSigSwitchedByIgnition" SG_ 1485 DC_Peakstrom_verfuegbar 0;
BA_ "GenSigSendType" SG_ 1485 DC_SollVolumenstrom 0;
BA_ "GenSigStartValue" SG_ 1485 DC_SollVolumenstrom 62;
BA_ "GenSigSwitchedByIgnition" SG_ 1485 DC_SollVolumenstrom 0;
BA_ "Fehlerwert" SG_ 1485 DC_SollVolumenstrom 63;
BA_ "GenSigSendType" SG_ 1485 DC_Status_Spgfreiheit_HV 4;
BA_ "GenSigSwitchedByIgnition" SG_ 1485 DC_Status_Spgfreiheit_HV 0;
BA_ "Fehlerwert" SG_ 1485 DC_Status_Spgfreiheit_HV 3;
BA_ "GenSigSendType" SG_ 1485 DC_Temperatur 0;
BA_ "GenSigStartValue" SG_ 1485 DC_Temperatur 254;
BA_ "GenSigSwitchedByIgnition" SG_ 1485 DC_Temperatur 0;
BA_ "Fehlerwert" SG_ 1485 DC_Temperatur 255;
BA_ "GenSigSendType" SG_ 1485 DC_Temperatur_Alarm 0;
BA_ "GenSigSwitchedByIgnition" SG_ 1485 DC_Temperatur_Alarm 0;
BA_ "Fehlerwert" SG_ 1485 DC_Temperatur_Alarm 1;
BA_ "GenSigSendType" SG_ 1485 DC_Warnlampe_Anf 0;
BA_ "GenSigSwitchedByIgnition" SG_ 1485 DC_Warnlampe_Anf 0;
BA_ "GenSigSendType" SG_ 1485 DCDC_03_BZ 0;
BA_ "GenSigFuncType" SG_ 1485 DCDC_03_BZ 1;
BA_ "GenSigSwitchedByIgnition" SG_ 1485 DCDC_03_BZ 0;
BA_ "GenSigSendType" SG_ 1485 DCDC_03_CRC 0;
BA_ "GenSigFuncType" SG_ 1485 DCDC_03_CRC 2;
BA_ "GenSigSwitchedByIgnition" SG_ 1485 DCDC_03_CRC 0;
BA_ "GenSigSendType" SG_ 1485 DCDC_NV_Indc_StChk 0;
BA_ "GenSigStartValue" SG_ 1485 DCDC_NV_Indc_StChk 1;
BA_ "GenSigSwitchedByIgnition" SG_ 1485 DCDC_NV_Indc_StChk 0;
BA_ "GenSigSendType" SG_ 1485 DCDC_NV_Indc_StFail 0;
BA_ "GenSigSwitchedByIgnition" SG_ 1485 DCDC_NV_Indc_StFail 0;
BA_ "GenSigSendType" SG_ 1485 OBDProtocol_DCDC_NV 0;
BA_ "GenSigStartValue" SG_ 1485 OBDProtocol_DCDC_NV 254;
BA_ "GenSigSwitchedByIgnition" SG_ 1485 OBDProtocol_DCDC_NV 0;
BA_ "Fehlerwert" SG_ 1485 OBDProtocol_DCDC_NV 255;
BA_ "GenSigSendType" SG_ 1486 SOK_DCDC_03_Signatur 0;
BA_ "GenSigFuncType" SG_ 1486 SOK_DCDC_03_Signatur 15;
BA_ "GenSigSwitchedByIgnition" SG_ 1486 SOK_DCDC_03_Signatur 0;
BA_ "GenSigSendType" SG_ 247 DC_Fehler_extern 0;
BA_ "GenSigSwitchedByIgnition" SG_ 247 DC_Fehler_extern 0;
BA_ "Fehlerwert" SG_ 247 DC_Fehler_extern 1;
BA_ "GenSigSendType" SG_ 247 DC_Fehler_intern 0;
BA_ "GenSigSwitchedByIgnition" SG_ 247 DC_Fehler_intern 0;
BA_ "GenSigSendType" SG_ 247 DC_IstLeistung_HV 0;
BA_ "GenSigStartValue" SG_ 247 DC_IstLeistung_HV 1022;
BA_ "GenSigSwitchedByIgnition" SG_ 247 DC_IstLeistung_HV 0;
BA_ "Fehlerwert" SG_ 247 DC_IstLeistung_HV 1023;
BA_ "GenSigSendType" SG_ 247 DC_IstModus_02 0;
BA_ "GenSigStartValue" SG_ 247 DC_IstModus_02 7;
BA_ "GenSigSwitchedByIgnition" SG_ 247 DC_IstModus_02 0;
BA_ "Fehlerwert" SG_ 247 DC_IstModus_02 5;
BA_ "GenSigSendType" SG_ 247 DC_IstStrom_HV 0;
BA_ "GenSigStartValue" SG_ 247 DC_IstStrom_HV 1022;
BA_ "GenSigSwitchedByIgnition" SG_ 247 DC_IstStrom_HV 0;
BA_ "Fehlerwert" SG_ 247 DC_IstStrom_HV 1023;
BA_ "GenSigSendType" SG_ 247 DC_Status_EoHVL 0;
BA_ "GenSigSwitchedByIgnition" SG_ 247 DC_Status_EoHVL 0;
BA_ "Fehlerwert" SG_ 247 DC_Status_EoHVL 3;
BA_ "GenSigSendType" SG_ 247 DC_Status_Spgfreiheit 0;
BA_ "GenSigSwitchedByIgnition" SG_ 247 DC_Status_Spgfreiheit 0;
BA_ "GenSigSendType" SG_ 247 DC_Vorladung_Status 0;
BA_ "GenSigSwitchedByIgnition" SG_ 247 DC_Vorladung_Status 0;
BA_ "GenSigSendType" SG_ 247 DCDC_04_BZ 0;
BA_ "GenSigFuncType" SG_ 247 DCDC_04_BZ 1;
BA_ "GenSigSwitchedByIgnition" SG_ 247 DCDC_04_BZ 0;
BA_ "GenSigSendType" SG_ 247 DCDC_04_CRC 0;
BA_ "GenSigFuncType" SG_ 247 DCDC_04_CRC 2;
BA_ "GenSigSwitchedByIgnition" SG_ 247 DCDC_04_CRC 0;
BA_ "GenSigSendType" SG_ 1484 DC_MV_12V_Bordnetzstuetzung 3;
BA_ "GenSigSwitchedByIgnition" SG_ 1484 DC_MV_12V_Bordnetzstuetzung 0;
BA_ "GenSigSendType" SG_ 1484 DC_MV_Abregelung_Temperatur 3;
BA_ "GenSigSwitchedByIgnition" SG_ 1484 DC_MV_Abregelung_Temperatur 0;
BA_ "GenSigSendType" SG_ 1484 DC_MV_Derating 0;
BA_ "GenSigSwitchedByIgnition" SG_ 1484 DC_MV_Derating 0;
BA_ "GenSigSendType" SG_ 1484 DC_MV_Fehlerstatus 3;
BA_ "GenSigStartValue" SG_ 1484 DC_MV_Fehlerstatus 7;
BA_ "GenSigSwitchedByIgnition" SG_ 1484 DC_MV_Fehlerstatus 0;
BA_ "GenSigSendType" SG_ 1484 DC_MV_IstModus_02 3;
BA_ "GenSigStartValue" SG_ 1484 DC_MV_IstModus_02 7;
BA_ "GenSigSwitchedByIgnition" SG_ 1484 DC_MV_IstModus_02 0;
BA_ "Fehlerwert" SG_ 1484 DC_MV_IstModus_02 5;
BA_ "GenSigSendType" SG_ 1484 DC_MV_Temperatur 0;
BA_ "GenSigStartValue" SG_ 1484 DC_MV_Temperatur 254;
BA_ "GenSigSwitchedByIgnition" SG_ 1484 DC_MV_Temperatur 0;
BA_ "Fehlerwert" SG_ 1484 DC_MV_Temperatur 255;
BA_ "GenSigSendType" SG_ 1484 DC_MV_Tiefsetzen_Notbetrieb 3;
BA_ "GenSigSwitchedByIgnition" SG_ 1484 DC_MV_Tiefsetzen_Notbetrieb 0;
BA_ "GenSigSendType" SG_ 1484 DCDC_MV_03_BZ 0;
BA_ "GenSigFuncType" SG_ 1484 DCDC_MV_03_BZ 1;
BA_ "GenSigSwitchedByIgnition" SG_ 1484 DCDC_MV_03_BZ 0;
BA_ "GenSigSendType" SG_ 1484 DCDC_MV_03_CRC 0;
BA_ "GenSigFuncType" SG_ 1484 DCDC_MV_03_CRC 2;
BA_ "GenSigSwitchedByIgnition" SG_ 1484 DCDC_MV_03_CRC 0;
BA_ "GenSigSendType" SG_ 1484 DCDC_MV_Peakstrom_verfuegbar 3;
BA_ "GenSigSwitchedByIgnition" SG_ 1484 DCDC_MV_Peakstrom_verfuegbar 0;
BA_ "GenSigSwitchedByIgnition" SG_ 2617227808 DEV_Getriebe_Resp_20_Data 0;
BA_ "GenSigSwitchedByIgnition" SG_ 2617227809 DEV_Getriebe_Resp_21_Data 0;
BA_ "GenSigSwitchedByIgnition" SG_ 2566865408 DEV_Parksperre_Resp_00_Data 0;
BA_ "GenSigSwitchedByIgnition" SG_ 2566865663 DEV_Parksperre_Resp_FF_Data 0;
BA_ "GenSigSwitchedByIgnition" SG_ 2617154048 DEV_Waehlhebel_Resp_00_Data 0;
BA_ "GenSigSwitchedByIgnition" SG_ 2617154049 DEV_Waehlhebel_Resp_01_Data 0;
BA_ "GenSigSwitchedByIgnition" SG_ 2617154050 DEV_Waehlhebel_Resp_02_Data 0;
BA_ "GenSigSwitchedByIgnition" SG_ 2617154051 DEV_Waehlhebel_Resp_03_Data 0;
BA_ "GenSigSwitchedByIgnition" SG_ 2617154052 DEV_Waehlhebel_Resp_04_Data 0;
BA_ "GenSigSwitchedByIgnition" SG_ 2617154053 DEV_Waehlhebel_Resp_05_Data 0;
BA_ "GenSigSendType" SG_ 2549880589 DIA_eBooster_Req_Data 3;
BA_ "GenSigFuncType" SG_ 2549880589 DIA_eBooster_Req_Data 9;
BA_ "GenSigSwitchedByIgnition" SG_ 2549880589 DIA_eBooster_Req_Data 0;
BA_ "GenSigSendType" SG_ 2550011661 DIA_eBooster_Resp_Data 3;
BA_ "GenSigFuncType" SG_ 2550011661 DIA_eBooster_Resp_Data 9;
BA_ "GenSigSwitchedByIgnition" SG_ 2550011661 DIA_eBooster_Resp_Data 0;
BA_ "GenSigSendType" SG_ 2549880644 DIA_EKAT_Req_Data 3;
BA_ "GenSigFuncType" SG_ 2549880644 DIA_EKAT_Req_Data 9;
BA_ "GenSigSwitchedByIgnition" SG_ 2549880644 DIA_EKAT_Req_Data 0;
BA_ "GenSigSendType" SG_ 2550011716 DIA_EKAT_Resp_Data 3;
BA_ "GenSigFuncType" SG_ 2550011716 DIA_EKAT_Resp_Data 9;
BA_ "GenSigSwitchedByIgnition" SG_ 2550011716 DIA_EKAT_Resp_Data 0;
BA_ "GenSigSendType" SG_ 2549880568 DIA_MTFP_Req_Data 3;
BA_ "GenSigFuncType" SG_ 2549880568 DIA_MTFP_Req_Data 9;
BA_ "GenSigSwitchedByIgnition" SG_ 2549880568 DIA_MTFP_Req_Data 0;
BA_ "GenSigSendType" SG_ 2550011640 DIA_MTFP_Resp_Data 3;
BA_ "GenSigFuncType" SG_ 2550011640 DIA_MTFP_Resp_Data 9;
BA_ "GenSigSwitchedByIgnition" SG_ 2550011640 DIA_MTFP_Resp_Data 0;
BA_ "GenSigSendType" SG_ 2549880642 DIA_Parksperre_Req_Data 3;
BA_ "GenSigFuncType" SG_ 2549880642 DIA_Parksperre_Req_Data 9;
BA_ "GenSigSwitchedByIgnition" SG_ 2549880642 DIA_Parksperre_Req_Data 0;
BA_ "GenSigSendType" SG_ 2621445954 DIA_Parksperre_Req_FD_Data 3;
BA_ "GenSigFuncType" SG_ 2621445954 DIA_Parksperre_Req_FD_Data 9;
BA_ "GenSigSwitchedByIgnition" SG_ 2621445954 DIA_Parksperre_Req_FD_Data 0;
BA_ "GenSigSendType" SG_ 2550011714 DIA_Parksperre_Resp_Data 3;
BA_ "GenSigFuncType" SG_ 2550011714 DIA_Parksperre_Resp_Data 9;
BA_ "GenSigSwitchedByIgnition" SG_ 2550011714 DIA_Parksperre_Resp_Data 0;
BA_ "GenSigSendType" SG_ 2621577026 DIA_Parksperre_Resp_FD_Data 3;
BA_ "GenSigFuncType" SG_ 2621577026 DIA_Parksperre_Resp_FD_Data 9;
BA_ "GenSigSwitchedByIgnition" SG_ 2621577026 DIA_Parksperre_Resp_FD_Data 0;
BA_ "GenSigSendType" SG_ 2549876546 Diag_Parksperre_Req_Data 3;
BA_ "GenSigFuncType" SG_ 2549876546 Diag_Parksperre_Req_Data 9;
BA_ "GenSigSwitchedByIgnition" SG_ 2549876546 Diag_Parksperre_Req_Data 0;
BA_ "GenSigSendType" SG_ 2550007618 Diag_Parksperre_Resp_Data 3;
BA_ "GenSigFuncType" SG_ 2550007618 Diag_Parksperre_Resp_Data 9;
BA_ "GenSigSwitchedByIgnition" SG_ 2550007618 Diag_Parksperre_Resp_Data 0;
BA_ "GenSigSendType" SG_ 2549876269 Diag_Waehlhebel_Req_Data 3;
BA_ "GenSigFuncType" SG_ 2549876269 Diag_Waehlhebel_Req_Data 9;
BA_ "GenSigSwitchedByIgnition" SG_ 2549876269 Diag_Waehlhebel_Req_Data 0;
BA_ "GenSigSendType" SG_ 2550007341 Diag_Waehlhebel_Resp_Data 3;
BA_ "GenSigFuncType" SG_ 2550007341 Diag_Waehlhebel_Resp_Data 9;
BA_ "GenSigSwitchedByIgnition" SG_ 2550007341 Diag_Waehlhebel_Resp_Data 0;
BA_ "GenSigSendType" SG_ 1714 DGN_Verlernzaehler 0;
BA_ "GenSigSwitchedByIgnition" SG_ 1714 DGN_Verlernzaehler 0;
BA_ "GenSigSendType" SG_ 1714 KBI_Kilometerstand 0;
BA_ "GenSigStartValue" SG_ 1714 KBI_Kilometerstand 1048574;
BA_ "GenSigSwitchedByIgnition" SG_ 1714 KBI_Kilometerstand 0;
BA_ "Fehlerwert" SG_ 1714 KBI_Kilometerstand 1048575;
BA_ "GenSigSendType" SG_ 1714 Kombi_02_alt 0;
BA_ "GenSigStartValue" SG_ 1714 Kombi_02_alt 1;
BA_ "GenSigFuncType" SG_ 1714 Kombi_02_alt 5;
BA_ "GenSigSwitchedByIgnition" SG_ 1714 Kombi_02_alt 0;
BA_ "GenSigSendType" SG_ 1714 UH_Jahr 0;
BA_ "GenSigSwitchedByIgnition" SG_ 1714 UH_Jahr 0;
BA_ "GenSigSendType" SG_ 1714 UH_Minute 0;
BA_ "GenSigSwitchedByIgnition" SG_ 1714 UH_Minute 0;
BA_ "GenSigSendType" SG_ 1714 UH_Monat 0;
BA_ "GenSigSwitchedByIgnition" SG_ 1714 UH_Monat 0;
BA_ "Fehlerwert" SG_ 1714 UH_Monat 15;
BA_ "GenSigSendType" SG_ 1714 UH_Sekunde 0;
BA_ "GenSigSwitchedByIgnition" SG_ 1714 UH_Sekunde 0;
BA_ "GenSigSendType" SG_ 1714 UH_Stunde 0;
BA_ "GenSigSwitchedByIgnition" SG_ 1714 UH_Stunde 0;
BA_ "GenSigSendType" SG_ 1714 UH_Tag 0;
BA_ "GenSigSwitchedByIgnition" SG_ 1714 UH_Tag 0;
BA_ "GenSigSendType" SG_ 1714 Uhrzeit_01_alt 0;
BA_ "GenSigStartValue" SG_ 1714 Uhrzeit_01_alt 1;
BA_ "GenSigFuncType" SG_ 1714 Uhrzeit_01_alt 5;
BA_ "GenSigSwitchedByIgnition" SG_ 1714 Uhrzeit_01_alt 0;
BA_ "GenSigSendType" SG_ 1714 Vehicle_Driving_Cycle 0;
BA_ "GenSigSwitchedByIgnition" SG_ 1714 Vehicle_Driving_Cycle 0;
BA_ "GenSigSendType" SG_ 1520 BCM1_Stellgroesse_Kl_58s 3;
BA_ "GenSigStartValue" SG_ 1520 BCM1_Stellgroesse_Kl_58s 126;
BA_ "GenSigSwitchedByIgnition" SG_ 1520 BCM1_Stellgroesse_Kl_58s 0;
BA_ "Fehlerwert" SG_ 1520 BCM1_Stellgroesse_Kl_58s 127;
BA_ "GenSigSendType" SG_ 1520 DI_Display_Nachtdesign 3;
BA_ "GenSigSwitchedByIgnition" SG_ 1520 DI_Display_Nachtdesign 0;
BA_ "GenSigSendType" SG_ 1520 DI_Fotosensor 3;
BA_ "GenSigSwitchedByIgnition" SG_ 1520 DI_Fotosensor 0;
BA_ "GenSigSendType" SG_ 1520 DI_KL_58xd 3;
BA_ "GenSigStartValue" SG_ 1520 DI_KL_58xd 254;
BA_ "GenSigSwitchedByIgnition" SG_ 1520 DI_KL_58xd 0;
BA_ "Fehlerwert" SG_ 1520 DI_KL_58xd 255;
BA_ "GenSigSendType" SG_ 1520 DI_KL_58xs 3;
BA_ "GenSigStartValue" SG_ 1520 DI_KL_58xs 126;
BA_ "GenSigSwitchedByIgnition" SG_ 1520 DI_KL_58xs 0;
BA_ "Fehlerwert" SG_ 1520 DI_KL_58xs 127;
BA_ "GenSigSendType" SG_ 1520 DI_KL_58xt 3;
BA_ "GenSigStartValue" SG_ 1520 DI_KL_58xt 126;
BA_ "GenSigSwitchedByIgnition" SG_ 1520 DI_KL_58xt 0;
BA_ "Fehlerwert" SG_ 1520 DI_KL_58xt 127;
BA_ "GenSigSendType" SG_ 420 EA_01_BZ 0;
BA_ "GenSigFuncType" SG_ 420 EA_01_BZ 1;
BA_ "GenSigSendType" SG_ 420 EA_01_CRC 0;
BA_ "GenSigFuncType" SG_ 420 EA_01_CRC 2;
BA_ "GenSigSendType" SG_ 420 EA_01_Sendestatus 6;
BA_ "GenSigSendType" SG_ 420 EA_aktiv_laengs 0;
BA_ "GenSigSendType" SG_ 420 EA_Anf_Prefill 0;
BA_ "GenSigSendType" SG_ 420 EA_Anforderung_HMS 0;
BA_ "GenSigSendType" SG_ 420 EA_Funktionsstatus 0;
BA_ "GenSigSendType" SG_ 420 EA_Gurtstraffer_Anf 3;
BA_ "GenSigSendType" SG_ 420 EA_Parken_beibehalten_HMS 0;
BA_ "GenSigStartValue" SG_ 420 EA_Parken_beibehalten_HMS 2;
BA_ "Fehlerwert" SG_ 420 EA_Parken_beibehalten_HMS 3;
BA_ "GenSigSendType" SG_ 420 EA_PreCrash_Anf 0;
BA_ "GenSigSendType" SG_ 420 EA_Ruckfreigabe 0;
BA_ "GenSigSendType" SG_ 420 EA_Ruckstaerke 0;
BA_ "GenSigSendType" SG_ 420 EA_Sollbeschleunigung 0;
BA_ "GenSigStartValue" SG_ 420 EA_Sollbeschleunigung 2046;
BA_ "Fehlerwert" SG_ 420 EA_Sollbeschleunigung 2047;
BA_ "GenSigSendType" SG_ 420 EA_Warnruckprofil 0;
BA_ "GenSigSendType" SG_ 374 EBKV_03_BZ 0;
BA_ "GenSigFuncType" SG_ 374 EBKV_03_BZ 1;
BA_ "GenSigSwitchedByIgnition" SG_ 374 EBKV_03_BZ 0;
BA_ "GenSigSendType" SG_ 374 EBKV_03_CRC 0;
BA_ "GenSigFuncType" SG_ 374 EBKV_03_CRC 2;
BA_ "GenSigSwitchedByIgnition" SG_ 374 EBKV_03_CRC 0;
BA_ "GenSigSendType" SG_ 374 EBKV_Activate_Fallback_ESP 0;
BA_ "GenSigSwitchedByIgnition" SG_ 374 EBKV_Activate_Fallback_ESP 0;
BA_ "GenSigSendType" SG_ 374 EBKV_Anforderung_HMS 0;
BA_ "GenSigSwitchedByIgnition" SG_ 374 EBKV_Anforderung_HMS 0;
BA_ "GenSigSendType" SG_ 374 EBKV_Aussteuerdruck 0;
BA_ "GenSigStartValue" SG_ 374 EBKV_Aussteuerdruck 254;
BA_ "GenSigSwitchedByIgnition" SG_ 374 EBKV_Aussteuerdruck 0;
BA_ "Fehlerwert" SG_ 374 EBKV_Aussteuerdruck 255;
BA_ "GenSigSendType" SG_ 374 EBKV_Bremspedalweg 0;
BA_ "GenSigSwitchedByIgnition" SG_ 374 EBKV_Bremspedalweg 0;
BA_ "Fehlerwert" SG_ 374 EBKV_Bremspedalweg 255;
BA_ "GenSigSendType" SG_ 374 EBKV_Diagnose 0;
BA_ "GenSigSwitchedByIgnition" SG_ 374 EBKV_Diagnose 0;
BA_ "GenSigSendType" SG_ 374 EBKV_Fahrer_bremst 0;
BA_ "GenSigSwitchedByIgnition" SG_ 374 EBKV_Fahrer_bremst 0;
BA_ "GenSigSendType" SG_ 374 EBKV_Fahrer_bremst_deutlich 0;
BA_ "GenSigSwitchedByIgnition" SG_ 374 EBKV_Fahrer_bremst_deutlich 0;
BA_ "GenSigSendType" SG_ 374 EBKV_Kraftblending_Reserve 0;
BA_ "GenSigStartValue" SG_ 374 EBKV_Kraftblending_Reserve 254;
BA_ "GenSigSwitchedByIgnition" SG_ 374 EBKV_Kraftblending_Reserve 0;
BA_ "Fehlerwert" SG_ 374 EBKV_Kraftblending_Reserve 255;
BA_ "GenSigSendType" SG_ 374 EBKV_OBD_Status 0;
BA_ "GenSigSwitchedByIgnition" SG_ 374 EBKV_OBD_Status 0;
BA_ "GenSigSendType" SG_ 374 EBKV_QBit_Fahrer_bremst 0;
BA_ "GenSigStartValue" SG_ 374 EBKV_QBit_Fahrer_bremst 1;
BA_ "GenSigSwitchedByIgnition" SG_ 374 EBKV_QBit_Fahrer_bremst 0;
BA_ "GenSigSendType" SG_ 374 EBKV_Restdruckabsenkung 0;
BA_ "GenSigSwitchedByIgnition" SG_ 374 EBKV_Restdruckabsenkung 0;
BA_ "GenSigSendType" SG_ 374 EBKV_Status_02 0;
BA_ "GenSigSwitchedByIgnition" SG_ 374 EBKV_Status_02 0;
BA_ "GenSigSendType" SG_ 374 EBKV_Textanzeigen 0;
BA_ "GenSigSwitchedByIgnition" SG_ 374 EBKV_Textanzeigen 0;
BA_ "GenSigSendType" SG_ 374 EBKV_VMM_Sek_Notstopp_Status 0;
BA_ "GenSigSwitchedByIgnition" SG_ 374 EBKV_VMM_Sek_Notstopp_Status 0;
BA_ "GenSigSendType" SG_ 374 EPB_Status_ext 0;
BA_ "GenSigStartValue" SG_ 374 EPB_Status_ext 6;
BA_ "GenSigSwitchedByIgnition" SG_ 374 EPB_Status_ext 0;
BA_ "GenSigSendType" SG_ 374 SBS_Anforderung_GE 0;
BA_ "GenSigSwitchedByIgnition" SG_ 374 SBS_Anforderung_GE 0;
BA_ "GenSigSendType" SG_ 374 SOK_EBKV_03_Signatur 0;
BA_ "GenSigFuncType" SG_ 374 SOK_EBKV_03_Signatur 15;
BA_ "GenSigSendType" SG_ 2589283963 EBKV_Indc_StChk 0;
BA_ "GenSigStartValue" SG_ 2589283963 EBKV_Indc_StChk 1;
BA_ "GenSigSwitchedByIgnition" SG_ 2589283963 EBKV_Indc_StChk 0;
BA_ "GenSigSendType" SG_ 2589283963 EBKV_Indc_StFail 0;
BA_ "GenSigSwitchedByIgnition" SG_ 2589283963 EBKV_Indc_StFail 0;
BA_ "GenSigSendType" SG_ 2589283963 EBKV_OBD_Status_Auth 0;
BA_ "GenSigSwitchedByIgnition" SG_ 2589283963 EBKV_OBD_Status_Auth 0;
BA_ "GenSigSendType" SG_ 2589283963 OBDProtocol_EBKV 0;
BA_ "GenSigStartValue" SG_ 2589283963 OBDProtocol_EBKV 254;
BA_ "GenSigSwitchedByIgnition" SG_ 2589283963 OBDProtocol_EBKV 0;
BA_ "Fehlerwert" SG_ 2589283963 OBDProtocol_EBKV 255;
BA_ "GenSigSendType" SG_ 2589283963 SOK_EBKV_05_Signatur 0;
BA_ "GenSigFuncType" SG_ 2589283963 SOK_EBKV_05_Signatur 15;
BA_ "GenSigSwitchedByIgnition" SG_ 2589283963 SOK_EBKV_05_Signatur 0;
BA_ "GenSigSendType" SG_ 1603 KBI_Einheit_Datum 3;
BA_ "GenSigSwitchedByIgnition" SG_ 1603 KBI_Einheit_Datum 0;
BA_ "GenSigSendType" SG_ 1603 KBI_Einheit_Druck 3;
BA_ "GenSigSwitchedByIgnition" SG_ 1603 KBI_Einheit_Druck 0;
BA_ "GenSigSendType" SG_ 1603 KBI_Einheit_Masse 3;
BA_ "GenSigSwitchedByIgnition" SG_ 1603 KBI_Einheit_Masse 0;
BA_ "GenSigSendType" SG_ 1603 KBI_Einheit_Sprache 3;
BA_ "GenSigSwitchedByIgnition" SG_ 1603 KBI_Einheit_Sprache 0;
BA_ "GenSigSendType" SG_ 1603 KBI_Einheit_Streckenanz 3;
BA_ "GenSigSwitchedByIgnition" SG_ 1603 KBI_Einheit_Streckenanz 0;
BA_ "GenSigSendType" SG_ 1603 KBI_Einheit_Tacho 3;
BA_ "GenSigSwitchedByIgnition" SG_ 1603 KBI_Einheit_Tacho 0;
BA_ "GenSigSendType" SG_ 1603 KBI_Einheit_Temp 3;
BA_ "GenSigSwitchedByIgnition" SG_ 1603 KBI_Einheit_Temp 0;
BA_ "GenSigSendType" SG_ 1603 KBI_Einheit_Uhrzeit 3;
BA_ "GenSigSwitchedByIgnition" SG_ 1603 KBI_Einheit_Uhrzeit 0;
BA_ "GenSigSendType" SG_ 1603 KBI_Einheit_Verbrauch 3;
BA_ "GenSigSwitchedByIgnition" SG_ 1603 KBI_Einheit_Verbrauch 0;
BA_ "GenSigSendType" SG_ 1603 KBI_Einheit_Verbrauch_elektr 3;
BA_ "GenSigSwitchedByIgnition" SG_ 1603 KBI_Einheit_Verbrauch_elektr 0;
BA_ "GenSigSendType" SG_ 1603 KBI_Einheit_Verbrauch_Gas 3;
BA_ "GenSigSwitchedByIgnition" SG_ 1603 KBI_Einheit_Verbrauch_Gas 0;
BA_ "GenSigSendType" SG_ 1603 KBI_Einheit_Volumen 3;
BA_ "GenSigSwitchedByIgnition" SG_ 1603 KBI_Einheit_Volumen 0;
BA_ "GenSigSendType" SG_ 1603 KBI_MFA_v_Einheit_02 3;
BA_ "GenSigSwitchedByIgnition" SG_ 1603 KBI_MFA_v_Einheit_02 0;
BA_ "GenSigSendType" SG_ 192 EM1_01_BZ 0;
BA_ "GenSigFuncType" SG_ 192 EM1_01_BZ 1;
BA_ "GenSigSwitchedByIgnition" SG_ 192 EM1_01_BZ 0;
BA_ "GenSigSendType" SG_ 192 EM1_01_CRC 0;
BA_ "GenSigFuncType" SG_ 192 EM1_01_CRC 2;
BA_ "GenSigSwitchedByIgnition" SG_ 192 EM1_01_CRC 0;
BA_ "GenSigSendType" SG_ 192 EM1_AR_aktiv 0;
BA_ "GenSigSwitchedByIgnition" SG_ 192 EM1_AR_aktiv 0;
BA_ "GenSigSendType" SG_ 192 EM1_ErwGrenzen_aktiv 0;
BA_ "GenSigSwitchedByIgnition" SG_ 192 EM1_ErwGrenzen_aktiv 0;
BA_ "GenSigSendType" SG_ 192 EM1_Fehler_ElAntriebAbschaltung 0;
BA_ "GenSigSwitchedByIgnition" SG_ 192 EM1_Fehler_ElAntriebAbschaltung 0;
BA_ "GenSigSendType" SG_ 192 EM1_Fehler_Notabschaltung 0;
BA_ "GenSigSwitchedByIgnition" SG_ 192 EM1_Fehler_Notabschaltung 0;
BA_ "Fehlerwert" SG_ 192 EM1_Fehler_Notabschaltung 1;
BA_ "GenSigSendType" SG_ 192 EM1_IstDrehzahl 0;
BA_ "GenSigStartValue" SG_ 192 EM1_IstDrehzahl 32766;
BA_ "GenSigSwitchedByIgnition" SG_ 192 EM1_IstDrehzahl 0;
BA_ "Fehlerwert" SG_ 192 EM1_IstDrehzahl 32767;
BA_ "GenSigSendType" SG_ 192 EM1_Istmodus 0;
BA_ "GenSigStartValue" SG_ 192 EM1_Istmodus 15;
BA_ "GenSigSwitchedByIgnition" SG_ 192 EM1_Istmodus 0;
BA_ "GenSigSendType" SG_ 192 EM1_IstMoment 0;
BA_ "GenSigStartValue" SG_ 192 EM1_IstMoment 4094;
BA_ "GenSigSwitchedByIgnition" SG_ 192 EM1_IstMoment 0;
BA_ "Fehlerwert" SG_ 192 EM1_IstMoment 4095;
BA_ "GenSigSendType" SG_ 192 EM1_IstSpannung 0;
BA_ "GenSigStartValue" SG_ 192 EM1_IstSpannung 4094;
BA_ "GenSigSwitchedByIgnition" SG_ 192 EM1_IstSpannung 0;
BA_ "Fehlerwert" SG_ 192 EM1_IstSpannung 4095;
BA_ "GenSigSendType" SG_ 192 EM1_Max_Moment 0;
BA_ "GenSigStartValue" SG_ 192 EM1_Max_Moment 2046;
BA_ "GenSigSwitchedByIgnition" SG_ 192 EM1_Max_Moment 0;
BA_ "Fehlerwert" SG_ 192 EM1_Max_Moment 2047;
BA_ "GenSigSendType" SG_ 192 EM1_Max_Moment_Gesamt 0;
BA_ "GenSigStartValue" SG_ 192 EM1_Max_Moment_Gesamt 2046;
BA_ "GenSigSwitchedByIgnition" SG_ 192 EM1_Max_Moment_Gesamt 0;
BA_ "Fehlerwert" SG_ 192 EM1_Max_Moment_Gesamt 2047;
BA_ "GenSigSendType" SG_ 192 EM1_Max_Moment_Lim 0;
BA_ "GenSigStartValue" SG_ 192 EM1_Max_Moment_Lim 2046;
BA_ "GenSigSwitchedByIgnition" SG_ 192 EM1_Max_Moment_Lim 0;
BA_ "Fehlerwert" SG_ 192 EM1_Max_Moment_Lim 2047;
BA_ "GenSigSendType" SG_ 192 EM1_Min_Moment 0;
BA_ "GenSigStartValue" SG_ 192 EM1_Min_Moment 2046;
BA_ "GenSigSwitchedByIgnition" SG_ 192 EM1_Min_Moment 0;
BA_ "Fehlerwert" SG_ 192 EM1_Min_Moment 2047;
BA_ "GenSigSendType" SG_ 192 EM1_Min_Moment_Gesamt 0;
BA_ "GenSigStartValue" SG_ 192 EM1_Min_Moment_Gesamt 2046;
BA_ "GenSigSwitchedByIgnition" SG_ 192 EM1_Min_Moment_Gesamt 0;
BA_ "Fehlerwert" SG_ 192 EM1_Min_Moment_Gesamt 2047;
BA_ "GenSigSendType" SG_ 192 EM1_Min_Moment_Lim 0;
BA_ "GenSigStartValue" SG_ 192 EM1_Min_Moment_Lim 2046;
BA_ "GenSigSwitchedByIgnition" SG_ 192 EM1_Min_Moment_Lim 0;
BA_ "Fehlerwert" SG_ 192 EM1_Min_Moment_Lim 2047;
BA_ "GenSigSendType" SG_ 192 EM1_Mom_DrzEingriff 0;
BA_ "GenSigStartValue" SG_ 192 EM1_Mom_DrzEingriff 2046;
BA_ "GenSigSwitchedByIgnition" SG_ 192 EM1_Mom_DrzEingriff 0;
BA_ "Fehlerwert" SG_ 192 EM1_Mom_DrzEingriff 2047;
BA_ "GenSigSendType" SG_ 192 EM1_Moment_AR_Eingriff 0;
BA_ "GenSigStartValue" SG_ 192 EM1_Moment_AR_Eingriff 4094;
BA_ "GenSigSwitchedByIgnition" SG_ 192 EM1_Moment_AR_Eingriff 0;
BA_ "Fehlerwert" SG_ 192 EM1_Moment_AR_Eingriff 4095;
BA_ "GenSigSendType" SG_ 192 EM1_Raddrehzahl_links 0;
BA_ "GenSigStartValue" SG_ 192 EM1_Raddrehzahl_links 8190;
BA_ "GenSigSwitchedByIgnition" SG_ 192 EM1_Raddrehzahl_links 0;
BA_ "Fehlerwert" SG_ 192 EM1_Raddrehzahl_links 8191;
BA_ "GenSigSendType" SG_ 192 EM1_Raddrehzahl_rechts 0;
BA_ "GenSigStartValue" SG_ 192 EM1_Raddrehzahl_rechts 8190;
BA_ "GenSigSwitchedByIgnition" SG_ 192 EM1_Raddrehzahl_rechts 0;
BA_ "Fehlerwert" SG_ 192 EM1_Raddrehzahl_rechts 8191;
BA_ "GenSigSendType" SG_ 192 EM1_Status_DrzEingriff 0;
BA_ "GenSigSwitchedByIgnition" SG_ 192 EM1_Status_DrzEingriff 0;
BA_ "Fehlerwert" SG_ 192 EM1_Status_DrzEingriff 3;
BA_ "GenSigSendType" SG_ 192 EM1_Strom_HV 0;
BA_ "GenSigStartValue" SG_ 192 EM1_Strom_HV 4094;
BA_ "GenSigSwitchedByIgnition" SG_ 192 EM1_Strom_HV 0;
BA_ "Fehlerwert" SG_ 192 EM1_Strom_HV 4095;
BA_ "GenSigSendType" SG_ 184 EM1_Abregelung_Temperatur 0;
BA_ "GenSigSwitchedByIgnition" SG_ 184 EM1_Abregelung_Temperatur 0;
BA_ "GenSigSendType" SG_ 184 EM1_AnlernenElMotor_Anf 0;
BA_ "GenSigSwitchedByIgnition" SG_ 184 EM1_AnlernenElMotor_Anf 0;
BA_ "GenSigSendType" SG_ 184 EM1_AR_aktiv 0;
BA_ "GenSigSwitchedByIgnition" SG_ 184 EM1_AR_aktiv 0;
BA_ "GenSigSendType" SG_ 184 EM1_Eta_Sys 0;
BA_ "GenSigStartValue" SG_ 184 EM1_Eta_Sys 510;
BA_ "GenSigSwitchedByIgnition" SG_ 184 EM1_Eta_Sys 0;
BA_ "Fehlerwert" SG_ 184 EM1_Eta_Sys 511;
BA_ "GenSigSendType" SG_ 184 EM1_Fehler_ElAntriebFreilauf_Anf 0;
BA_ "GenSigSwitchedByIgnition" SG_ 184 EM1_Fehler_ElAntriebFreilauf_Anf 0;
BA_ "GenSigSendType" SG_ 184 EM1_Freigabe_Info_WFS 3;
BA_ "GenSigSwitchedByIgnition" SG_ 184 EM1_Freigabe_Info_WFS 0;
BA_ "GenSigSendType" SG_ 184 EM1_Freigabe_Verfallsinfo_WFS 3;
BA_ "GenSigSwitchedByIgnition" SG_ 184 EM1_Freigabe_Verfallsinfo_WFS 0;
BA_ "GenSigSendType" SG_ 184 EM1_HV_betriebsbereit 0;
BA_ "GenSigSwitchedByIgnition" SG_ 184 EM1_HV_betriebsbereit 0;
BA_ "GenSigSendType" SG_ 184 EM1_IstStrom 0;
BA_ "GenSigStartValue" SG_ 184 EM1_IstStrom 2046;
BA_ "GenSigSwitchedByIgnition" SG_ 184 EM1_IstStrom 0;
BA_ "Fehlerwert" SG_ 184 EM1_IstStrom 2047;
BA_ "GenSigSendType" SG_ 184 EM1_Moment_HVVerbraucher 0;
BA_ "GenSigStartValue" SG_ 184 EM1_Moment_HVVerbraucher 1023;
BA_ "GenSigSwitchedByIgnition" SG_ 184 EM1_Moment_HVVerbraucher 0;
BA_ "GenSigSendType" SG_ 184 EM1_Parken_WFS_Status 3;
BA_ "GenSigSwitchedByIgnition" SG_ 184 EM1_Parken_WFS_Status 0;
BA_ "GenSigSendType" SG_ 184 EM1_Sperr_Info_WFS 3;
BA_ "GenSigSwitchedByIgnition" SG_ 184 EM1_Sperr_Info_WFS 0;
BA_ "GenSigSendType" SG_ 184 LE_Kuehlmittel_Sensor 3;
BA_ "GenSigSwitchedByIgnition" SG_ 184 LE_Kuehlmittel_Sensor 0;
BA_REL_ "GenSigTimeoutTime" BU_SG_REL_ Gateway_Max SG_ 192 EM1_Istmodus 500;
BA_REL_ "GenSigTimeoutTime" BU_SG_REL_ Gateway_Max SG_ 192 EM1_IstMoment 500;
BA_REL_ "GenSigTimeoutTime" BU_SG_REL_ Gateway_Max SG_ 192 EM1_IstDrehzahl 500;
BA_REL_ "GenSigTimeoutTime" BU_SG_REL_ Gateway_Max SG_ 192 EM1_IstSpannung 500;
BA_REL_ "GenSigTimeoutTime" BU_SG_REL_ Gateway_Max SG_ 192 EM1_Strom_HV 500;
BA_REL_ "GenSigTimeoutTime" BU_SG_REL_ Gateway_Max SG_ 192 EM1_Fehler_Notabschaltung 500;
BA_REL_ "GenSigTimeoutTime" BU_SG_REL_ Getriebe_DQ SG_ 2463978646 CHA_Fahrer_Umschaltung 5000;
BA_REL_ "GenSigTimeoutTime" BU_SG_REL_ Getriebe_DQ SG_ 2463978646 CHA_Ziel_FahrPr_GE 5000;
BA_REL_ "GenSigTimeoutTime" BU_SG_REL_ Getriebe_DQ SG_ 1714 DGN_Verlernzaehler 5000;
BA_REL_ "GenSigTimeoutTime" BU_SG_REL_ Getriebe_DQ SG_ 1714 KBI_Kilometerstand 5000;
BA_REL_ "GenSigTimeoutTime" BU_SG_REL_ Getriebe_DQ SG_ 1714 UH_Jahr 5000;
BA_REL_ "GenSigTimeoutTime" BU_SG_REL_ Getriebe_DQ SG_ 1714 UH_Monat 5000;
BA_REL_ "GenSigTimeoutTime" BU_SG_REL_ Getriebe_DQ SG_ 1714 UH_Tag 5000;
BA_REL_ "GenSigTimeoutTime" BU_SG_REL_ Getriebe_DQ SG_ 1714 UH_Stunde 5000;
BA_REL_ "GenSigTimeoutTime" BU_SG_REL_ Getriebe_DQ SG_ 1714 UH_Minute 5000;
BA_REL_ "GenSigTimeoutTime" BU_SG_REL_ Getriebe_DQ SG_ 1714 UH_Sekunde 5000;
BA_REL_ "GenSigTimeoutTime" BU_SG_REL_ Getriebe_DQ SG_ 374 SBS_Anforderung_GE 500;
BA_REL_ "GenSigTimeoutTime" BU_SG_REL_ Motor_konv SG_ 397 BMS_MV_IstStrom 500;
BA_REL_ "GenSigTimeoutTime" BU_SG_REL_ Motor_konv SG_ 397 BMS_MV_IstSpannung 500;
BA_REL_ "GenSigTimeoutTime" BU_SG_REL_ Motor_konv SG_ 397 BMS_MV_SOC_HiRes 500;
BA_REL_ "GenSigTimeoutTime" BU_SG_REL_ Motor_konv SG_ 419 BMS_MV_MaxDyn_EntladeStrom 500;
BA_REL_ "GenSigTimeoutTime" BU_SG_REL_ Motor_konv SG_ 419 BMS_MV_MaxDyn_LadeStrom 500;
BA_REL_ "GenSigTimeoutTime" BU_SG_REL_ Motor_konv SG_ 2589283412 BMS_MV_Temperatur 5000;
BA_REL_ "GenSigTimeoutTime" BU_SG_REL_ Motor_konv SG_ 2589283608 BMS_MV_Energieinhalt 5000;
BA_REL_ "GenSigTimeoutTime" BU_SG_REL_ Motor_konv SG_ 2589283608 BMS_MV_MaxEnergieinhalt 5000;
BA_REL_ "GenSigTimeoutTime" BU_SG_REL_ Motor_konv SG_ 2589283606 BMS_MV_SOC_Kaltstart 5000;
BA_REL_ "GenSigTimeoutTime" BU_SG_REL_ Motor_konv SG_ 2589283606 BMS_MV_max_Grenz_SOC 5000;
BA_REL_ "GenSigTimeoutTime" BU_SG_REL_ Motor_konv SG_ 1021 BMS_MV_SOHC_DiagSOC 1000;
BA_REL_ "GenSigTimeoutTime" BU_SG_REL_ Motor_konv SG_ 1021 BMS_MV_SOHC_DiagStatus 1000;
BA_REL_ "GenSigTimeoutTime" BU_SG_REL_ Motor_konv SG_ 1021 BMS_MV_Pred_Entladeperformance 1000;
BA_REL_ "GenSigTimeoutTime" BU_SG_REL_ Motor_konv SG_ 1021 BMS_MV_Pred_Ladeperformance 1000;
BA_REL_ "GenSigTimeoutTime" BU_SG_REL_ Motor_konv SG_ 2463978716 BMS_MV_Leistungsreduzierung 1000;
BA_REL_ "GenSigTimeoutTime" BU_SG_REL_ Motor_konv SG_ 2463978716 BMS_MV_Fehler_Leistungsred 1000;
BA_REL_ "GenSigTimeoutTime" BU_SG_REL_ Motor_konv SG_ 2463978717 BMS_MV_PerfInd_Entladen 1000;
BA_REL_ "GenSigTimeoutTime" BU_SG_REL_ Motor_konv SG_ 2463978717 BMS_MV_PerfInd_Laden 1000;
BA_REL_ "GenSigTimeoutTime" BU_SG_REL_ Motor_konv SG_ 2463978717 BMS_MV_Max_EntladeLeistung 1000;
BA_REL_ "GenSigTimeoutTime" BU_SG_REL_ Motor_konv SG_ 2463978717 BMS_MV_Max_LadeLeistung 1000;
BA_REL_ "GenSigTimeoutTime" BU_SG_REL_ Motor_konv SG_ 2463978718 BMS_MV_Max_EntladeStrom_Lim 1000;
BA_REL_ "GenSigTimeoutTime" BU_SG_REL_ Motor_konv SG_ 2463978718 BMS_MV_Max_LadeStrom_Lim 1000;
BA_REL_ "GenSigTimeoutTime" BU_SG_REL_ Motor_konv SG_ 2463978718 BMS_MV_Min_EntladeSpannung_Lim 1000;
BA_REL_ "GenSigTimeoutTime" BU_SG_REL_ Motor_konv SG_ 2463978718 BMS_MV_Max_LadeSpannung_Lim 1000;
BA_REL_ "GenSigTimeoutTime" BU_SG_REL_ Motor_konv SG_ 2589283543 SOK_BMS_MV_15_Signatur 5000;
BA_REL_ "GenSigTimeoutTime" BU_SG_REL_ Motor_konv SG_ 2589283523 OBDProtocol_BMS_48V 5000;
BA_REL_ "GenSigTimeoutTime" BU_SG_REL_ Motor_konv SG_ 2589283523 BMS_MV_OBD_Lampe_Anf 5000;
BA_REL_ "GenSigTimeoutTime" BU_SG_REL_ Motor_konv SG_ 2589283523 BMS_48V_Indc_StChk 5000;
BA_REL_ "GenSigTimeoutTime" BU_SG_REL_ Motor_konv SG_ 2589283523 BMS_48V_Indc_StFail 5000;
BA_REL_ "GenSigTimeoutTime" BU_SG_REL_ Motor_konv SG_ 2589283523 BMS_MV_Dauer_EntladeLeistung 5000;
BA_REL_ "GenSigTimeoutTime" BU_SG_REL_ Motor_konv SG_ 2589283523 BMS_MV_Dauer_LadeLeistung 5000;
BA_REL_ "GenSigTimeoutTime" BU_SG_REL_ Motor_konv SG_ 2589283523 BMS_MV_Dauer_RMS_Strom 5000;
BA_REL_ "GenSigTimeoutTime" BU_SG_REL_ Motor_konv SG_ 2589283524 BMS_MV_EntladeEnergie 5000;
BA_REL_ "GenSigTimeoutTime" BU_SG_REL_ Motor_konv SG_ 2589283524 BMS_MV_LadeEnergie 5000;
BA_REL_ "GenSigTimeoutTime" BU_SG_REL_ Motor_konv SG_ 2589283524 BMS_MV_Max_RMS_Strom 5000;
BA_REL_ "GenSigTimeoutTime" BU_SG_REL_ Motor_konv SG_ 2527679928 BMS_NV_OBD_Lampe_Anf 5000;
BA_REL_ "GenSigTimeoutTime" BU_SG_REL_ Motor_konv SG_ 2527679928 BMS_NV_Indc_StChk 5000;
BA_REL_ "GenSigTimeoutTime" BU_SG_REL_ Motor_konv SG_ 2527679928 BMS_NV_Indc_StFail 5000;
BA_REL_ "GenSigTimeoutTime" BU_SG_REL_ Motor_konv SG_ 2527679928 OBDProtocol_BMS_NV 5000;
BA_REL_ "GenSigTimeoutTime" BU_SG_REL_ Motor_konv SG_ 2527679928 SOK_BMS_NV_11_Signatur 5000;
BA_REL_ "GenSigTimeoutTime" BU_SG_REL_ Motor_konv SG_ 2463978646 CHA_Fahrer_Umschaltung 5000;
BA_REL_ "GenSigTimeoutTime" BU_SG_REL_ Motor_konv SG_ 2463978646 CHA_Ziel_FahrPr_MO 5000;
BA_REL_ "GenSigTimeoutTime" BU_SG_REL_ Motor_konv SG_ 2463978646 CHA_Ziel_FahrPr_MO_BZS 5000;
BA_REL_ "GenSigTimeoutTime" BU_SG_REL_ Motor_konv SG_ 2463978646 CHA_Ziel_FahrPr_SAK 5000;
BA_REL_ "GenSigTimeoutTime" BU_SG_REL_ Motor_konv SG_ 2463978646 CHA_Ziel_FahrPr_MO_StSt 5000;
BA_REL_ "GenSigTimeoutTime" BU_SG_REL_ Motor_konv SG_ 2463978646 CHA_Ziel_FahrPr_AGK 5000;
BA_REL_ "GenSigTimeoutTime" BU_SG_REL_ Motor_konv SG_ 1484 DC_MV_IstModus_02 5000;
BA_REL_ "GenSigTimeoutTime" BU_SG_REL_ Motor_konv SG_ 1714 KBI_Kilometerstand 5000;
BA_REL_ "GenSigTimeoutTime" BU_SG_REL_ Motor_konv SG_ 1714 UH_Jahr 5000;
BA_REL_ "GenSigTimeoutTime" BU_SG_REL_ Motor_konv SG_ 1714 UH_Monat 5000;
BA_REL_ "GenSigTimeoutTime" BU_SG_REL_ Motor_konv SG_ 1714 UH_Tag 5000;
BA_REL_ "GenSigTimeoutTime" BU_SG_REL_ Motor_konv SG_ 1714 UH_Stunde 5000;
BA_REL_ "GenSigTimeoutTime" BU_SG_REL_ Motor_konv SG_ 1714 UH_Minute 5000;
BA_REL_ "GenSigTimeoutTime" BU_SG_REL_ Motor_konv SG_ 1714 UH_Sekunde 5000;
BA_REL_ "GenSigTimeoutTime" BU_SG_REL_ Motor_konv SG_ 420 EA_01_CRC 5000;
BA_REL_ "GenSigTimeoutTime" BU_SG_REL_ Motor_konv SG_ 420 EA_01_BZ 5000;
BA_REL_ "GenSigTimeoutTime" BU_SG_REL_ Motor_konv SG_ 420 EA_aktiv_laengs 5000;
BA_REL_ "GenSigTimeoutTime" BU_SG_REL_ Motor_konv SG_ 420 EA_Funktionsstatus 5000;
BA_REL_ "GenSigTimeoutTime" BU_SG_REL_ Motor_konv SG_ 420 EA_Sollbeschleunigung 5000;
BA_REL_ "GenSigTimeoutTime" BU_SG_REL_ Motor_konv SG_ 374 EBKV_03_CRC 500;
BA_REL_ "GenSigTimeoutTime" BU_SG_REL_ Motor_konv SG_ 374 EBKV_03_BZ 500;
BA_REL_ "GenSigTimeoutTime" BU_SG_REL_ Motor_konv SG_ 374 EBKV_Status_02 500;
BA_REL_ "GenSigTimeoutTime" BU_SG_REL_ Motor_konv SG_ 374 EBKV_Fahrer_bremst 500;
BA_REL_ "GenSigTimeoutTime" BU_SG_REL_ Motor_konv SG_ 374 EBKV_QBit_Fahrer_bremst 500;
BA_REL_ "GenSigTimeoutTime" BU_SG_REL_ Motor_konv SG_ 374 EBKV_OBD_Status 500;
BA_REL_ "GenSigTimeoutTime" BU_SG_REL_ Motor_konv SG_ 374 EBKV_Bremspedalweg 500;
BA_REL_ "GenSigTimeoutTime" BU_SG_REL_ Motor_konv SG_ 2589283963 EBKV_OBD_Status_Auth 5000;
BA_REL_ "GenSigTimeoutTime" BU_SG_REL_ Motor_konv SG_ 2589283963 EBKV_Indc_StChk 5000;
BA_REL_ "GenSigTimeoutTime" BU_SG_REL_ Motor_konv SG_ 2589283963 EBKV_Indc_StFail 5000;
BA_REL_ "GenSigTimeoutTime" BU_SG_REL_ Motor_konv SG_ 2589283963 OBDProtocol_EBKV 5000;
BA_REL_ "GenSigTimeoutTime" BU_SG_REL_ Motor_konv SG_ 2589283963 SOK_EBKV_05_Signatur 5000;
BA_REL_ "GenSigTimeoutTime" BU_SG_REL_ Motor_konv SG_ 1603 KBI_Einheit_Streckenanz 5000;
BA_REL_ "GenSigTimeoutTime" BU_SG_REL_ Motor_konv SG_ 1603 KBI_Einheit_Volumen 5000;
BA_REL_ "GenSigTimeoutTime" BU_SG_REL_ Motor_konv SG_ 1603 KBI_Einheit_Tacho 5000;
BA_REL_ "GenSigTimeoutTime" BU_SG_REL_ Schaltbetaetigung SG_ 1520 DI_KL_58xd 2000;
BA_REL_ "GenSigTimeoutTime" BU_SG_REL_ Schaltbetaetigung SG_ 1520 DI_KL_58xt 2000;
VAL_ 2463978705 BMS_Warnung_Stuetzung_NV 0 "Stuetzung_iO" 1 "Stuetzung_niO" 6 "Init" 7 "Fehler" ;
VAL_ 2463978705 BMS_Status_EoHVL_Heizer 0 "Init" 1 "Keine_offene_HV_Leitung_erkannt" 2 "offene_HV_Leitung_erkannt" 3 "Fehler" ;
VAL_ 2463978705 BMS_Ladezustand 2046 "Init" 2047 "Fehler" ;
VAL_ 2463978705 BMS_PerfInd_Entladen 1022 "Init" ;
VAL_ 2463978705 BMS_PerfInd_Laden 1022 "Init" ;
VAL_ 2463978705 BMS_Nutzbare_EntladeEnergie 65534 "Init" 65535 "Fehler" ;
VAL_ 2589283664 BMS_Balancing_Aktiv 0 "Init" 1 "aktiv" 2 "nicht_aktiv" ;
VAL_ 2589283664 BMS_Ladevorgang_aktiv 0 "inaktiv" 1 "aktiv" ;
VAL_ 2589283664 BMS_RIso_Ext 4094 "Init" 4095 "Fehler" ;
VAL_ 2589283664 BMS_Min_Ladezustand 2046 "Init" ;
VAL_ 2589283664 BMS_Max_Energie 8190 "Init" ;
VAL_ 2589283664 BMS_Max_Ladezustand 2046 "Init" ;
VAL_ 2589283665 BMS_BattHeizung_VerbautStatus 0 "nicht_verbaut" 1 "verbaut" ;
VAL_ 2589283665 BMS_Fehler_NTKreis 0 "kein_Fehler" 1 "Fehler" ;
VAL_ 2589283665 BMS_Temperierung_Anf 0 "hoher_Kuehlbedarf" 1 "mittlerer_Kuehlbedarf" 2 "niedriger_Kuehlbedarf" 3 "kein_Temperierungsbedarf_Init" 4 "niedriger_Heizbedarf" 5 "mittlerer_Heizbedarf" 6 "hoher_Heizbedarf" 7 "Umwaelzungsbedarf" ;
VAL_ 2589283665 BMS_Status_Ventil1 0 "Ventil_nicht_angesteuert" 1 "Ventil_angesteuert" 2 "reserviert" 3 "reserviert" 4 "reserviert" 5 "Ventil_nicht_verbaut" 6 "Init" 7 "Fehler" ;
VAL_ 2589283665 BMS_Status_Ventil2 0 "Ventil_nicht_angesteuert" 1 "Ventil_angesteuert" 2 "reserviert" 3 "reserviert" 4 "reserviert" 5 "Ventil_nicht_verbaut" 6 "Init" 7 "Fehler" ;
VAL_ 2589283665 BMS_Pumpe1_Ansteuerung 13 "nicht_verbaut" 14 "Init" 15 "Fehler" ;
VAL_ 2589283665 BMS_Pumpe2_Ansteuerung 13 "nicht_verbaut" 14 "Init" 15 "Fehler" ;
VAL_ 2589283665 BMS_VorlaufTemperatur 253 "nicht_verbaut" 254 "Init" 255 "Fehler" ;
VAL_ 2589283665 BMS_Temperatur 254 "Init" 255 "Fehler" ;
VAL_ 2589283665 BMS_SollVorlauftemperatur 254 "Init" 255 "Fehler" ;
VAL_ 2589283665 BMS_RuecklaufTemperatur 253 "nicht_verbaut" 254 "Init" 255 "Fehler" ;
VAL_ 2589283760 BMS_Max_Spannung 1022 "Init" ;
VAL_ 2589283760 BMS_Min_Spannung 1022 "Init" ;
VAL_ 2589283760 BMS_Dauer_Entladeleistung 4094 "Init" ;
VAL_ 2589283760 BMS_Dauer_Ladeleistung 4094 "Init" ;
VAL_ 2589283762 BMS_TempStatus_Entladen 0 "Init" 1 "Temperatur_kleiner_optimal" 2 "Temperatur_optimal" 3 "Temperatur_groesser_optimal" 7 "Fehler" ;
VAL_ 2589283762 BMS_TempStatus_Laden 0 "Init" 1 "Temperatur_kleiner_optimal" 2 "Temperatur_optimal" 3 "Temperatur_groesser_optimal" 7 "Fehler" ;
VAL_ 2589283762 BMS_PerfInd_EntladenPeak_Temp 510 "Init" 511 "Fehler" ;
VAL_ 2589283762 BMS_PerfInd_LadenPeak_Temp 510 "Init" 511 "Fehler" ;
VAL_ 2589283762 BMS_TMA_Kuehlkreis_Status 0 "Off" 1 "Umwaelzbetrieb" 2 "Kuehlung_1_Kreis_Betrieb" 3 "Heizung_1_Kreis_Betrieb" 4 "Aktive_Kuehlung_2_Kreis_Betrieb" 5 "Aktive_Heizung_2_Kreis_Betrieb" 15 "Fehler" ;
VAL_ 2589283762 BMS_TMA_Betriebsart 0 "BA_TMA_Off" 1 "BA_TMA_Drv" 2 "BA_TMA_DrvLadVoKo" 3 "BA_TMA_AC" 4 "BA_TMA_DC" 5 "BA_TMA_BiDi" 6 "BA_TMA_HeatTransferWP" 7 "BA_TMA_VoKo" 8 "BA_TMA_Nachlauf" 9 "BA_TMA_OffgridAuto" 10 "BA_TMA_OffgridBCCM" 11 "BA_TMA_KonservierungBCCM" 12 "BA_TMA_NachlaufBCCM" 26 "BA_TMA_Transport" 27 "BA_TMA_BremsReku" 28 "BA_TMA_Befuellung" 29 "BA_TMA_RoutineControl" 30 "Init" 31 "Fehler" ;
VAL_ 2589283762 BMS_eTM_KonditionierWunsch 0 "kein_Temperierwunsch" 1 "Kuehlwunsch" 2 "Heizwunsch" ;
VAL_ 2589283762 BMS_SollVolumenstrom 62 "Init" 63 "Fehler" ;
VAL_ 2331595856 BMS_UBE 65534 "Init" 65535 "Fehler" ;
VAL_ 2331595856 BMS_UBE_T 65534 "Init" 65535 "Fehler" ;
VAL_ 2331595856 BMS_Max_UBE 65534 "Init" 65535 "Fehler" ;
VAL_ 2331595856 BMS_Nennspannung 2046 "Init" ;
VAL_ 2331595856 BMS_DC_Ladeschuetze_Ist 0 "geoeffnet" 1 "geschlossen" 2 "reserviert" 3 "reserviert" 4 "reserviert" 5 "nicht_verbaut" 6 "Init" 7 "Schuetzfehler" ;
VAL_ 2331595856 BMS_Hauptschuetze_Ist 0 "geoeffnet" 1 "geschlossen" 2 "reserviert" 3 "reserviert" 4 "reserviert" 5 "nicht_verbaut" 6 "Init" 7 "Schuetzfehler" ;
VAL_ 2331595856 BMS_UBE_Indikator 2042 "Funktion_nicht_vorhanden" 2043 "kleiner_0" 2044 "groesser_100" 2045 "nicht_angelernt" 2046 "Init" 2047 "Fehler" ;
VAL_ 2331595856 BMS_UBE_Indik_last_update_km 1048573 "Funktion_nicht_umgesetzt" 1048574 "Init" 1048575 "Fehler" ;
VAL_ 2331595856 BMS_Last_Chg_adeq_SOCswing_Day 0 "Funktion_nicht_verwendet" ;
VAL_ 2331595856 BMS_Last_Chg_adeq_SOCswing_Month 0 "Funktion_nicht_verwendet" ;
VAL_ 2331595856 BMS_Last_Chg_adeq_SOCswing_Year 0 "Funktion_nicht_verwendet" ;
VAL_ 2331595856 BMS_EnergieVorhalt 65533 "Funktion_nicht_umgesetzt" 65534 "Init" 65535 "Fehler" ;
VAL_ 2331595856 BMS_Range_Indikator 2042 "Funktion_nicht_vorhanden" 2043 "kleiner_0" 2044 "groesser_100" 2045 "nicht_angelernt" 2046 "Init" 2047 "Fehler" ;
VAL_ 397 BMS_MV_IstStrom 4094 "Init" 4095 "Fehler" ;
VAL_ 397 BMS_MV_IstSpannung 254 "Init" 255 "Fehler" ;
VAL_ 397 BMS_MV_IstSpannung_Zwkr 254 "Init" 255 "Fehler" ;
VAL_ 397 BMS_MV_SOC_HiRes 2046 "Init" 2047 "Fehler" ;
VAL_ 419 BMS_MV_MaxDyn_EntladeStrom 2046 "Init" 2047 "Fehler" ;
VAL_ 419 BMS_MV_MaxDyn_LadeStrom 2046 "Init" 2047 "Fehler" ;
VAL_ 419 BMS_MV_Min_EntladeSpannung 254 "Init" 255 "Fehler" ;
VAL_ 419 BMS_MV_MinDynEntladeSpannung 254 "Init" ;
VAL_ 419 BMS_MV_MinDyn_LadeSpannung 254 "Init" ;
VAL_ 2589283412 BMS_MV_Temperierung_Anf 0 "hoher_Kuehlbedarf" 1 "mittlerer_Kuehlbedarf" 2 "niedriger_Kuehlbedarf" 3 "kein_Temperierungsbedarf_Init" 4 "niedriger_Heizbedarf" 5 "mittlerer_Heizbedarf" 6 "hoher_Heizbedarf" 7 "Umwaelzungsbedarf" ;
VAL_ 2589283412 BMS_MV_Speichertechnologie 0 "Technologie_0" 1 "Technologie_1" 2 "Technologie_2" 3 "Technologie_3" 4 "Technologie_4" 5 "Technologie_5" 6 "Technologie_6" 7 "Technologie_unbekannt" ;
VAL_ 2589283412 BMS_MV_Soll_PWM_Pumpe 15 "Init" ;
VAL_ 2589283412 BMS_MV_Temperatur 254 "Init" 255 "Fehler" ;
VAL_ 2589283412 BMS_MV_IstVorlaufTemperatur 254 "Init" 255 "Fehler" ;
VAL_ 2589283412 BMS_MV_SollVolumenstrom 62 "Init" 63 "Fehler" ;
VAL_ 2589283412 BMS_MV_SollVorlauftemperatur 254 "Init" 255 "Fehler" ;
VAL_ 2589283412 BMS_MV_IstRuecklaufTemperatur 254 "Init" 255 "Fehler" ;
VAL_ 2589283608 BMS_MV_Energieinhalt 2046 "Init" 2047 "Fehler" ;
VAL_ 2589283608 BMS_MV_MaxEnergieinhalt 2046 "Init" 2047 "Fehler" ;
VAL_ 2589283606 BMS_MV_SOC_Kaltstart 2046 "Init" 2047 "Fehler" ;
VAL_ 2589283606 BMS_MV_max_Grenz_SOC 31 "Init" ;
VAL_ 1021 BMS_MV_SOHC_DiagStatus 0 "kein_Diagnosebedarf" 1 "Diagnosebedarf_niedrig" 2 "Diagnosebedarf_mittel" 3 "Diagnosebedarf_Zwang" 4 "Diagnosebedarf_Werkstatt" 5 "Diagnose_laeuft" 6 "Diagnoseabbruch" 7 "Diagnosefehler" ;
VAL_ 1021 BMS_MV_Pred_Entladeperformance 126 "Init" 127 "Fehler" ;
VAL_ 1021 BMS_MV_Pred_Ladeperformance 126 "Init" 127 "Fehler" ;
VAL_ 2463978716 BMS_MV_IstModus 0 "stStdBy" 1 "stMV" 5 "Error_Batt" 7 "stInit" ;
VAL_ 2463978716 BMS_MV_Leistungsreduzierung 0 "inaktiv" 1 "aktiv" ;
VAL_ 2463978716 BMS_MV_Fehler_Leistungsred 0 "Init" 1 "Leistungseinschraenkung" ;
VAL_ 2463978716 BMS_MV_Fehler_BattAbschaltung 0 "Init" 1 "Err_ShutOff" ;
VAL_ 2463978716 BMS_MV_Fehler_BattAbschaltungAnf 0 "Init" 1 "Err_ShutOffRequest" ;
VAL_ 2463978716 BMS_MV_Fehler_Kaltstartleistung 0 "Init" 1 "Kaltstartleistung_zu_gering" ;
VAL_ 2463978716 BMS_MV_Fehler_Notfallreserve 0 "Energiereserve_verfuegbar" 1 "reserved" 2 "Energiereserve_nicht_verfuegbar" 3 "Init" ;
VAL_ 2463978716 BMS_MV_Fehler_Relay_offen 0 "Init" 1 "Err_ContactorOpen" ;
VAL_ 2463978716 BMS_MV_Fehler_Relay_verschweisst 0 "Init" 1 "Err_ContactorWelding" ;
VAL_ 2463978716 BMS_MV_Peak_EntladeLeistung 2046 "Init" 2047 "Fehler" ;
VAL_ 2463978716 BMS_MV_Peak_LadeLeistung 2046 "Init" 2047 "Fehler" ;
VAL_ 2463978716 BMS_MV_Peak_EntladeSpannung 254 "Init" 255 "Fehler" ;
VAL_ 2463978716 BMS_MV_Peak_LadeSpannung 254 "Init" 255 "Fehler" ;
VAL_ 2463978717 BMS_MV_Strat_EntladeSpannung 254 "Init" 255 "Fehler" ;
VAL_ 2463978717 BMS_MV_PerfInd_Entladen 1022 "Init" 1023 "Fehler" ;
VAL_ 2463978717 BMS_MV_PerfInd_Laden 1022 "Init" 1023 "Fehler" ;
VAL_ 2463978717 BMS_MV_Max_EntladeLeistung 2046 "Init" 2047 "Fehler" ;
VAL_ 2463978717 BMS_MV_Max_LadeLeistung 2046 "Init" 2047 "Fehler" ;
VAL_ 2463978718 BMS_MV_Strat_LadeSpannung 254 "Init" 255 "Fehler" ;
VAL_ 2463978718 BMS_MV_Max_EntladeStrom_Lim 2046 "Init" 2047 "Fehler" ;
VAL_ 2463978718 BMS_MV_Max_LadeStrom_Lim 2046 "Init" 2047 "Fehler" ;
VAL_ 2463978718 BMS_MV_Min_EntladeSpannung_Lim 254 "Init" 255 "Fehler" ;
VAL_ 2463978718 BMS_MV_Max_LadeSpannung_Lim 254 "Init" 255 "Fehler" ;
VAL_ 2589283523 OBDProtocol_BMS_48V 0 "OBDonUDS" 1 "OBDclassic" 16 "NoOBD" 254 "Init" 255 "Fehler" ;
VAL_ 2589283523 BMS_MV_OBD_Lampe_Anf 0 "Init" 1 "MIL_Request" ;
VAL_ 2589283523 BMS_48V_Indc_StChk 0 "Complete" 1 "NotComplete" ;
VAL_ 2589283523 BMS_48V_Indc_StFail 0 "passiv" 1 "aktiv" ;
VAL_ 2589283523 BMS_MV_Kundenwarnung 0 "keine_Warnung" 1 "Warnung_Temperatur_Level1" 2 "Warnung_Temperatur_Level2" ;
VAL_ 2589283523 BMS_MV_Dauer_EntladeLeistung 2046 "Init" 2047 "Fehler" ;
VAL_ 2589283523 BMS_MV_Dauer_LadeLeistung 2046 "Init" 2047 "Fehler" ;
VAL_ 2589283523 BMS_MV_Dauer_EntladeSpannung 254 "Init" 255 "Fehler" ;
VAL_ 2589283523 BMS_MV_Dauer_LadeSpannung 254 "Init" 255 "Fehler" ;
VAL_ 2589283523 BMS_MV_Dauer_RMS_Strom 254 "Init" 255 "Fehler" ;
VAL_ 2589283524 BMS_MV_TRD_Voltage 0 "keine_Warnung" 1 "Warnung_TRD_Voltage" ;
VAL_ 2589283524 BMS_MV_TRD_Sensfail 0 "Keine_Warnung" 1 "Warnung_TRD_Sensfail" ;
VAL_ 2589283524 BMS_MV_TRD_Temp 0 "keine_Warnung" 1 "Warnung_TRD_Temp" ;
VAL_ 2589283524 BMS_MV_EntladeEnergie 2046 "Init" 2047 "Fehler" ;
VAL_ 2589283524 BMS_MV_LadeEnergie 2046 "Init" 2047 "Fehler" ;
VAL_ 2589283524 BMS_MV_Max_RMS_Strom 254 "Init" 255 "Fehler" ;
VAL_ 2527679928 BMS_NV_OBD_Lampe_Anf 0 "keine_Anforderung" 1 "Anforderung" ;
VAL_ 2527679928 BMS_NV_Indc_StChk 0 "Completed" 1 "NotCompleted" ;
VAL_ 2527679928 BMS_NV_Indc_StFail 0 "passiv_Init" 1 "aktiv" ;
VAL_ 2527679928 OBDProtocol_BMS_NV 0 "OBDonUDS" 1 "OBDclassic" 16 "NoOBD" 254 "Init" 255 "Fehler" ;
VAL_ 2463978646 CHA_Ziel_FahrPr_AGA 0 "keine_Funktion" 1 "Programm_1" 2 "Programm_2" 3 "Programm_3" 4 "Programm_4" 5 "Programm_5" 6 "Programm_6" 7 "Programm_7" 8 "Programm_8" 9 "Programm_9" 10 "Programm_10" 11 "Programm_11" 12 "Programm_12" 13 "Programm_13" 14 "Programm_14" 15 "Programm_15" ;
VAL_ 2463978646 CHA_Ziel_FahrPr_ESP 0 "keine_Funktion" 1 "Programm_1" 2 "Programm_2" 3 "Programm_3" 4 "Programm_4" 5 "Programm_5" 6 "Programm_6" 7 "Programm_7" 8 "Programm_8" 9 "Programm_9" 10 "Programm_10" 11 "Programm_11" 12 "Programm_12" 13 "Programm_13" 14 "Programm_14" 15 "Programm_15" ;
VAL_ 2463978646 CHA_Ziel_FahrPr_Freilauf 0 "keine_Funktion" 1 "Programm_1" 2 "Programm_2" 3 "Programm_3" 4 "Programm_4" 5 "Programm_5" 6 "Programm_6" 7 "Programm_7" 8 "Programm_8" 9 "Programm_9" 10 "Programm_10" 11 "Programm_11" 12 "Programm_12" 13 "Programm_13" 14 "Programm_14" 15 "Programm_15" ;
VAL_ 2463978646 CHA_Fahrer_Umschaltung 0 "keine_oder_automatische_Umschaltung" 1 "manuelle_Umschaltung" ;
VAL_ 2463978646 CHA_Fahrer_Umschaltung_BMA 0 "keine_oder_autom_Umschaltung" 1 "manuelle_Umschaltung" ;
VAL_ 2463978646 CHA_Ziel_FahrPr_MO 0 "keine_Funktion" 1 "Programm_1" 2 "Programm_2" 3 "Programm_3" 4 "Programm_4" 5 "Programm_5" 6 "Programm_6" 7 "Programm_7" 8 "Programm_8" 9 "Programm_9" 10 "Programm_10" 11 "Programm_11" 12 "Programm_12" 13 "Programm_13" 14 "Programm_14" 15 "Programm_15" ;
VAL_ 2463978646 CHA_Ziel_FahrPr_GE 0 "keine_Funktion" 1 "Programm_1" 2 "Programm_2" 3 "Programm_3" 4 "Programm_4" 5 "Programm_5" 6 "Programm_6" 7 "Programm_7" 8 "Programm_8" 9 "Programm_9" 10 "Programm_10" 11 "Programm_11" 12 "Programm_12" 13 "Programm_13" 14 "Programm_14" 15 "Programm_15" ;
VAL_ 2463978646 CHA_Ziel_FahrPr_ALR 0 "keine_Funktion" 1 "Programm_1" 2 "Programm_2" 3 "Programm_3" 4 "Programm_4" 5 "Programm_5" 6 "Programm_6" 7 "Programm_7" 8 "Programm_8" 9 "Programm_9" 10 "Programm_10" 11 "Programm_11" 12 "Programm_12" 13 "Programm_13" 14 "Programm_14" 15 "Programm_15" ;
VAL_ 2463978646 CHA_Ziel_FahrPr_MO_BZS 0 "keine_Funktion" 1 "Programm_1" 2 "Programm_2" 3 "Programm_3" 4 "Programm_4" 5 "Programm_5" 6 "Programm_6" 7 "Programm_7" 8 "Programm_8" 9 "Programm_9" 10 "Programm_10" 11 "Programm_11" 12 "Programm_12" 13 "Programm_13" 14 "Programm_14" 15 "Programm_15" ;
VAL_ 2463978646 CHA_Ziel_FahrPr_DR 0 "keine_Funktion" 1 "Programm_1" 2 "Programm_2" 3 "Programm_3" 4 "Programm_4" 5 "Programm_5" 6 "Programm_6" 7 "Programm_7" 8 "Programm_8" 9 "Programm_9" 10 "Programm_10" 11 "Programm_11" 12 "Programm_12" 13 "Programm_13" 14 "Programm_14" 15 "Programm_15" ;
VAL_ 2463978646 CHA_Ziel_FahrPr_VAQ 0 "keine_Funktion" 1 "Programm_1" 2 "Programm_2" 3 "Programm_3" 4 "Programm_4" 5 "Programm_5" 6 "Programm_6" 7 "Programm_7" 8 "Programm_8" 9 "Programm_9" 10 "Programm_10" 11 "Programm_11" 12 "Programm_12" 13 "Programm_13" 14 "Programm_14" 15 "Programm_15" ;
VAL_ 2463978646 CHA_Ziel_FahrPr_AFS 0 "keine_Funktion" 1 "Programm_1" 2 "Programm_2" 3 "Programm_3" 4 "Programm_4" 5 "Programm_5" 6 "Programm_6" 7 "Programm_7" 8 "Programm_8" 9 "Programm_9" 10 "Programm_10" 11 "Programm_11" 12 "Programm_12" 13 "Programm_13" 14 "Programm_14" 15 "Programm_15" ;
VAL_ 2463978646 CHA_Ziel_FahrPr_PreCrash 0 "keine_Funktion" 1 "Programm_1" 2 "Programm_2" 3 "Programm_3" 4 "Programm_4" 5 "Programm_5" 6 "Programm_6" 7 "Programm_7" 8 "Programm_8" 9 "Programm_9" 10 "Programm_10" 11 "Programm_11" 12 "Programm_12" 13 "Programm_13" 14 "Programm_14" 15 "Programm_15" ;
VAL_ 2463978646 CHA_Ziel_FahrPr_EPS 0 "keine_Funktion" 1 "Programm_1" 2 "Programm_2" 3 "Programm_3" 4 "Programm_4" 5 "Programm_5" 6 "Programm_6" 7 "Programm_7" 8 "Programm_8" 9 "Programm_9" 10 "Programm_10" 11 "Programm_11" 12 "Programm_12" 13 "Programm_13" 14 "Programm_14" 15 "Programm_15" ;
VAL_ 2463978646 CHA_Ziel_FahrPr_ACC 0 "keine_Funktion" 1 "Programm_1" 2 "Programm_2" 3 "Programm_3" 4 "Programm_4" 5 "Programm_5" 6 "Programm_6" 7 "Programm_7" 8 "Programm_8" 9 "Programm_9" 10 "Programm_10" 11 "Programm_11" 12 "Programm_12" 13 "Programm_13" 14 "Programm_14" 15 "Programm_15" ;
VAL_ 2463978646 CHA_Ziel_FahrPr_SAK 0 "keine_Funktion" 1 "Programm_1" 2 "Programm_2" 3 "Programm_3" 4 "Programm_4" 5 "Programm_5" 6 "Programm_6" 7 "Programm_7" 8 "Programm_8" 9 "Programm_9" 10 "Programm_10" 11 "Programm_11" 12 "Programm_12" 13 "Programm_13" 14 "Programm_14" 15 "Programm_15" ;
VAL_ 2463978646 CHA_Ziel_FahrPr_MO_StSt 0 "keine_Funktion" 1 "Programm_1" 2 "Programm_2" 3 "Programm_3" 4 "Programm_4" 5 "Programm_5" 6 "Programm_6" 7 "Programm_7" 8 "Programm_8" 9 "Programm_9" 10 "Programm_10" 11 "Programm_11" 12 "Programm_12" 13 "Programm_13" 14 "Programm_14" 15 "Programm_15" ;
VAL_ 2463978646 CHA_Ziel_FahrPr_EBKV 0 "keine_Funktion" 1 "Programm_1" 2 "Programm_2" 3 "Programm_3" 4 "Programm_4" 5 "Programm_5" 6 "Programm_6" 7 "Programm_7" 8 "Programm_8" 9 "Programm_9" 10 "Programm_10" 11 "Programm_11" 12 "Programm_12" 13 "Programm_13" 14 "Programm_14" 15 "Programm_15" ;
VAL_ 2463978646 CHA_Ziel_FahrPr_IL 0 "keine_Funktion" 1 "Programm_1" 2 "Programm_2" 3 "Programm_3" 4 "Programm_4" 5 "Programm_5" 6 "Programm_6" 7 "Programm_7" 8 "Programm_8" 9 "Programm_9" 10 "Programm_10" 11 "Programm_11" 12 "Programm_12" 13 "Programm_13" 14 "Programm_14" 15 "Programm_15" ;
VAL_ 2463978646 CHA_Current_Mode 0 "keine_Funktion" 1 "Programm_1" 2 "Programm_2" 3 "Programm_3" 4 "Programm_4" 5 "Programm_5" 6 "Programm_6" 7 "Programm_7" 8 "Programm_8" 9 "Programm_9" 10 "Programm_10" 11 "Programm_11" 12 "Programm_12" 13 "Programm_13" 14 "Programm_14" 15 "Programm_15" ;
VAL_ 2463978646 CHA_Ziel_FahrPr_QS 0 "keine_Funktion" 1 "Programm_1" 2 "Programm_2" 3 "Programm_3" 4 "Programm_4" 5 "Programm_5" 6 "Programm_6" 7 "Programm_7" 8 "Programm_8" 9 "Programm_9" 10 "Programm_10" 11 "Programm_11" 12 "Programm_12" 13 "Programm_13" 14 "Programm_14" 15 "Programm_15" ;
VAL_ 2463978646 CHA_Ziel_FahrPr_SCU 0 "keine_Funktion" 1 "Programm_1" 2 "Programm_2" 3 "Programm_3" 4 "Programm_4" 5 "Programm_5" 6 "Programm_6" 7 "Programm_7" 8 "Programm_8" 9 "Programm_9" 10 "Programm_10" 11 "Programm_11" 12 "Programm_12" 13 "Programm_13" 14 "Programm_14" 15 "Programm_15" ;
VAL_ 2463978646 CHA_Ziel_FahrPr_HAL 0 "keine_Funktion" 1 "Programm_1" 2 "Programm_2" 3 "Programm_3" 4 "Programm_4" 5 "Programm_5" 6 "Programm_6" 7 "Programm_7" 8 "Programm_8" 9 "Programm_9" 10 "Programm_10" 11 "Programm_11" 12 "Programm_12" 13 "Programm_13" 14 "Programm_14" 15 "Programm_15" ;
VAL_ 2463978646 CHA_Ziel_FahrPr_NR 0 "keine_Funktion" 1 "Programm_1" 2 "Programm_2" 3 "Programm_3" 4 "Programm_4" 5 "Programm_5" 6 "Programm_6" 7 "Programm_7" 8 "Programm_8" 9 "Programm_9" 10 "Programm_10" 11 "Programm_11" 12 "Programm_12" 13 "Programm_13" 14 "Programm_14" 15 "Programm_15" ;
VAL_ 2463978646 CHA_Ziel_FahrPr_AV 0 "keine_Funktion" 1 "Programm_1" 2 "Programm_2" 3 "Programm_3" 4 "Programm_4" 5 "Programm_5" 6 "Programm_6" 7 "Programm_7" 8 "Programm_8" 9 "Programm_9" 10 "Programm_10" 11 "Programm_11" 12 "Programm_12" 13 "Programm_13" 14 "Programm_14" 15 "Programm_15" ;
VAL_ 2463978646 CHA_Ziel_FahrPr_MXB 0 "keine_Funktion" 1 "Programm_1" 2 "Programm_2" 3 "Programm_3" 4 "Programm_4" 5 "Programm_5" 6 "Programm_6" 7 "Programm_7" 8 "Programm_8" 9 "Programm_9" 10 "Programm_10" 11 "Programm_11" 12 "Programm_12" 13 "Programm_13" 14 "Programm_14" 15 "Programm_15" ;
VAL_ 2463978646 CHA_Ziel_FahrPr_AFR 0 "keine_Funktion" 1 "Programm_1" 2 "Programm_2" 3 "Programm_3" 4 "Programm_4" 5 "Programm_5" 6 "Programm_6" 7 "Programm_7" 8 "Programm_8" 9 "Programm_9" 10 "Programm_10" 11 "Programm_11" 12 "Programm_12" 13 "Programm_13" 14 "Programm_14" 15 "Programm_15" ;
VAL_ 2463978646 CHA_Ziel_FahrPr_HDC 0 "keine_Funktion" 1 "Programm_1" 2 "Programm_2" 3 "Programm_3" 4 "Programm_4" 5 "Programm_5" 6 "Programm_6" 7 "Programm_7" 8 "Programm_8" 9 "Programm_9" 10 "Programm_10" 11 "Programm_11" 12 "Programm_12" 13 "Programm_13" 14 "Programm_14" 15 "Programm_15" ;
VAL_ 2463978646 CHA_Ziel_FahrPr_EAR 0 "keine_Funktion" 1 "Programm_1" 2 "Programm_2" 3 "Programm_3" 4 "Programm_4" 5 "Programm_5" 6 "Programm_6" 7 "Programm_7" 8 "Programm_8" 9 "Programm_9" 10 "Programm_10" 11 "Programm_11" 12 "Programm_12" 13 "Programm_13" 14 "Programm_14" 15 "Programm_15" ;
VAL_ 2463978646 CHA_Ziel_FahrPr_AEB 0 "keine_Funktion" 1 "Programm_1" 2 "Programm_2" 3 "Programm_3" 4 "Programm_4" 5 "Programm_5" 6 "Programm_6" 7 "Programm_7" 8 "Programm_8" 9 "Programm_9" 10 "Programm_10" 11 "Programm_11" 12 "Programm_12" 13 "Programm_13" 14 "Programm_14" 15 "Programm_15" ;
VAL_ 2463978646 CHA_Ziel_FahrPr_FCWO 0 "keine_Funktion" 1 "Programm_1" 2 "Programm_2" 3 "Programm_3" 4 "Programm_4" 5 "Programm_5" 6 "Programm_6" 7 "Programm_7" 8 "Programm_8" 9 "Programm_9" 10 "Programm_10" 11 "Programm_11" 12 "Programm_12" 13 "Programm_13" 14 "Programm_14" 15 "Programm_15" ;
VAL_ 2463978646 CHA_Ziel_FahrPr_FCWP 0 "keine_Funktion" 1 "Programm_1" 2 "Programm_2" 3 "Programm_3" 4 "Programm_4" 5 "Programm_5" 6 "Programm_6" 7 "Programm_7" 8 "Programm_8" 9 "Programm_9" 10 "Programm_10" 11 "Programm_11" 12 "Programm_12" 13 "Programm_13" 14 "Programm_14" 15 "Programm_15" ;
VAL_ 2463978646 CHA_Ziel_FahrPr_eSound 0 "keine_Funktion" 1 "Programm_1" 2 "Programm_2" 3 "Programm_3" 4 "Programm_4" 5 "Programm_5" 6 "Programm_6" 7 "Programm_7" 8 "Programm_8" 9 "Programm_9" 10 "Programm_10" 11 "Programm_11" 12 "Programm_12" 13 "Programm_13" 14 "Programm_14" 15 "Programm_15" ;
VAL_ 2463978646 CHA_Ziel_FahrPr_RHP 0 "keine_Funktion" 1 "Programm_1" 2 "Programm_2" 3 "Programm_3" 4 "Programm_4" 5 "Programm_5" 6 "Programm_6" 7 "Programm_7" 8 "Programm_8" 9 "Programm_9" 10 "Programm_10" 11 "Programm_11" 12 "Programm_12" 13 "Programm_13" 14 "Programm_14" 15 "Programm_15" ;
VAL_ 2463978646 CHA_Ziel_FahrPr_ToS_laengs 0 "keine_Funktion" 1 "Programm_1" 2 "Programm_2" 3 "Programm_3" 4 "Programm_4" 5 "Programm_5" 6 "Programm_6" 7 "Programm_7" 8 "Programm_8" 9 "Programm_9" 10 "Programm_10" 11 "Programm_11" 12 "Programm_12" 13 "Programm_13" 14 "Programm_14" 15 "Programm_15" ;
VAL_ 2463978646 CHA_Ziel_FahrPr_ToS_quer 0 "keine_Funktion" 1 "Programm_1" 2 "Programm_2" 3 "Programm_3" 4 "Programm_4" 5 "Programm_5" 6 "Programm_6" 7 "Programm_7" 8 "Programm_8" 9 "Programm_9" 10 "Programm_10" 11 "Programm_11" 12 "Programm_12" 13 "Programm_13" 14 "Programm_14" 15 "Programm_15" ;
VAL_ 2463978646 CHA_Ziel_FahrPr_mFDR 0 "keine_Funktion" 1 "Programm_1" 2 "Programm_2" 3 "Programm_3" 4 "Programm_4" 5 "Programm_5" 6 "Programm_6" 7 "Programm_7" 8 "Programm_8" 9 "Programm_9" 10 "Programm_10" 11 "Programm_11" 12 "Programm_12" 13 "Programm_13" 14 "Programm_14" 15 "Programm_15" ;
VAL_ 2463978646 CHA_Ziel_FahrPr_Reku_ZwGas 0 "kein_Funktion" 1 "Programm_1" 2 "Programm_2" 3 "Programm_3" 4 "Programm_4" 5 "Programm_5" 6 "Programm_6" 7 "Programm_7" 8 "Programm_8" 9 "Programm_9" 10 "Programm_10" 11 "Programm_11" 12 "Programm_12" 13 "Programm_13" 14 "Programm_14" 15 "Programm_15" ;
VAL_ 2463978646 CHA_Ziel_FahrPr_MO_Freilauf 0 "keine_Funktion" 1 "Programm_1" 2 "Programm_2" 3 "Programm_3" 4 "Programm_4" 5 "Programm_5" 6 "Programm_6" 7 "Programm_7" 8 "Programm_8" 9 "Programm_9" 10 "Programm_10" 11 "Programm_11" 12 "Programm_12" 13 "Programm_13" 14 "Programm_14" 15 "Programm_15" ;
VAL_ 2463978646 CHA_Ziel_FahrPr_BMS 0 "keine_Funktion" 1 "Programm_1" 2 "Programm_2" 3 "Programm_3" 4 "Programm_4" 5 "Programm_5" 6 "Programm_6" 7 "Programm_7" 8 "Programm_8" 9 "Programm_9" 10 "Programm_10" 11 "Programm_11" 12 "Programm_12" 13 "Programm_13" 14 "Programm_14" 15 "Programm_15" ;
VAL_ 2463978646 CHA_Ziel_FahrPr_PDC 0 "keine_Funktion" 1 "Programm_1" 2 "Programm_2" 3 "Programm_3" 4 "Programm_4" 5 "Programm_5" 6 "Programm_6" 7 "Programm_7" 8 "Programm_8" 9 "Programm_9" 10 "Programm_10" 11 "Programm_11" 12 "Programm_12" 13 "Programm_13" 14 "Programm_14" 15 "Programm_15" ;
VAL_ 2463978646 CHA_Ziel_FahrPr_HHC 0 "keine_Funktion" 1 "Programm_1" 2 "Programm_2" 3 "Programm_3" 4 "Programm_4" 5 "Programm_5" 6 "Programm_6" 7 "Programm_7" 8 "Programm_8" 9 "Programm_9" 10 "Programm_10" 11 "Programm_11" 12 "Programm_12" 13 "Programm_13" 14 "Programm_14" 15 "Programm_15" ;
VAL_ 2463978646 CHA_Ziel_FahrPr_EDS 0 "keine_Funktion" 1 "Programm_1" 2 "Programm_2" 3 "Programm_3" 4 "Programm_4" 5 "Programm_5" 6 "Programm_6" 7 "Programm_7" 8 "Programm_8" 9 "Programm_9" 10 "Programm_10" 11 "Programm_11" 12 "Programm_12" 13 "Programm_13" 14 "Programm_14" 15 "Programm_15" ;
VAL_ 2463978646 CHA_Ziel_FahrPr_PACC 0 "keine_Funktion" 1 "Programm_1" 2 "Programm_2" 3 "Programm_3" 4 "Programm_4" 5 "Programm_5" 6 "Programm_6" 7 "Programm_7" 8 "Programm_8" 9 "Programm_9" 10 "Programm_10" 11 "Programm_11" 12 "Programm_12" 13 "Programm_13" 14 "Programm_14" 15 "Programm_15" ;
VAL_ 2463978646 CHA_Ziel_FahrPr_AGK 0 "keine_Funktion" 1 "Programm_1" 2 "Programm_2" 3 "Programm_3" 4 "Programm_4" 5 "Programm_5" 6 "Programm_6" 7 "Programm_7" 8 "Programm_8" 9 "Programm_9" 10 "Programm_10" 11 "Programm_11" 12 "Programm_12" 13 "Programm_13" 14 "Programm_14" 15 "Programm_15" ;
VAL_ 1485 DC_Temperatur_Alarm 0 "kein_Fehler" 1 "Fehler" ;
VAL_ 1485 DCDC_NV_Indc_StChk 0 "Completed" 1 "NotCompleted" ;
VAL_ 1485 DC_Kl30c_Status 0 "Init" 1 "geschlossen" 2 "offen" 3 "Fehler" ;
VAL_ 1485 DC_Fehlerstatus 0 "Komponente_IO" 1 "Eingeschr_KompFkt_Entlad_defekt" 3 "Eingeschr_KompFkt_Interlock" 4 "Eingeschr_KompFkt_SD" 6 "Keine_Komponentenfunktion" 7 "Init" ;
VAL_ 1485 DC_Peakstrom_verfuegbar 0 "Peakstrom_nicht_verfuegbar" 1 "Peakstrom_verfuegbar" ;
VAL_ 1485 DC_Abregelung_Temperatur 0 "keine_Abregelung" 1 "Abregelung_Temp" ;
VAL_ 1485 DC_Derating 0 "keine_Abregelung" 1 "Abregelung_Ursache_NV" 2 "Abregelung_Ursache_HV" 3 "Abregelung_Ursache_Temp" 4 "Abregelung_Ursache_Intern" ;
VAL_ 1485 DC_OBD_Lampe_Anf 0 "kein_MIL_Request" 1 "MIL_Request" ;
VAL_ 1485 DCDC_NV_Indc_StFail 0 "passiv" 1 "aktiv" ;
VAL_ 1485 DC_Warnlampe_Anf 0 "keine_Anforderung_Warnlampe" 1 "Anforderung_Warnlampe" ;
VAL_ 1485 OBDProtocol_DCDC_NV 0 "OBDonUDS" 1 "OBDclassic" 16 "NoOBD" 254 "Init" 255 "Fehler" ;
VAL_ 1485 DC_SollVolumenstrom 62 "Init" 63 "Fehler" ;
VAL_ 1485 DC_Status_Spgfreiheit_HV 0 "Init" 1 "HV_Komponente_spannungsfrei" 2 "HV_Komp_nicht_spannungsfrei" 3 "Fehler" ;
VAL_ 1485 DC_Temperatur 254 "Init" 255 "Fehler" ;
VAL_ 247 DC_Vorladung_Status 0 "nicht_abgeschlossen" 1 "abgeschlossen" ;
VAL_ 247 DC_Fehler_extern 0 "kein_Fehler" 1 "Fehler" ;
VAL_ 247 DC_Fehler_intern 0 "kein_Fehler" 1 "interner_Fehler_erkannt" ;
VAL_ 247 DC_Status_Spgfreiheit 0 "Init" 1 "HV_Komponente_spannungsfrei" 2 "HV_Komp_nicht_spannungsfrei" 3 "Fehler_nicht_spannungsfrei" ;
VAL_ 247 DC_Status_EoHVL 0 "Init" 1 "Keine_offene_HV_Leitung_erkannt" 2 "offene_HV_Leitung_erkannt" 3 "Fehler" ;
VAL_ 247 DC_IstModus_02 0 "Standby" 1 "HV_On_Vorladen" 2 "Tiefsetzen" 3 "Hochsetzen" 4 "Pruefimpuls_12V" 5 "Fehler" 7 "Initialisierung" ;
VAL_ 247 DC_IstStrom_HV 1022 "Init" 1023 "Fehler" ;
VAL_ 247 DC_IstLeistung_HV 1022 "Init" 1023 "Fehler" ;
VAL_ 1484 DCDC_MV_Peakstrom_verfuegbar 0 "Peakstrom_nicht_verfuegbar" 1 "Peakstrom_verfuegbar" ;
VAL_ 1484 DC_MV_Tiefsetzen_Notbetrieb 0 "Init" 1 "aktiv" ;
VAL_ 1484 DC_MV_Fehlerstatus 0 "Komponente_IO" 3 "Vorwarnung_KompFkt" 5 "Eingeschr_KompFkt_Leistungsred" 6 "Keine_Komponentenfunktion" 7 "Init" ;
VAL_ 1484 DC_MV_12V_Bordnetzstuetzung 0 "Init" 1 "aktiv" ;
VAL_ 1484 DC_MV_Abregelung_Temperatur 0 "keine_Abregelung" 1 "Abregelung_Temp" ;
VAL_ 1484 DC_MV_IstModus_02 0 "Standby" 1 "MV_On" 2 "Tiefsetzen" 3 "Hochsetzen" 4 "Startunterstuetzung_48V" 5 "Fehler" 6 "Startunterstuetzung_12V" 7 "Init" 9 "MV_On_Notbetrieb" 10 "Tiefsetzen_Notbetrieb" 11 "Pruefpuls_12V" 13 "Reaktivierung_BMS" ;
VAL_ 1484 DC_MV_Derating 0 "keine_Abregelung" 1 "Abregelung_Ursache_NV" 2 "Abregelung_Ursache_MV" 3 "Abregelung_Ursache_Temp" 4 "Abregelung_Ursache_Intern" ;
VAL_ 1484 DC_MV_Temperatur 254 "Init" 255 "Fehler" ;
VAL_ 1714 DGN_Verlernzaehler 255 "ungültiger Zählerstand oder kein gültiger Fahrzyklus" ;
VAL_ 1714 KBI_Kilometerstand 1048574 "Init" 1048575 "Fehler" ;
VAL_ 1714 UH_Monat 0 "Init" 14 "Relatives_Datum" 15 "Fehler" ;
VAL_ 1714 UH_Tag 0 "Init" ;
VAL_ 1714 Vehicle_Driving_Cycle 0 "kein_Driving_Cycle_erkannt" 1 "Driving_Cycle_erkannt" ;
VAL_ 1714 Kombi_02_alt 0 "aktuell" 1 "veraltet" ;
VAL_ 1714 Uhrzeit_01_alt 0 "aktuell" 1 "veraltet" ;
VAL_ 1520 DI_KL_58xd 254 "Init" 255 "Fehler" ;
VAL_ 1520 DI_KL_58xs 126 "Init" 127 "Fehler" ;
VAL_ 1520 DI_KL_58xt 126 "Init" 127 "Fehler" ;
VAL_ 1520 BCM1_Stellgroesse_Kl_58s 125 "Nicht_verbaut" 126 "Init" 127 "Fehler" ;
VAL_ 420 EA_Parken_beibehalten_HMS 0 "Parken_nicht_beibehalten" 1 "Parken_beibehalten" 2 "Init" 3 "Fehler" ;
VAL_ 420 EA_Ruckstaerke 0 "Keine_Anforderung" 1 "Schwach" 2 "Mittel" 3 "Stark" ;
VAL_ 420 EA_Warnruckprofil 0 "keine_Ruckanforderung" 1 "Profil_1" 2 "Profil_2" 3 "Profil_3" 4 "Profil_4" 5 "Profil_5" 6 "Profil_6" 7 "Profil_7" ;
VAL_ 420 EA_PreCrash_Anf 0 "keine_Anforderung" 1 "Aktionsgenerierte_Warnung_1" 2 "Aktionsgenerierte_Warnung_2" 3 "Aktionsgenerierte_Warnung_3" 4 "Aktionsgenerierte_Warnung_4" 5 "Aktionsgenerierte_Warnung_5" 6 "Aktionsgenerierte_Warnung_6" 7 "Aktionsgenerierte_Warnung_7" ;
VAL_ 420 EA_aktiv_laengs 0 "nicht_aktiv" 1 "aktiv_Vorstufe" 2 "aktiv_Hauptstufe" ;
VAL_ 420 EA_Funktionsstatus 0 "EA_INIT" 1 "EA_OFF" 2 "EA_STANDBY" 3 "EA_PHASE0_AKTIV" 4 "EA_PHASE1_AKTIV" 5 "EA_PHASE2_AKTIV" 6 "EA_PHASE3_AKTIV" 7 "EA_REVERSIBLER_FEHLER" 8 "EA_IRREVERSIBLER_FEHLER" ;
VAL_ 420 EA_Gurtstraffer_Anf 0 "Keine_Anforderung" 1 "Haptik_1" 2 "Haptik_2" 3 "Haptik_3" ;
VAL_ 420 EA_Anf_Prefill 0 "Prefill_nicht_aktivieren" 1 "Prefill_aktivieren" ;
VAL_ 420 EA_Anforderung_HMS 0 "keine_Anforderung" 1 "halten" 2 "parken" 3 "halten_Standby" 4 "anfahren" 5 "Loesen_ueber_Rampe" 6 "Parken_mit_P" ;
VAL_ 420 EA_Ruckfreigabe 0 "keine_Freigabe" 1 "Freigabe" ;
VAL_ 420 EA_01_Sendestatus 0 "EA_01_im_langsamen_Zyklus" 1 "EA_01_im_schnellen_Zyklus" ;
VAL_ 420 EA_Sollbeschleunigung 2046 "Neutralwert" 2047 "Fehler" ;
VAL_ 374 EBKV_Activate_Fallback_ESP 0 "Rueckfallebene_nicht_aktiv" 1 "Rueckfallebene_aktiv" ;
VAL_ 374 EBKV_Restdruckabsenkung 0 "RPR_Passive" 1 "RPR_Preload" 2 "RPR_Hold" 3 "RPR_Suction" 4 "RPR_HoldLowPressure" 5 "RPR_Abort" ;
VAL_ 374 EBKV_Status_02 0 "EBKV_nicht_initialisiert" 1 "EBKV_Fehler_Zustand_aus" 2 "EBKV_Diagnose" 3 "EBKV_nicht_belegt" 4 "EBKV_Standalone" 5 "EBKV_degradiert" 6 "EBKV_Nachlauf_degradiert" 7 "EBKV_bereit" 8 "EBKV_Ausfall_Rekukomponente" 9 "EBKV_Shutdown" 10 "EBKV_nicht_belegt" 11 "EBKV_nicht_belegt" 12 "EBKV_nicht_belegt" 13 "EBKV_nicht_belegt" 14 "EBKV_nicht_belegt" 15 "EBKV_nicht_belegt" ;
VAL_ 374 EBKV_Diagnose 0 "Diagnose_inaktiv" 1 "Diagnose_aktiv" ;
VAL_ 374 EBKV_Fahrer_bremst 0 "Fahrer_bremst_nicht_selbst" 1 "Fahrer_will_selbst_bremsen" ;
VAL_ 374 EBKV_QBit_Fahrer_bremst 0 "gueltiger_Wert" 1 "Ersatz_Init_oder_Fehlerwert" ;
VAL_ 374 EBKV_Fahrer_bremst_deutlich 0 "Fahrer_uebertritt_Schwelle_nicht" 1 "Fahrer_uebertritt_Schwelle" ;
VAL_ 374 EBKV_OBD_Status 0 "MIL_aus" 1 "MIL_ein" ;
VAL_ 374 EBKV_VMM_Sek_Notstopp_Status 0 "Init" 1 "Verfuegbar" 2 "Passiv_Ueberwachung" 3 "Aktiv_Ausgeloest" 4 "Systemkomponente_Defekt" ;
VAL_ 374 EBKV_Anforderung_HMS 0 "keine_Anforderung" 1 "halten" 2 "parken" 3 "halten_Standby" 4 "anfahren" 5 "Loesen_ueber_Rampe" 7 "HMS_uebernehmen" ;
VAL_ 374 SBS_Anforderung_GE 0 "keine_Anforderung" 1 "P_einlegen" ;
VAL_ 374 EPB_Status_ext 0 "offen" 1 "geschlossen_Parken" 2 "teilgespannt_Halten" 3 "im_Lauf_oeffnen" 4 "im_Lauf_schliessen" 5 "tbd" 6 "Init" 7 "unbekannt" ;
VAL_ 374 EBKV_Textanzeigen 0 "keine_Anzeige" 1 "nicht_gegen_verrollen_gesichert" 2 "Reduktion_Bremskraftverstaerkung" 3 "nicht_belegt" ;
VAL_ 374 EBKV_Bremspedalweg 0 "Init" 255 "Fehler" ;
VAL_ 374 EBKV_Kraftblending_Reserve 254 "Init" 255 "Fehler" ;
VAL_ 374 EBKV_Aussteuerdruck 251 "Aussteuerdruck_VKM_Start" 252 "Aussteuerdruck_Nachlauf_Phase1" 253 "Aussteuerdruck_Nachlauf_Phase2" 254 "Init" 255 "Fehler" ;
VAL_ 2589283963 EBKV_OBD_Status_Auth 0 "MIL_aus" 1 "MIL_ein" ;
VAL_ 2589283963 EBKV_Indc_StChk 0 "Completed" 1 "NotCompleted" ;
VAL_ 2589283963 EBKV_Indc_StFail 0 "passiv" 1 "aktiv" ;
VAL_ 2589283963 OBDProtocol_EBKV 0 "OBDonUDS" 1 "OBDclassic" 16 "NoOBD" 254 "Init" 255 "Fehler" ;
VAL_ 1603 KBI_Einheit_Datum 0 "Tag/Monat/Jahr" 1 "Monat/Tag/Jahr" 2 "Jahr/Monat/Tag" 3 "reserviert" ;
VAL_ 1603 KBI_Einheit_Druck 0 "Druckangabe in bar" 1 "Druckangabe in psi" 2 "Druckangabe in kPa" 3 "tbd." ;
VAL_ 1603 KBI_Einheit_Streckenanz 0 "Kilometer" 1 "Meilen" ;
VAL_ 1603 KBI_MFA_v_Einheit_02 0 "kmh" 1 "mph" ;
VAL_ 1603 KBI_Einheit_Temp 0 "Grad Celsius °C" 1 "Grad Fahrenheit °F" ;
VAL_ 1603 KBI_Einheit_Uhrzeit 0 "24h" 1 " 12h AM/PM" ;
VAL_ 1603 KBI_Einheit_Verbrauch 0 "mpg UK" 1 "mpg USA" 2 "Liter/100km" 3 "km/Liter" ;
VAL_ 1603 KBI_Einheit_Volumen 0 "Liter" 1 "Gallonen UK" 2 "Gallonen USA" 3 "reserviert" ;
VAL_ 1603 KBI_Einheit_Verbrauch_elektr 0 "kWh_pro_100km" 1 "km_pro_kWh" 2 "kWh_pro_100mls" 3 "mls_pro_kWh" 4 "MPGe" ;
VAL_ 1603 KBI_Einheit_Tacho 0 "km/h" 1 "mph" ;
VAL_ 1603 KBI_Einheit_Verbrauch_Gas 0 "kg_per_100km" 1 "km_per_kg" 2 "m3_per_100km" 3 "km_per_m3" 4 "miles_per_lbs" 5 "miles_per_yard3" 6 "miles_per_kg" 7 "miles_per_m3" 8 "miles_per_gallon_equivalent_US" ;
VAL_ 1603 KBI_Einheit_Masse 0 "kg" 1 "lbs" 2 "reserviert" ;
VAL_ 192 EM1_Istmodus 0 "Standby" 1 "Momentenreg" 2 "Int_Drehzahlreg" 3 "Spannungsreg" 4 "Ext_Drehzahlreg" 5 "Inverter_Fehler" 6 "Kalibrierung" 7 "Sonderbremsbetrieb" 8 "Freilauf" 9 "Autonome_Synchronisation" 15 "Initialisierung" ;
VAL_ 192 EM1_IstMoment 4094 "Init" 4095 "Fehler" ;
VAL_ 192 EM1_Moment_AR_Eingriff 4094 "Init" 4095 "Fehler" ;
VAL_ 192 EM1_IstDrehzahl 32766 "Init" 32767 "Fehler" ;
VAL_ 192 EM1_AR_aktiv 0 "Init" 1 "Ruckeldaempfer_aktiv" ;
VAL_ 192 EM1_IstSpannung 4094 "Init" 4095 "Fehler" ;
VAL_ 192 EM1_Strom_HV 4094 "Init" 4095 "Fehler" ;
VAL_ 192 EM1_Max_Moment 2046 "Init" 2047 "Fehler" ;
VAL_ 192 EM1_ErwGrenzen_aktiv 0 "kein_extended_Range" 1 "extended_Range" ;
VAL_ 192 EM1_Min_Moment 2046 "Init" 2047 "Fehler" ;
VAL_ 192 EM1_Fehler_ElAntriebAbschaltung 0 "Init" 1 "Abschaltung" ;
VAL_ 192 EM1_Max_Moment_Lim 2046 "Init" 2047 "Fehler" ;
VAL_ 192 EM1_Fehler_Notabschaltung 0 "kein_Fehler" 1 "Fehler" ;
VAL_ 192 EM1_Min_Moment_Lim 2046 "Init" 2047 "Fehler" ;
VAL_ 192 EM1_Status_DrzEingriff 0 "kein_Eingriff" 1 "Eingriff_Max_Drehzahlregler" 2 "Eingriff_Min_Drehzahlregler" 3 "Fehler" ;
VAL_ 192 EM1_Mom_DrzEingriff 2046 "Init" 2047 "Fehler" ;
VAL_ 192 EM1_Raddrehzahl_links 8188 "reserviert" 8189 "reserviert" 8190 "Init" 8191 "Fehler" ;
VAL_ 192 EM1_Raddrehzahl_rechts 8188 "reserviert" 8189 "reserviert" 8190 "Init" 8191 "Fehler" ;
VAL_ 192 EM1_Max_Moment_Gesamt 2046 "Init" 2047 "Fehler" ;
VAL_ 192 EM1_Min_Moment_Gesamt 2046 "Init" 2047 "Fehler" ;
VAL_ 184 EM1_Freigabe_Info_WFS 0 "ungueltig" 1 "gueltig" ;
VAL_ 184 EM1_Sperr_Info_WFS 0 "nicht_gesperrt" 1 "gesperrt" ;
VAL_ 184 EM1_AR_aktiv 0 "Init" 1 "Ruckeldaempfer_aktiv" ;
VAL_ 184 EM1_Eta_Sys 510 "Init" 511 "Fehler" ;
VAL_ 184 EM1_IstStrom 2046 "Init" 2047 "Fehler" ;
VAL_ 184 EM1_Fehler_ElAntriebFreilauf_Anf 0 "Init" 1 "Fehler_EM_im_Freilauf" ;
VAL_ 184 EM1_Abregelung_Temperatur 0 "Init" 1 "Abregelung_Temperatur" ;
VAL_ 184 EM1_AnlernenElMotor_Anf 0 "kein_Diagnose_Request" 1 "Diagnose_Request" ;
VAL_ 184 EM1_Moment_HVVerbraucher 1023 "Init" ;
VAL_ 184 LE_Kuehlmittel_Sensor 0 "OK" 1 "Kuehlmittel_unter_min" ;
VAL_ 184 EM1_Freigabe_Verfallsinfo_WFS 0 "Aus" 1 "Ein" ;
VAL_ 184 EM1_Parken_WFS_Status 0 "Limitierung_Inaktiv" 1 "Limitierung_Aktiv" 2 "Abbruch" ;
VAL_ 184 EM1_HV_betriebsbereit 0 "Init" 1 "Ready_HV" ;
